VERSION "created by canmatrix"

NS_ :

BS_:

BU_: DiagTool_OBD1 DiwaNXT EBS IRCS MulticII NBM VCM ETS NODE_45 FCCU DICO SGW2 HV_BOX ADCU AEBS DTCO MBMS SGW TPMS ACU CAID2 ELC5_Fr ELC5_Rr PredictiveVirtualNode2 BPU_3 Servo_dir_Turolla PCM NODE_90 NODE_91 NODE_92 RSRRM FCU DSE_VirtualNode2 DSE_VirtualNode40 DSE_VirtualNode38 DSE_VirtualNode49 DSE_VirtualNode48 DSE_VirtualNode39 DSE_VirtualNode37 DSE_VirtualNode36 BSM_B8 BPU_2 DSE_VirtualNode35 DSE_VirtualNode34 RADAR_ACC DSE_VirtualNode33 DSE_VirtualNode41 NODE_BE DSE_VirtualNode32 DSE_VirtualNode4 BSM_C0 BPU_1 DSE_VirtualNode31 DSE_VirtualNode29 DSE_VirtualNode28 MCDS DSE_VirtualNode44 DSE_VirtualNode27 DSE_VirtualNode26 BSM_C8 ALM DSE_VirtualNode25 DSE_VirtualNode50 DSE_VirtualNode47 DSE_VirtualNode46 DSE_VirtualNode23 DSE_VirtualNode51 ScanTool DSE_VirtualNode22 DSE_VirtualNode21 AePTO DC_VirtualNode1 DSE_VirtualNode43 MCSL DSE_VirtualNode1 DSE_VirtualNode42 PredictiveVirtualNode3 DSE_VirtualNode20 DSE_VirtualNode19 DSE_VirtualNode18 DSE_VirtualNode17 DSE_VirtualNode16 DSE_VirtualNode15 NODE_F9 DiagTool DSE_VirtualNode14 DSE_VirtualNode13 DSE_VirtualNode12 DSE_VirtualNode11 DSE_VirtualNode10 DSE_VirtualNode9 DSE_VirtualNode8 DSE_VirtualNode7 DSE_VirtualNode6 Mirror DSE_VirtualNode5 SAS DC_VirtualNode2 PredictiveVirtualNode1 DSE_VirtualNode45 ELFA3 EM_PTO RM CANAIR SWI

BO_ 2566725632 A1DOC1: 8 DiagTool_OBD1
 SG_ At1DocInTemp : 0|16@1+ (0.03125,-273) [-273|1734] "°C"  PCM

BO_ 2565874432 A1SCRDSI1: 8 DiagTool_OBD1
 SG_ At1DefActDosQty : 0|16@1+ (0.3,0) [0|19276] "g/h"  PCM

BO_ 2499624448 A1SCREGT1: 8 DiagTool_OBD1
 SG_ At1ScrInTemp : 0|16@1+ (0.03125,-273) [-273|1734] "°C"  PCM
 SG_ At1ScrOutTemp : 24|16@1+ (0.03125,-273) [-273|1734] "°C"  PCM

BO_ 2566811431 ACC1_27: 8 VCM
 SG_ AccMode : 24|3@1+ (1,0) [0|7] ""  PCM
 SG_ AccSetDistMode : 27|3@1+ (1,0) [0|7] ""  PCM

BO_ 2566803735 ACC2_17: 8 MulticII
 SG_ AccUseDem : 0|2@1+ (1,0) [0|3] ""  PCM

BO_ 2565406464 ACKM_00: 8 DiagTool_OBD1
 SG_ CtrlByte_Ackm M : 0|8@1+ (1,0) [0|255] "binary"  PCM
 SG_ Pgn_Ack m0 : 40|24@1+ (1,0) [0|16777215] "binary"  PCM
 SG_ Pgn_Nack m1 : 40|24@1+ (1,0) [0|16777215] "binary"  PCM
 SG_ Pgn_Ad m2 : 40|24@1+ (1,0) [0|16777215] "binary"  PCM
 SG_ Pgn_Busy m3 : 40|24@1+ (1,0) [0|16777215] "binary"  PCM

BO_ 2565406467 ACKM_03: 8 DiwaNXT
 SG_ CtrlByte_Ackm_18E8FF03 M : 0|8@1+ (1,0) [0|255] "binary"  PCM
 SG_ Pgn_Ack_18E8FF03 m0 : 40|24@1+ (1,0) [0|16777215] "binary"  PCM
 SG_ Pgn_Nack_18E8FF03 m1 : 40|24@1+ (1,0) [0|16777215] "binary"  PCM
 SG_ Pgn_Ad_18E8FF03 m2 : 40|24@1+ (1,0) [0|16777215] "binary"  PCM
 SG_ Pgn_Busy_18E8FF03 m3 : 40|24@1+ (1,0) [0|16777215] "binary"  PCM

BO_ 2565406475 ACKM_0B: 8 EBS
 SG_ CtrlByte_Ackm_18E8FF0B M : 0|8@1+ (1,0) [0|255] "binary"  PCM
 SG_ Pgn_Ack_18E8FF0B m0 : 40|24@1+ (1,0) [0|16777215] "binary"  PCM
 SG_ Pgn_Nack_18E8FF0B m1 : 40|24@1+ (1,0) [0|16777215] "binary"  PCM
 SG_ Pgn_Ad_18E8FF0B m2 : 40|24@1+ (1,0) [0|16777215] "binary"  PCM
 SG_ Pgn_Busy_18E8FF0B m3 : 40|24@1+ (1,0) [0|16777215] "binary"  PCM

BO_ 2565406487 ACKM_17: 8 MulticII
 SG_ CtrlByte_Ackm_18E8FF17 M : 0|8@1+ (1,0) [0|255] "binary"  PCM
 SG_ Pgn_Ack_18E8FF17 m0 : 40|24@1+ (1,0) [0|16777215] "binary"  PCM
 SG_ Pgn_Nack_18E8FF17 m1 : 40|24@1+ (1,0) [0|16777215] "binary"  PCM
 SG_ Pgn_Ad_18E8FF17 m2 : 40|24@1+ (1,0) [0|16777215] "binary"  PCM
 SG_ Pgn_Busy_18E8FF17 m3 : 40|24@1+ (1,0) [0|16777215] "binary"  PCM

BO_ 2565406492 ACKM_1C: 8 PCM
 SG_ CtrlByte_Ackm_18E8FF1C M : 0|8@1+ (1,0) [0|255] "binary" Vector__XXX
 SG_ AddrAckd m0 : 32|8@1+ (1,0) [0|255] "" Vector__XXX
 SG_ AddrNack m1 : 32|8@1+ (1,0) [0|255] "" Vector__XXX
 SG_ AddrAccessDenied m2 : 32|8@1+ (1,0) [0|255] "" Vector__XXX
 SG_ AddrBusy m3 : 32|8@1+ (1,0) [0|255] "" Vector__XXX
 SG_ Pgn_Ack_18E8FF1C m0 : 40|24@1+ (1,0) [0|16777215] "binary" Vector__XXX
 SG_ Pgn_Nack_18E8FF1C m1 : 40|24@1+ (1,0) [0|16777215] "binary" Vector__XXX
 SG_ Pgn_Ad_18E8FF1C m2 : 40|24@1+ (1,0) [0|16777215] "binary" Vector__XXX
 SG_ Pgn_Busy_18E8FF1C m3 : 40|24@1+ (1,0) [0|16777215] "binary" Vector__XXX

BO_ 2565406493 ACKM_1D: 8 SGW
 SG_ CtrlByte_Ackm_18E8FF1D M : 0|8@1+ (1,0) [0|255] "binary"  PCM
 SG_ AddrAckd_18E8FF1D m0 : 32|8@1+ (1,0) [0|255] ""  PCM
 SG_ AddrNack_18E8FF1D m1 : 32|8@1+ (1,0) [0|255] ""  PCM
 SG_ AddrAccessDenied_18E8FF1D m2 : 32|8@1+ (1,0) [0|255] ""  PCM
 SG_ AddrBusy_18E8FF1D m3 : 32|8@1+ (1,0) [0|255] ""  PCM
 SG_ Pgn_Ack_18E8FF1D m0 : 40|24@1+ (1,0) [0|16777215] "binary"  PCM
 SG_ Pgn_Nack_18E8FF1D m1 : 40|24@1+ (1,0) [0|16777215] "binary"  PCM
 SG_ Pgn_Ad_18E8FF1D m2 : 40|24@1+ (1,0) [0|16777215] "binary"  PCM
 SG_ Pgn_Busy_18E8FF1D m3 : 40|24@1+ (1,0) [0|16777215] "binary"  PCM

BO_ 2565406503 ACKM_27: 8 VCM
 SG_ CtrlByte_Ackm_18E8FF27 M : 0|8@1+ (1,0) [0|255] "binary"  PCM
 SG_ Pgn_Ack_18E8FF27 m0 : 40|24@1+ (1,0) [0|16777215] "binary"  PCM
 SG_ Pgn_Nack_18E8FF27 m1 : 40|24@1+ (1,0) [0|16777215] "binary"  PCM
 SG_ Pgn_Ad_18E8FF27 m2 : 40|24@1+ (1,0) [0|16777215] "binary"  PCM
 SG_ Pgn_Busy_18E8FF27 m3 : 40|24@1+ (1,0) [0|16777215] "binary"  PCM

BO_ 2565406515 ACKM_33: 8 TPMS
 SG_ CtrlByte_Ackm_18E8FF33 M : 0|8@1+ (1,0) [0|255] "binary"  PCM
 SG_ Pgn_Ack_18E8FF33 m0 : 40|24@1+ (1,0) [0|16777215] "binary"  PCM
 SG_ Pgn_Nack_18E8FF33 m1 : 40|24@1+ (1,0) [0|16777215] "binary"  PCM
 SG_ Pgn_Ad_18E8FF33 m2 : 40|24@1+ (1,0) [0|16777215] "binary"  PCM
 SG_ Pgn_Busy_18E8FF33 m3 : 40|24@1+ (1,0) [0|16777215] "binary"  PCM

BO_ 2565406520 ACKM_38: 8 ETS
 SG_ CtrlByte_Ackm_18E8FF38 M : 0|8@1+ (1,0) [0|255] "binary"  PCM
 SG_ Pgn_Ack_18E8FF38 m0 : 40|24@1+ (1,0) [0|16777215] "binary"  PCM
 SG_ Pgn_Nack_18E8FF38 m1 : 40|24@1+ (1,0) [0|16777215] "binary"  PCM
 SG_ Pgn_Ad_18E8FF38 m2 : 40|24@1+ (1,0) [0|16777215] "binary"  PCM
 SG_ Pgn_Busy_18E8FF38 m3 : 40|24@1+ (1,0) [0|16777215] "binary"  PCM

BO_ 2565406590 ACKM_7E: 8 SGW2
 SG_ CtrlByte_Ackm_18E8FF7E M : 0|8@1+ (1,0) [0|255] "binary"  PCM
 SG_ Pgn_Ack_18E8FF7E m0 : 40|24@1+ (1,0) [0|16777215] "binary"  PCM
 SG_ Pgn_Nack_18E8FF7E m1 : 40|24@1+ (1,0) [0|16777215] "binary"  PCM
 SG_ Pgn_Ad_18E8FF7E m2 : 40|24@1+ (1,0) [0|16777215] "binary"  PCM
 SG_ Pgn_Busy_18E8FF7E m3 : 40|24@1+ (1,0) [0|16777215] "binary"  PCM

BO_ 2565406622 ACKM_9E: 8 ADCU
 SG_ CtrlByte_Ackm_18E8FF9E M : 0|8@1+ (1,0) [0|255] "binary"  PCM
 SG_ Pgn_Ack_18E8FF9E m0 : 40|24@1+ (1,0) [0|16777215] "binary"  PCM
 SG_ Pgn_Nack_18E8FF9E m1 : 40|24@1+ (1,0) [0|16777215] "binary"  PCM
 SG_ Pgn_Ad_18E8FF9E m2 : 40|24@1+ (1,0) [0|16777215] "binary"  PCM
 SG_ Pgn_Busy_18E8FF9E m3 : 40|24@1+ (1,0) [0|16777215] "binary"  PCM

BO_ 2565406624 ACKM_A0: 8 AEBS
 SG_ CtrlByte_Ackm_18E8FFA0 M : 0|8@1+ (1,0) [0|255] "binary"  PCM
 SG_ Pgn_Ack_18E8FFA0 m0 : 40|24@1+ (1,0) [0|16777215] "binary"  PCM
 SG_ Pgn_Nack_18E8FFA0 m1 : 40|24@1+ (1,0) [0|16777215] "binary"  PCM
 SG_ Pgn_Ad_18E8FFA0 m2 : 40|24@1+ (1,0) [0|16777215] "binary"  PCM
 SG_ Pgn_Busy_18E8FFA0 m3 : 40|24@1+ (1,0) [0|16777215] "binary"  PCM

BO_ 2565406702 ACKM_EE: 8 DTCO
 SG_ CtrlByte_Ackm_18E8FFEE M : 0|8@1+ (1,0) [0|255] "binary"  PCM
 SG_ Pgn_Ack_18E8FFEE m0 : 40|24@1+ (1,0) [0|16777215] "binary"  PCM
 SG_ Pgn_Nack_18E8FFEE m1 : 40|24@1+ (1,0) [0|16777215] "binary"  PCM
 SG_ Pgn_Ad_18E8FFEE m2 : 40|24@1+ (1,0) [0|16777215] "binary"  PCM
 SG_ Pgn_Busy_18E8FFEE m3 : 40|24@1+ (1,0) [0|16777215] "binary"  PCM

BO_ 2633959399 ACU: 8 ACU
 SG_ FunctLamp : 4|2@1+ (1,0) [0|3] ""  PCM
 SG_ StopLamp : 6|2@1+ (1,0) [0|3] ""  PCM

BO_ 2364551072 AEBS1: 8 AEBS
 SG_ AebsSts : 0|4@1+ (1,0) [0|15] ""  PCM
 SG_ TimeToCollWithRelvObj : 16|8@1+ (0.05,0) [0|12] "s"  PCM

BO_ 2349572119 AEBS2_17_A0: 8 MulticII
 SG_ DrivActvDemForAebs : 0|2@1+ (1,0) [0|3] ""  PCM,AEBS

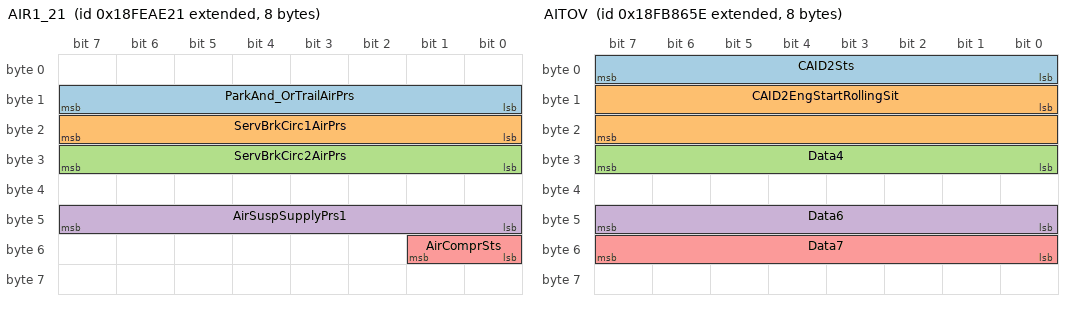
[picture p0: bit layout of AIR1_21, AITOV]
BO_ 2566827553 AIR1_21: 8 NBM
 SG_ ParkAnd_OrTrailAirPrs : 8|8@1+ (8,0) [0|2000] "kPa"  PCM
 SG_ ServBrkCirc1AirPrs : 16|8@1+ (8,0) [0|2000] "kPa"  PCM
 SG_ ServBrkCirc2AirPrs : 24|8@1+ (8,0) [0|2000] "kPa"  PCM
 SG_ AirSuspSupplyPrs1 : 40|8@1+ (8,0) [0|2000] "kPa"  PCM
 SG_ AirComprSts : 48|2@1+ (1,0) [0|3] ""  PCM

BO_ 2566620766 AITOV: 8 CAID2
 SG_ CAID2Sts : 0|8@1+ (1,0) [0|250] ""  PCM
 SG_ CAID2EngStartRollingSit : 8|16@1+ (1,0) [0|64255] ""  PCM
 SG_ Data4 : 24|8@1+ (1,0) [0|250] ""  PCM
 SG_ Data6 : 40|8@1+ (1,0) [0|250] ""  PCM
 SG_ Data7 : 48|8@1+ (1,0) [0|250] ""  PCM

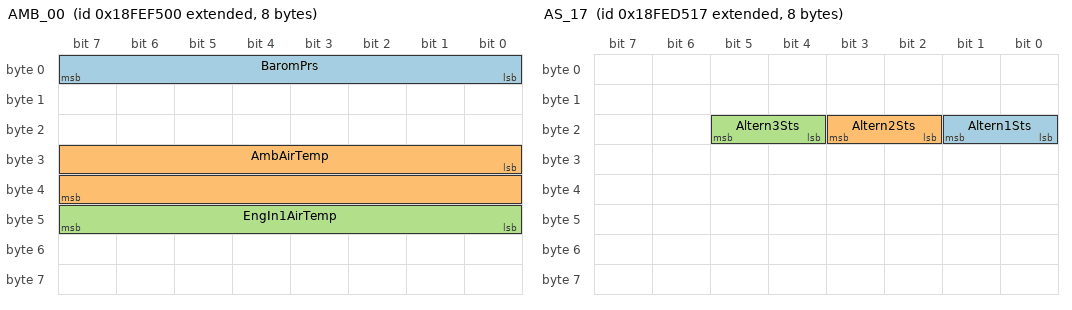
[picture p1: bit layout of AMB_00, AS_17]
BO_ 2566845696 AMB_00: 8 DiagTool_OBD1
 SG_ BaromPrs : 0|8@1+ (0.5,0) [0|125] "kPa"  PCM
 SG_ AmbAirTemp : 24|16@1+ (0.03125,-273) [-273|1734] "°C"  PCM
 SG_ EngIn1AirTemp : 40|8@1+ (1,-40) [-40|210] "°C"  PCM

BO_ 2566845719 AMB_17: 8 MulticII
 SG_ AmbAirTemp_18FEF517 : 24|16@1+ (0.03125,-273) [-273|1734] "°C"  PCM

BO_ 2565920602 API1_O1_STATUS: 8 DICO
 SG_ Dc_AcAccsInv1Freq : 0|8@1+ (1,0) [0|250] "Hz"  PCM

BO_ 2566837527 AS_17: 8 MulticII
 SG_ Altern1Sts : 16|2@1+ (1,0) [0|3] ""  PCM
 SG_ Altern2Sts : 18|2@1+ (1,0) [0|3] ""  PCM
 SG_ Altern3Sts : 20|2@1+ (1,0) [0|3] ""  PCM

BO_ 2365479471 ASC1_A: 8 ELC5_Fr
 SG_ KneelInfo : 24|4@1+ (1,0) [0|15] ""  PCM

BO_ 2365479488 ASC1_B: 8 ELC5_Rr
 SG_ KneelInfo_0CFE5A40 : 24|4@1+ (1,0) [0|15] ""  PCM

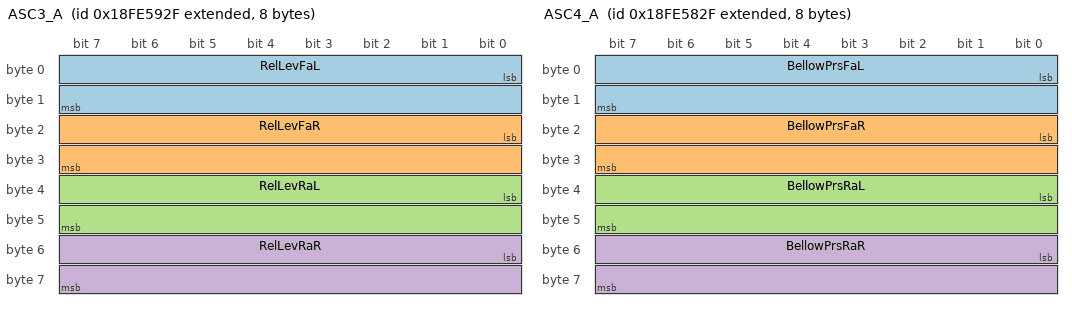
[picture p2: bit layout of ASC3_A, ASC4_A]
BO_ 2566805807 ASC3_A: 8 ELC5_Fr
 SG_ RelLevFaL : 0|16@1+ (0.1,-3200) [-3200|3225] "mm"  PCM
 SG_ RelLevFaR : 16|16@1+ (0.1,-3200) [-3200|3225] "mm"  PCM
 SG_ RelLevRaL : 32|16@1+ (0.1,-3200) [-3200|3225] "mm"  PCM
 SG_ RelLevRaR : 48|16@1+ (0.1,-3200) [-3200|3225] "mm"  PCM

BO_ 2566805824 ASC3_B: 8 ELC5_Rr
 SG_ RelLevRaR_18FE5940 : 48|16@1+ (0.1,-3200) [-3200|3225] "mm"  PCM
 SG_ RelLevRaL_18FE5940 : 32|16@1+ (0.1,-3200) [-3200|3225] "mm"  PCM

BO_ 2566805551 ASC4_A: 8 ELC5_Fr
 SG_ BellowPrsFaL : 0|16@1+ (0.1,0) [0|6425] "kPa"  PCM
 SG_ BellowPrsFaR : 16|16@1+ (0.1,0) [0|6425] "kPa"  PCM
 SG_ BellowPrsRaL : 32|16@1+ (0.1,0) [0|6425] "kPa"  PCM
 SG_ BellowPrsRaR : 48|16@1+ (0.1,0) [0|6425] "kPa"  PCM

BO_ 2566805568 ASC4_B: 8 ELC5_Rr
 SG_ BellowPrsRaL_18FE5840 : 32|16@1+ (0.1,0) [0|6425] "kPa"  PCM
 SG_ BellowPrsRaR_18FE5840 : 48|16@1+ (0.1,0) [0|6425] "kPa"  PCM

BO_ 2566763520 AT1IG2: 8 DiagTool_OBD1
 SG_ At1DpfInTemp : 16|16@1+ (0.03125,-273) [-273|1734] "°C"  PCM

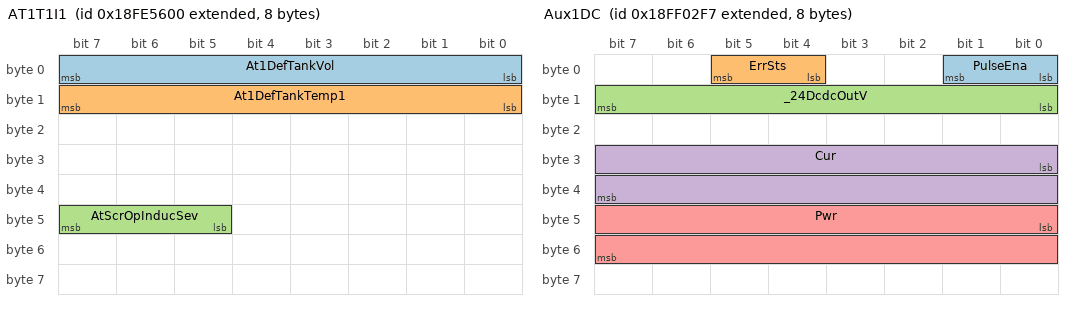
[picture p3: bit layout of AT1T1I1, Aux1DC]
BO_ 2566804992 AT1T1I1: 8 DiagTool_OBD1
 SG_ At1DefTankVol : 0|8@1+ (0.4,0) [0|100] "%"  PCM
 SG_ At1DefTankTemp1 : 8|8@1+ (1,-40) [-40|210] "°C"  PCM
 SG_ AtScrOpInducSev : 45|3@1+ (1,0) [0|7] ""  PCM

BO_ 2566849271 Aux1DC: 8 PredictiveVirtualNode2
 SG_ PulseEna : 0|2@1+ (1,0) [0|3] ""  PCM
 SG_ ErrSts : 4|2@1+ (1,0) [0|3] ""  PCM
 SG_ _24DcdcOutV : 8|8@1+ (0.2,0) [0|50] "V"  PCM
 SG_ Cur : 24|16@1+ (0.05,-1600) [-1600|1612] "A"  PCM
 SG_ Pwr : 40|16@1+ (0.005,-160) [-160|161] "Kw"  PCM

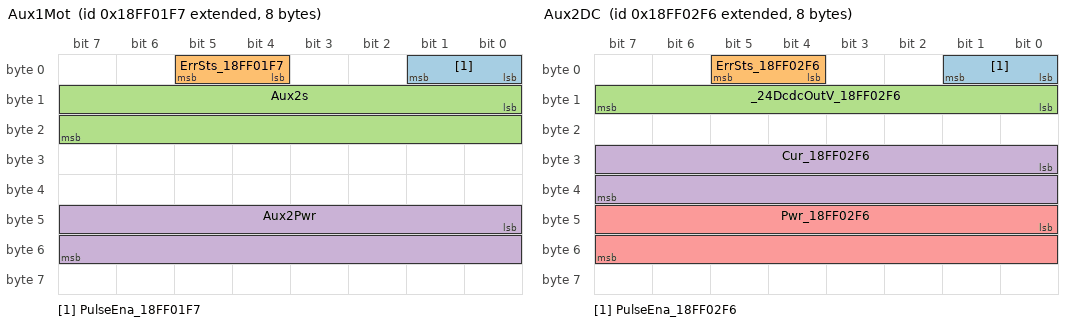
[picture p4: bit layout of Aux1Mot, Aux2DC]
BO_ 2566849015 Aux1Mot: 8 PredictiveVirtualNode2
 SG_ PulseEna_18FF01F7 : 0|2@1+ (1,0) [0|3] ""  PCM
 SG_ ErrSts_18FF01F7 : 4|2@1+ (1,0) [0|3] ""  PCM
 SG_ Aux2s : 8|16@1+ (1,-32127) [-32127|32128] "rpm"  PCM
 SG_ Aux2Pwr : 40|16@1+ (0.005,-160) [-160|161] "Kw"  PCM

BO_ 2566848759 Aux1St: 8 PredictiveVirtualNode2
 SG_ Term15Sts : 8|2@1+ (1,0) [0|3] ""  PCM
 SG_ DcLinkV : 32|8@1+ (4,0) [0|1000] "V"  PCM

BO_ 2566849270 Aux2DC: 8 BPU_3
 SG_ PulseEna_18FF02F6 : 0|2@1+ (1,0) [0|3] ""  PCM
 SG_ ErrSts_18FF02F6 : 4|2@1+ (1,0) [0|3] ""  PCM
 SG_ _24DcdcOutV_18FF02F6 : 8|8@1+ (0.2,0) [0|50] "V"  PCM
 SG_ Cur_18FF02F6 : 24|16@1+ (0.05,-1600) [-1600|1612] "A"  PCM
 SG_ Pwr_18FF02F6 : 40|16@1+ (0.005,-160) [-160|161] "Kw"  PCM

CM_ BO_ 2566725632 "- CUC.C.PCM..3..TELEM: FPT request - Diesel vehicle only";
CM_ BO_ 2565874432 "- Diesel vehicle only";
CM_ BO_ 2499624448 "- CUC.C.PCM..3..TELEM: FPT request - Diesel vehicle only";
CM_ BO_ 2566811431 "- Only if ACC option is enabled";
CM_ BO_ 2566803735 "- Only if ACC option is enabled.
-  VCM VDB File: For bus both signals are in ACC2_17.
- s.Ib..24.work.TELEM: Telem FE: In acccording with NGT file";
CM_ BO_ 2565406464 "- NACK required as a response to a destination specific request that cannot be served, ACK/NACK not permitted for a global request (SAE J1939/21).
-  Negative ACK MD1 to ALL.";
CM_ SG_ 2565406464 Pgn_Ack "- Value Table filled with the most commonly used PGNs in Iveco applications, ECU implementation may differ";
CM_ SG_ 2565406464 Pgn_Nack "- Value Table filled with the most commonly used PGNs in Iveco applications, ECU implementation may differ";
CM_ SG_ 2565406464 Pgn_Ad "- Value Table filled with the most commonly used PGNs in Iveco applications, ECU implementation may differ";
CM_ SG_ 2565406464 Pgn_Busy "- Value Table filled with the most commonly used PGNs in Iveco applications, ECU implementation may differ";
CM_ BO_ 2565406467 "- NACK required as a response to a destination specific request that cannot be served, ACK/NACK not permitted for a global request (SAE J1939/21).
-  Negative ACK Gearbox to ALL.";
CM_ SG_ 2565406467 Pgn_Ack_18E8FF03 "- Value Table filled with the most commonly used PGNs in Iveco applications, ECU implementation may differ";
CM_ SG_ 2565406467 Pgn_Nack_18E8FF03 "- Value Table filled with the most commonly used PGNs in Iveco applications, ECU implementation may differ";
CM_ SG_ 2565406467 Pgn_Ad_18E8FF03 "- Value Table filled with the most commonly used PGNs in Iveco applications, ECU implementation may differ";
CM_ SG_ 2565406467 Pgn_Busy_18E8FF03 "- Value Table filled with the most commonly used PGNs in Iveco applications, ECU implementation may differ";
CM_ BO_ 2565406475 "- NACK required as a response to a destination specific request that cannot be served, ACK/NACK not permitted for a global request (SAE J1939/21).
-  Negative ACK EBS to ALL.";
CM_ SG_ 2565406475 Pgn_Ack_18E8FF0B "- Value Table filled with the most commonly used PGNs in Iveco applications, ECU implementation may differ";
CM_ SG_ 2565406475 Pgn_Nack_18E8FF0B "- Value Table filled with the most commonly used PGNs in Iveco applications, ECU implementation may differ";
CM_ SG_ 2565406475 Pgn_Ad_18E8FF0B "- Value Table filled with the most commonly used PGNs in Iveco applications, ECU implementation may differ";
CM_ SG_ 2565406475 Pgn_Busy_18E8FF0B "- Value Table filled with the most commonly used PGNs in Iveco applications, ECU implementation may differ";
CM_ BO_ 2565406487 "- NACK required as a response to a destination specific request that cannot be served, ACK/NACK not permitted for a global request (SAE J1939/21).
-  Negative ACK IC to ALL.";
CM_ SG_ 2565406487 Pgn_Ack_18E8FF17 "- Value Table filled with the most commonly used PGNs in Iveco applications, ECU implementation may differ";
CM_ SG_ 2565406487 Pgn_Nack_18E8FF17 "- Value Table filled with the most commonly used PGNs in Iveco applications, ECU implementation may differ";
CM_ SG_ 2565406487 Pgn_Ad_18E8FF17 "- Value Table filled with the most commonly used PGNs in Iveco applications, ECU implementation may differ";
CM_ SG_ 2565406487 Pgn_Busy_18E8FF17 "- Value Table filled with the most commonly used PGNs in Iveco applications, ECU implementation may differ";
CM_ BO_ 2565406492 "- NACK required as a response to a destination specific request that cannot be served, ACK/NACK not permitted for a global request (SAE J1939/21).
-  Negative ACK eHorizon to ALL.";
CM_ SG_ 2565406492 Pgn_Ack_18E8FF1C "- Value Table filled with the most commonly used PGNs in Iveco applications, ECU implementation may differ";
CM_ SG_ 2565406492 Pgn_Nack_18E8FF1C "- Value Table filled with the most commonly used PGNs in Iveco applications, ECU implementation may differ";
CM_ SG_ 2565406492 Pgn_Ad_18E8FF1C "- Value Table filled with the most commonly used PGNs in Iveco applications, ECU implementation may differ";
CM_ SG_ 2565406492 Pgn_Busy_18E8FF1C "- Value Table filled with the most commonly used PGNs in Iveco applications, ECU implementation may differ";
CM_ BO_ 2565406493 "- NACK required as a response to a destination specific request that cannot be served, ACK/NACK not permitted for a global request (SAE J1939/21).
-  Negative ACK SGW1 to ALL.";
CM_ SG_ 2565406493 Pgn_Ack_18E8FF1D "- Value Table filled with the most commonly used PGNs in Iveco applications, ECU implementation may differ";
CM_ SG_ 2565406493 Pgn_Nack_18E8FF1D "- Value Table filled with the most commonly used PGNs in Iveco applications, ECU implementation may differ";
CM_ SG_ 2565406493 Pgn_Ad_18E8FF1D "- Value Table filled with the most commonly used PGNs in Iveco applications, ECU implementation may differ";
CM_ SG_ 2565406493 Pgn_Busy_18E8FF1D "- Value Table filled with the most commonly used PGNs in Iveco applications, ECU implementation may differ";
CM_ BO_ 2565406503 "- NACK required as a response to a destination specific request that cannot be served, ACK/NACK not permitted for a global request (SAE J1939/21).
-  Negative ACK VCM4 to ALL.";
CM_ SG_ 2565406503 Pgn_Ack_18E8FF27 "- Value Table filled with the most commonly used PGNs in Iveco applications, ECU implementation may differ";
CM_ SG_ 2565406503 Pgn_Nack_18E8FF27 "- Value Table filled with the most commonly used PGNs in Iveco applications, ECU implementation may differ";
CM_ SG_ 2565406503 Pgn_Ad_18E8FF27 "- Value Table filled with the most commonly used PGNs in Iveco applications, ECU implementation may differ";
CM_ SG_ 2565406503 Pgn_Busy_18E8FF27 "- Value Table filled with the most commonly used PGNs in Iveco applications, ECU implementation may differ";
CM_ BO_ 2565406515 "- NACK required as a response to a destination specific request that cannot be served, ACK/NACK not permitted for a global request (SAE J1939/21).
-  Negative ACK TPMS to ALL.";
CM_ SG_ 2565406515 Pgn_Ack_18E8FF33 "- Value Table filled with the most commonly used PGNs in Iveco applications, ECU implementation may differ";
CM_ SG_ 2565406515 Pgn_Nack_18E8FF33 "- Value Table filled with the most commonly used PGNs in Iveco applications, ECU implementation may differ";
CM_ SG_ 2565406515 Pgn_Ad_18E8FF33 "- Value Table filled with the most commonly used PGNs in Iveco applications, ECU implementation may differ";
CM_ SG_ 2565406515 Pgn_Busy_18E8FF33 "- Value Table filled with the most commonly used PGNs in Iveco applications, ECU implementation may differ";
CM_ BO_ 2565406520 "- Negative ACK ETS to ALL. NACK required as a response to a destination specific request that cannot be served, ACK/NACK not permitted for a global request (SAE J1939/21).
-  Only CW Diesel.";
CM_ SG_ 2565406520 Pgn_Ack_18E8FF38 "- Value Table filled with the most commonly used PGNs in Iveco applications, ECU implementation may differ";
CM_ SG_ 2565406520 Pgn_Nack_18E8FF38 "- Value Table filled with the most commonly used PGNs in Iveco applications, ECU implementation may differ";
CM_ SG_ 2565406520 Pgn_Ad_18E8FF38 "- Value Table filled with the most commonly used PGNs in Iveco applications, ECU implementation may differ";
CM_ SG_ 2565406520 Pgn_Busy_18E8FF38 "- Value Table filled with the most commonly used PGNs in Iveco applications, ECU implementation may differ";
CM_ BO_ 2565406590 "- NACK required as a response to a destination specific request that cannot be served, ACK/NACK not permitted for a global request (SAE J1939/21).
-  Negative ACK SGW2 to ALL.";
CM_ SG_ 2565406590 Pgn_Ack_18E8FF7E "- Value Table filled with the most commonly used PGNs in Iveco applications, ECU implementation may differ";
CM_ SG_ 2565406590 Pgn_Nack_18E8FF7E "- Value Table filled with the most commonly used PGNs in Iveco applications, ECU implementation may differ";
CM_ SG_ 2565406590 Pgn_Ad_18E8FF7E "- Value Table filled with the most commonly used PGNs in Iveco applications, ECU implementation may differ";
CM_ SG_ 2565406590 Pgn_Busy_18E8FF7E "- Value Table filled with the most commonly used PGNs in Iveco applications, ECU implementation may differ";
CM_ BO_ 2565406622 "- NACK required as a response to a destination specific request that cannot be served, ACK/NACK not permitted for a global request (SAE J1939/21).
-  Negative ACK ADCU to ALL.";
CM_ SG_ 2565406622 Pgn_Ack_18E8FF9E "- Value Table filled with the most commonly used PGNs in Iveco applications, ECU implementation may differ";
CM_ SG_ 2565406622 Pgn_Nack_18E8FF9E "- Value Table filled with the most commonly used PGNs in Iveco applications, ECU implementation may differ";
CM_ SG_ 2565406622 Pgn_Ad_18E8FF9E "- Value Table filled with the most commonly used PGNs in Iveco applications, ECU implementation may differ";
CM_ SG_ 2565406622 Pgn_Busy_18E8FF9E "- Value Table filled with the most commonly used PGNs in Iveco applications, ECU implementation may differ";
CM_ BO_ 2565406624 "- NACK required as a response to a destination specific request that cannot be served, ACK/NACK not permitted for a global request (SAE J1939/21).
-  Negative ACK ADCU (AEBS) to ALL.
-  SA=0xA0_ ECU Sender is MRGen21 (CAN RADAR)";
CM_ SG_ 2565406624 Pgn_Ack_18E8FFA0 "- Value Table filled with the most commonly used PGNs in Iveco applications, ECU implementation may differ";
CM_ SG_ 2565406624 Pgn_Nack_18E8FFA0 "- Value Table filled with the most commonly used PGNs in Iveco applications, ECU implementation may differ";
CM_ SG_ 2565406624 Pgn_Ad_18E8FFA0 "- Value Table filled with the most commonly used PGNs in Iveco applications, ECU implementation may differ";
CM_ SG_ 2565406624 Pgn_Busy_18E8FFA0 "- Value Table filled with the most commonly used PGNs in Iveco applications, ECU implementation may differ";
CM_ BO_ 2565406702 "- NACK required as a response to a destination specific request that cannot be served, ACK/NACK not permitted for a global request (SAE J1939/21).
-  Negative ACK Tacho to ALL.";
CM_ SG_ 2565406702 Pgn_Ack_18E8FFEE "- Value Table filled with the most commonly used PGNs in Iveco applications, ECU implementation may differ";
CM_ SG_ 2565406702 Pgn_Nack_18E8FFEE "- Value Table filled with the most commonly used PGNs in Iveco applications, ECU implementation may differ";
CM_ SG_ 2565406702 Pgn_Ad_18E8FFEE "- Value Table filled with the most commonly used PGNs in Iveco applications, ECU implementation may differ";
CM_ SG_ 2565406702 Pgn_Busy_18E8FFEE "- Value Table filled with the most commonly used PGNs in Iveco applications, ECU implementation may differ";
CM_ BO_ 2633959399 "- 18m only.
-  In some applications used: Priority 6 (Id message 18 FF 07 E7)";
CM_ BO_ 2364551072 "- ICE bus only_ For vehicle with AEBS only (CW only)
-  SA=0xA0_ ECU Sender is MRGen21 (CAN RADAR).";
CM_ SG_ 2364551072 TimeToCollWithRelvObj "- 1=20ms";
CM_ BO_ 2349572119 "- DA=0xA0_ MRGen21 (CAN RADAR).
-  ICE CW bus only";
CM_ BO_ 2566827553 "- MC.W.VCM.4.24..VDB: Transmission rate: 1000/On change";
CM_ SG_ 2566827553 AirSuspSupplyPrs1 "- Set to FF (not available)";
CM_ SG_ 2566827553 AirComprSts "- NBM send to FF";
CM_ SG_ 2566620766 Data6 "- Vehicle Status according to 50436-4:2020";
CM_ BO_ 2566845696 "- Ambient air temperature signal set not available (0xFFFF) in some AMB_00 VDB version hence EDB version is preferred.
-  Not present with Microvast batteries.";
CM_ SG_ 2566845696 BaromPrs "- FEh in case of defective sensor";
CM_ SG_ 2566845696 AmbAirTemp "- Data not transfered by VCM_ set to 0xFFFF";
CM_ SG_ 2566845696 EngIn1AirTemp "- Not evaluated by ECM (FFh)";
CM_ BO_ 2566845719 "- GX: Multic2 is Sender ECU.
-  Intercity: Only ambient temperature is provided by SPR1 instrument cluster.
-  UW: NBM is Sender ECU.";
CM_ BO_ 2565920602 "- Elec Siemens message available only.";
CM_ SG_ 2565920602 Dc_AcAccsInv1Freq "- Signal to the Accessory Power Inverter frequency of the attached accessory, Corresponds to 100% Frequency Percentage Command parameter";
CM_ BO_ 2566837527 "- Used RATP.";
CM_ BO_ 2365479488 "- From Articulated bus Dolly";
CM_ BO_ 2566805807 "- The message contains relative levels (in millimeters) to the nominal ride height (Normal level).";
CM_ BO_ 2566805824 "- From Articulated bus Dolly";
CM_ BO_ 2566805551 "- The message contains actual air bellow pressures in kilopascals (KPa) based on the pressure sensor  installed in the bellows.
- CUC.C.PCM..3..TELEM: : DSE Fonctionnement
- OVG.Mtx.FMS.4.24.Generic.FMSi: if option";
CM_ BO_ 2566805568 "- Specific RATP. PCM3: DSE Fonctionnement";
CM_ BO_ 2566763520 "- FPT request - Only for Diesel vehicles";
CM_ SG_ 2566763520 At1DpfInTemp "- The maximum value is 1734,96875 (not 1735).";
CM_ BO_ 2566804992 "- Diesel vehicle only";
CM_ BO_ 2566849271 "- Specific to Siemens Full Elec vehicles. DC DC 24V (main). Only Elfa2.";
CM_ BO_ 2566849015 "- Specific to Siemens Full Elec vehicles. Air compressor. Only Elfa2.";
CM_ BO_ 2566848759 "- Specific to Siemens Full Elec vehicles. Air compressor. Only Elfa2.";
CM_ BO_ 2566849270 "- Specific to Siemens Full Elec vehicles. DC DC 24V (secondary). Only Elfa2.";
BA_DEF_ BO_  "CI_MsgDefinition" STRING ;
BA_DEF_ BO_  "CI_MsgId" INT 0 2147483647;
BA_DEF_ BO_  "CI_MsgName" STRING ;
BA_DEF_ BO_  "GenMsgCycleTime" INT 0 3600000;
BA_DEF_ BO_  "GenMsgCycleTimeFast" INT 0 3600000;
BA_DEF_ BO_  "GenMsgDelayTime" INT 0 3600000;
BA_DEF_ BO_  "GenMsgILSupport" ENUM  "No","Yes";
BA_DEF_ BO_  "GenMsgNrOfRepetition" INT 0 1000000;
BA_DEF_ BO_  "GenMsgRequestable" INT 0 1;
BA_DEF_ BO_  "GenMsgSendType" ENUM  "cyclic","NotUsed","NotUsed","NotUsed","NotUsed","NotUsed","NotUsed","IfActive","noMsgSendType";
BA_DEF_ BO_  "GenMsgStartDelayTime" INT 0 100000;
BA_DEF_ BO_  "J1939PgAppearanceOnBus" ENUM  "Default","CAN_Extended","CANFD_Extended";
BA_DEF_ BO_  "TpJ1939VarDlc" ENUM  "No","Yes";
BA_DEF_ BO_  "VFrameFormat" ENUM  "StandardCAN","ExtendedCAN","reserved","J1939PG";
BA_DEF_ SG_  "CI_ParId" STRING ;
BA_DEF_ SG_  "CI_SigId" INT 0 2147483647;
BA_DEF_ SG_  "CI_SigName" STRING ;
BA_DEF_ SG_  "GenSigEVName" STRING ;
BA_DEF_ SG_  "GenSigILSupport" ENUM  "No","Yes";
BA_DEF_ SG_  "GenSigInactiveValue" INT 0 2147483647;
BA_DEF_ SG_  "GenSigSendType" ENUM  "Cyclic","OnWrite","OnWriteWithRepetition","OnChange","OnChangeWithRepetition","IfActive","IfActiveWithRepetition","NoSigSendType";
BA_DEF_ SG_  "GenSigStartValue" INT 0 2147483647;
BA_DEF_ SG_  "GenSigTimeoutTime_ACU" INT 0 3600000;
BA_DEF_ SG_  "GenSigTimeoutTime_ADCU" INT 0 3600000;
BA_DEF_ SG_  "GenSigTimeoutTime_CAID" INT 0 3600000;
BA_DEF_ SG_  "GenSigTimeoutTime_CANAIR" INT 0 3600000;
BA_DEF_ SG_  "GenSigTimeoutTime_DICO" INT 0 3600000;
BA_DEF_ SG_  "GenSigTimeoutTime_DTCO" INT 0 3600000;
BA_DEF_ SG_  "GenSigTimeoutTime_DiwaNXT" INT 0 3600000;
BA_DEF_ SG_  "GenSigTimeoutTime_DiwaNXT_MH" INT 0 3600000;
BA_DEF_ SG_  "GenSigTimeoutTime_EBS" INT 0 3600000;
BA_DEF_ SG_  "GenSigTimeoutTime_EBS_" INT 0 3600000;
BA_DEF_ SG_  "GenSigTimeoutTime_EBS__" INT 0 3600000;
BA_DEF_ SG_  "GenSigTimeoutTime_EBS___" INT 0 3600000;
BA_DEF_ SG_  "GenSigTimeoutTime_ELC5_Fr" INT 0 3600000;
BA_DEF_ SG_  "GenSigTimeoutTime_ELFA3" INT 0 3600000;
BA_DEF_ SG_  "GenSigTimeoutTime_ETS" INT 0 3600000;
BA_DEF_ SG_  "GenSigTimeoutTime_Ecolife2" INT 0 3600000;
BA_DEF_ SG_  "GenSigTimeoutTime_FCCU_" INT 0 3600000;
BA_DEF_ SG_  "GenSigTimeoutTime_FMS4" INT 0 3600000;
BA_DEF_ SG_  "GenSigTimeoutTime_HV_BOX" INT 0 3600000;
BA_DEF_ SG_  "GenSigTimeoutTime_INTD" INT 0 3600000;
BA_DEF_ SG_  "GenSigTimeoutTime_IRCS" INT 0 3600000;
BA_DEF_ SG_  "GenSigTimeoutTime_MD1_D" INT 0 3600000;
BA_DEF_ SG_  "GenSigTimeoutTime_MD1_G" INT 0 3600000;
BA_DEF_ SG_  "GenSigTimeoutTime_MTCO" INT 0 3600000;
BA_DEF_ SG_  "GenSigTimeoutTime_MulticII" INT 0 3600000;
BA_DEF_ SG_  "GenSigTimeoutTime_MulticS" INT 0 3600000;
BA_DEF_ SG_  "GenSigTimeoutTime_MulticS_" INT 0 3600000;
BA_DEF_ SG_  "GenSigTimeoutTime_MulticS__" INT 0 3600000;
BA_DEF_ SG_  "GenSigTimeoutTime_NBM" INT 0 3600000;
BA_DEF_ SG_  "GenSigTimeoutTime_NBM_" INT 0 3600000;
BA_DEF_ SG_  "GenSigTimeoutTime_NBM__" INT 0 3600000;
BA_DEF_ SG_  "GenSigTimeoutTime_NBM___" INT 0 3600000;
BA_DEF_ SG_  "GenSigTimeoutTime_PCM" INT 0 3600000;
BA_DEF_ SG_  "GenSigTimeoutTime_SGW" INT 0 3600000;
BA_DEF_ SG_  "GenSigTimeoutTime_SGW2" INT 0 3600000;
BA_DEF_ SG_  "GenSigTimeoutTime_SGW_" INT 0 3600000;
BA_DEF_ SG_  "GenSigTimeoutTime_SGW__" INT 0 3600000;
BA_DEF_ SG_  "GenSigTimeoutTime_SIU" INT 0 3600000;
BA_DEF_ SG_  "GenSigTimeoutTime_SmartRadio" INT 0 3600000;
BA_DEF_ SG_  "GenSigTimeoutTime_TPMS" INT 0 3600000;
BA_DEF_ SG_  "GenSigTimeoutTime_TSU" INT 0 3600000;
BA_DEF_ SG_  "GenSigTimeoutTime_VCM" INT 0 3600000;
BA_DEF_ SG_  "GenSigTimeoutTime_VCM_" INT 0 3600000;
BA_DEF_ SG_  "GenSigTimeoutTime_VCM__" INT 0 3600000;
BA_DEF_ SG_  "GenSigTimeoutTime_VCU" INT 0 3600000;
BA_DEF_ SG_  "GenSigTimeoutTime_VCU_" INT 0 3600000;
BA_DEF_ SG_  "GenSigTimeoutTime_VMU" INT 0 3600000;
BA_DEF_ SG_  "SPN" INT 0 524287;
BA_DEF_ SG_  "SigType" ENUM  "Default","Range","RangeSigned","ASCII","Discrete","Control","ReferencePGN","DTC","StringDelimiter","StringLength","StringLengthControl";
BA_DEF_ BU_  "ILUsed" ENUM  "No","Yes";
BA_DEF_ BU_  "NmStationAddress" INT 0 255;
BA_DEF_ BU_  "NodeLayerModules" STRING ;
BA_DEF_  "Baudrate" INT 0 1000000;
BA_DEF_  "BusType" STRING ;
BA_DEF_  "Manufacturer" STRING ;
BA_DEF_  "ProtocolType" STRING ;
BA_DEF_DEF_  "CI_MsgDefinition" "";
BA_DEF_DEF_  "CI_MsgId" 0;
BA_DEF_DEF_  "CI_MsgName" "";
BA_DEF_DEF_  "GenMsgCycleTime" 0;
BA_DEF_DEF_  "GenMsgCycleTimeFast" 0;
BA_DEF_DEF_  "GenMsgDelayTime" 1;
BA_DEF_DEF_  "GenMsgILSupport" "Yes";
BA_DEF_DEF_  "GenMsgNrOfRepetition" 0;
BA_DEF_DEF_  "GenMsgRequestable" 0;
BA_DEF_DEF_  "GenMsgSendType" "noMsgSendType";
BA_DEF_DEF_  "GenMsgStartDelayTime" 0;
BA_DEF_DEF_  "J1939PgAppearanceOnBus" "Default";
BA_DEF_DEF_  "TpJ1939VarDlc" "No";
BA_DEF_DEF_  "VFrameFormat" "J1939PG";
BA_DEF_DEF_  "CI_ParId" "";
BA_DEF_DEF_  "CI_SigId" 0;
BA_DEF_DEF_  "CI_SigName" "";
BA_DEF_DEF_  "GenSigEVName" "Env@Nodename_@Signame";
BA_DEF_DEF_  "GenSigILSupport" "Yes";
BA_DEF_DEF_  "GenSigInactiveValue" 0;
BA_DEF_DEF_  "GenSigSendType" "NoSigSendType";
BA_DEF_DEF_  "GenSigStartValue" 0;
BA_DEF_DEF_  "GenSigTimeoutTime_ACU" 0;
BA_DEF_DEF_  "GenSigTimeoutTime_ADCU" 0;
BA_DEF_DEF_  "GenSigTimeoutTime_CAID" 0;
BA_DEF_DEF_  "GenSigTimeoutTime_CANAIR" 0;
BA_DEF_DEF_  "GenSigTimeoutTime_DICO" 0;
BA_DEF_DEF_  "GenSigTimeoutTime_DTCO" 0;
BA_DEF_DEF_  "GenSigTimeoutTime_DiwaNXT" 0;
BA_DEF_DEF_  "GenSigTimeoutTime_DiwaNXT_MH" 0;
BA_DEF_DEF_  "GenSigTimeoutTime_EBS" 0;
BA_DEF_DEF_  "GenSigTimeoutTime_EBS_" 0;
BA_DEF_DEF_  "GenSigTimeoutTime_EBS__" 0;
BA_DEF_DEF_  "GenSigTimeoutTime_EBS___" 0;
BA_DEF_DEF_  "GenSigTimeoutTime_ELC5_Fr" 0;
BA_DEF_DEF_  "GenSigTimeoutTime_ELFA3" 0;
BA_DEF_DEF_  "GenSigTimeoutTime_ETS" 0;
BA_DEF_DEF_  "GenSigTimeoutTime_Ecolife2" 0;
BA_DEF_DEF_  "GenSigTimeoutTime_FCCU_" 0;
BA_DEF_DEF_  "GenSigTimeoutTime_FMS4" 0;
BA_DEF_DEF_  "GenSigTimeoutTime_HV_BOX" 0;
BA_DEF_DEF_  "GenSigTimeoutTime_INTD" 0;
BA_DEF_DEF_  "GenSigTimeoutTime_IRCS" 0;
BA_DEF_DEF_  "GenSigTimeoutTime_MD1_D" 0;
BA_DEF_DEF_  "GenSigTimeoutTime_MD1_G" 0;
BA_DEF_DEF_  "GenSigTimeoutTime_MTCO" 0;
BA_DEF_DEF_  "GenSigTimeoutTime_MulticII" 0;
BA_DEF_DEF_  "GenSigTimeoutTime_MulticS" 0;
BA_DEF_DEF_  "GenSigTimeoutTime_MulticS_" 0;
BA_DEF_DEF_  "GenSigTimeoutTime_MulticS__" 0;
BA_DEF_DEF_  "GenSigTimeoutTime_NBM" 0;
BA_DEF_DEF_  "GenSigTimeoutTime_NBM_" 0;
BA_DEF_DEF_  "GenSigTimeoutTime_NBM__" 0;
BA_DEF_DEF_  "GenSigTimeoutTime_NBM___" 0;
BA_DEF_DEF_  "GenSigTimeoutTime_PCM" 0;
BA_DEF_DEF_  "GenSigTimeoutTime_SGW" 0;
BA_DEF_DEF_  "GenSigTimeoutTime_SGW2" 0;
BA_DEF_DEF_  "GenSigTimeoutTime_SGW_" 0;
BA_DEF_DEF_  "GenSigTimeoutTime_SGW__" 0;
BA_DEF_DEF_  "GenSigTimeoutTime_SIU" 0;
BA_DEF_DEF_  "GenSigTimeoutTime_SmartRadio" 0;
BA_DEF_DEF_  "GenSigTimeoutTime_TPMS" 0;
BA_DEF_DEF_  "GenSigTimeoutTime_TSU" 0;
BA_DEF_DEF_  "GenSigTimeoutTime_VCM" 0;
BA_DEF_DEF_  "GenSigTimeoutTime_VCM_" 0;
BA_DEF_DEF_  "GenSigTimeoutTime_VCM__" 0;
BA_DEF_DEF_  "GenSigTimeoutTime_VCU" 0;
BA_DEF_DEF_  "GenSigTimeoutTime_VCU_" 0;
BA_DEF_DEF_  "GenSigTimeoutTime_VMU" 0;
BA_DEF_DEF_  "SPN" 0;
BA_DEF_DEF_  "SigType" "Default";
BA_DEF_DEF_  "ILUsed" "Yes";
BA_DEF_DEF_  "NmStationAddress" 254;
BA_DEF_DEF_  "NodeLayerModules" "J1939_IL.dll";
BA_DEF_DEF_  "Baudrate" 0;
BA_DEF_DEF_  "BusType" "";
BA_DEF_DEF_  "Manufacturer" "";
BA_DEF_DEF_  "ProtocolType" "";
BA_ "Baudrate" 500000;
BA_ "BusType" "CAN";
BA_ "Manufacturer" "Vector";
BA_ "ProtocolType" "*";
BA_ "NmStationAddress" BU_ DiagTool_OBD1 0;
BA_ "NmStationAddress" BU_ DiwaNXT 3;
BA_ "NmStationAddress" BU_ EBS 11;
BA_ "NmStationAddress" BU_ IRCS 16;
BA_ "NmStationAddress" BU_ MulticII 23;
BA_ "NmStationAddress" BU_ NBM 33;
BA_ "NmStationAddress" BU_ VCM 39;
BA_ "NmStationAddress" BU_ ETS 56;
BA_ "NmStationAddress" BU_ NODE_45 69;
BA_ "NmStationAddress" BU_ FCCU 73;
BA_ "NmStationAddress" BU_ DICO 90;
BA_ "NmStationAddress" BU_ SGW2 126;
BA_ "NmStationAddress" BU_ HV_BOX 128;
BA_ "NmStationAddress" BU_ ADCU 158;
BA_ "NmStationAddress" BU_ AEBS 160;
BA_ "NmStationAddress" BU_ DTCO 238;
BA_ "NmStationAddress" BU_ MBMS 243;
BA_ "NmStationAddress" BU_ SGW 29;
BA_ "NmStationAddress" BU_ TPMS 51;
BA_ "NmStationAddress" BU_ ACU 231;
BA_ "NmStationAddress" BU_ CAID2 94;
BA_ "NmStationAddress" BU_ ELC5_Fr 47;
BA_ "NmStationAddress" BU_ ELC5_Rr 64;
BA_ "NmStationAddress" BU_ PredictiveVirtualNode2 247;
BA_ "NmStationAddress" BU_ BPU_3 246;
BA_ "NmStationAddress" BU_ Servo_dir_Turolla 46;
BA_ "NmStationAddress" BU_ PCM 74;
BA_ "NmStationAddress" BU_ NODE_90 144;
BA_ "NmStationAddress" BU_ NODE_91 145;
BA_ "NmStationAddress" BU_ NODE_92 146;
BA_ "NmStationAddress" BU_ RSRRM 156;
BA_ "NmStationAddress" BU_ FCU 194;
BA_ "NmStationAddress" BU_ DSE_VirtualNode2 232;
BA_ "NmStationAddress" BU_ DSE_VirtualNode40 177;
BA_ "NmStationAddress" BU_ DSE_VirtualNode38 178;
BA_ "NmStationAddress" BU_ DSE_VirtualNode49 179;
BA_ "NmStationAddress" BU_ DSE_VirtualNode48 180;
BA_ "NmStationAddress" BU_ DSE_VirtualNode39 181;
BA_ "NmStationAddress" BU_ DSE_VirtualNode37 182;
BA_ "NmStationAddress" BU_ DSE_VirtualNode36 183;
BA_ "NmStationAddress" BU_ BSM_B8 184;
BA_ "NmStationAddress" BU_ BPU_2 245;
BA_ "NmStationAddress" BU_ DSE_VirtualNode35 185;
BA_ "NmStationAddress" BU_ DSE_VirtualNode34 186;
BA_ "NmStationAddress" BU_ RADAR_ACC 252;
BA_ "NmStationAddress" BU_ DSE_VirtualNode33 187;
BA_ "NmStationAddress" BU_ DSE_VirtualNode41 188;
BA_ "NmStationAddress" BU_ NODE_BE 190;
BA_ "NmStationAddress" BU_ DSE_VirtualNode32 189;
BA_ "NmStationAddress" BU_ DSE_VirtualNode4 191;
BA_ "NmStationAddress" BU_ BSM_C0 192;
BA_ "NmStationAddress" BU_ BPU_1 244;
BA_ "NmStationAddress" BU_ DSE_VirtualNode31 193;
BA_ "NmStationAddress" BU_ DSE_VirtualNode29 195;
BA_ "NmStationAddress" BU_ DSE_VirtualNode28 196;
BA_ "NmStationAddress" BU_ MCDS 236;
BA_ "NmStationAddress" BU_ DSE_VirtualNode44 197;
BA_ "NmStationAddress" BU_ DSE_VirtualNode27 198;
BA_ "NmStationAddress" BU_ DSE_VirtualNode26 199;
BA_ "NmStationAddress" BU_ BSM_C8 200;
BA_ "NmStationAddress" BU_ ALM 201;
BA_ "NmStationAddress" BU_ DSE_VirtualNode25 202;
BA_ "NmStationAddress" BU_ DSE_VirtualNode50 203;
BA_ "NmStationAddress" BU_ DSE_VirtualNode47 205;
BA_ "NmStationAddress" BU_ DSE_VirtualNode46 206;
BA_ "NmStationAddress" BU_ DSE_VirtualNode23 207;
BA_ "NmStationAddress" BU_ DSE_VirtualNode51 237;
BA_ "NmStationAddress" BU_ ScanTool 241;
BA_ "NmStationAddress" BU_ DSE_VirtualNode22 208;
BA_ "NmStationAddress" BU_ DSE_VirtualNode21 209;
BA_ "NmStationAddress" BU_ AePTO 242;
BA_ "NmStationAddress" BU_ DC_VirtualNode1 253;
BA_ "NmStationAddress" BU_ DSE_VirtualNode43 210;
BA_ "NmStationAddress" BU_ MCSL 234;
BA_ "NmStationAddress" BU_ DSE_VirtualNode1 235;
BA_ "NmStationAddress" BU_ DSE_VirtualNode42 211;
BA_ "NmStationAddress" BU_ PredictiveVirtualNode3 240;
BA_ "NmStationAddress" BU_ DSE_VirtualNode20 212;
BA_ "NmStationAddress" BU_ DSE_VirtualNode19 213;
BA_ "NmStationAddress" BU_ DSE_VirtualNode18 214;
BA_ "NmStationAddress" BU_ DSE_VirtualNode17 215;
BA_ "NmStationAddress" BU_ DSE_VirtualNode16 216;
BA_ "NmStationAddress" BU_ DSE_VirtualNode15 217;
BA_ "NmStationAddress" BU_ NODE_F9 249;
BA_ "NmStationAddress" BU_ DiagTool 250;
BA_ "NmStationAddress" BU_ DSE_VirtualNode14 218;
BA_ "NmStationAddress" BU_ DSE_VirtualNode13 219;
BA_ "NmStationAddress" BU_ DSE_VirtualNode12 220;
BA_ "NmStationAddress" BU_ DSE_VirtualNode11 221;
BA_ "NmStationAddress" BU_ DSE_VirtualNode10 222;
BA_ "NmStationAddress" BU_ DSE_VirtualNode9 223;
BA_ "NmStationAddress" BU_ DSE_VirtualNode8 224;
BA_ "NmStationAddress" BU_ DSE_VirtualNode7 225;
BA_ "NmStationAddress" BU_ DSE_VirtualNode6 226;
BA_ "NmStationAddress" BU_ Mirror 233;
BA_ "NmStationAddress" BU_ DSE_VirtualNode5 227;
BA_ "NmStationAddress" BU_ SAS 228;
BA_ "NmStationAddress" BU_ DC_VirtualNode2 251;
BA_ "NmStationAddress" BU_ PredictiveVirtualNode1 248;
BA_ "NmStationAddress" BU_ DSE_VirtualNode45 230;
BA_ "NmStationAddress" BU_ ELFA3 239;
BA_ "NmStationAddress" BU_ EM_PTO 114;
BA_ "NmStationAddress" BU_ RM 15;
BA_ "NmStationAddress" BU_ CANAIR 25;
BA_ "NmStationAddress" BU_ SWI 113;
BA_ "CI_MsgDefinition" BO_ 2566725632 "J1939DA";
BA_ "CI_MsgId" BO_ 2566725632 1604;
BA_ "CI_MsgName" BO_ 2566725632 "A1DOC1 - Aftertreatment 1 Diesel Oxidation Catalyst 1";
BA_ "GenMsgCycleTime" BO_ 2566725632 500;
BA_ "GenMsgCycleTimeFast" BO_ 2566725632 500;
BA_ "GenMsgDelayTime" BO_ 2566725632 250;
BA_ "GenMsgSendType" BO_ 2566725632 0;
BA_ "GenMsgStartDelayTime" BO_ 2566725632 19;
BA_ "CI_MsgDefinition" BO_ 2565874432 "J1939DA";
BA_ "CI_MsgId" BO_ 2565874432 1238;
BA_ "CI_MsgName" BO_ 2565874432 "A1SCRDSI1 - Aftertreatment 1 SCR Dosing System Information 1";
BA_ "GenMsgCycleTime" BO_ 2565874432 50;
BA_ "GenMsgCycleTimeFast" BO_ 2565874432 50;
BA_ "GenMsgDelayTime" BO_ 2565874432 25;
BA_ "GenMsgSendType" BO_ 2565874432 0;
BA_ "GenMsgStartDelayTime" BO_ 2565874432 8;
BA_ "CI_MsgDefinition" BO_ 2499624448 "J1939DA";
BA_ "CI_MsgId" BO_ 2499624448 1611;
BA_ "CI_MsgName" BO_ 2499624448 "A1SCREGT1 - Aftertreatment 1 SCR Exhaust Gas Temperature 1";
BA_ "GenMsgCycleTime" BO_ 2499624448 500;
BA_ "GenMsgCycleTimeFast" BO_ 2499624448 500;
BA_ "GenMsgDelayTime" BO_ 2499624448 250;
BA_ "GenMsgSendType" BO_ 2499624448 0;
BA_ "GenMsgStartDelayTime" BO_ 2499624448 18;
BA_ "CI_MsgDefinition" BO_ 2566811431 "J1939DA";
BA_ "CI_MsgId" BO_ 2566811431 3765;
BA_ "CI_MsgName" BO_ 2566811431 "ACC1_27 - Adaptive Cruise Control 1";
BA_ "GenMsgCycleTime" BO_ 2566811431 100;
BA_ "GenMsgCycleTimeFast" BO_ 2566811431 100;
BA_ "GenMsgDelayTime" BO_ 2566811431 50;
BA_ "GenMsgSendType" BO_ 2566811431 0;
BA_ "GenMsgStartDelayTime" BO_ 2566811431 17;
BA_ "CI_MsgDefinition" BO_ 2566803735 "J1939DA";
BA_ "CI_MsgId" BO_ 2566803735 3787;
BA_ "CI_MsgName" BO_ 2566803735 "ACC2_17 - Adaptive Cruise Control, Operator Input";
BA_ "GenMsgCycleTime" BO_ 2566803735 250;
BA_ "GenMsgCycleTimeFast" BO_ 2566803735 250;
BA_ "GenMsgDelayTime" BO_ 2566803735 125;
BA_ "GenMsgSendType" BO_ 2566803735 0;
BA_ "GenMsgStartDelayTime" BO_ 2566803735 48;
BA_ "CI_MsgDefinition" BO_ 2565406464 "J1939-21";
BA_ "CI_MsgId" BO_ 2565406464 11104;
BA_ "CI_MsgName" BO_ 2565406464 "ACKM_00 - Acknowledgment Message";
BA_ "CI_MsgDefinition" BO_ 2565406467 "J1939-21";
BA_ "CI_MsgId" BO_ 2565406467 11146;
BA_ "CI_MsgName" BO_ 2565406467 "ACKM_03 - Acknowledgment Message";
BA_ "CI_MsgDefinition" BO_ 2565406475 "J1939-21";
BA_ "CI_MsgId" BO_ 2565406475 11160;
BA_ "CI_MsgName" BO_ 2565406475 "ACKM_0B - Acknowledgment Message";
BA_ "GenMsgDelayTime" BO_ 2565406475 200;
BA_ "CI_MsgDefinition" BO_ 2565406487 "J1939-21";
BA_ "CI_MsgId" BO_ 2565406487 11174;
BA_ "CI_MsgName" BO_ 2565406487 "ACKM_17 - Acknowledgment Message";
BA_ "CI_MsgDefinition" BO_ 2565406492 "J1939-21";
BA_ "CI_MsgId" BO_ 2565406492 11188;
BA_ "CI_MsgName" BO_ 2565406492 "ACKM_1C - Acknowledgment Message";
BA_ "CI_MsgDefinition" BO_ 2565406493 "J1939-21";
BA_ "CI_MsgId" BO_ 2565406493 11202;
BA_ "CI_MsgName" BO_ 2565406493 "ACKM_1D - Acknowledgment Message";
BA_ "CI_MsgDefinition" BO_ 2565406503 "J1939-21";
BA_ "CI_MsgId" BO_ 2565406503 11216;
BA_ "CI_MsgName" BO_ 2565406503 "ACKM_27 - Acknowledgment Message";
BA_ "CI_MsgDefinition" BO_ 2565406515 "J1939-21";
BA_ "CI_MsgId" BO_ 2565406515 13488;
BA_ "CI_MsgName" BO_ 2565406515 "ACKM_33 - Acknowledgment Message";
BA_ "CI_MsgDefinition" BO_ 2565406520 "J1939-21";
BA_ "CI_MsgId" BO_ 2565406520 11326;
BA_ "CI_MsgName" BO_ 2565406520 "ACKM_38 - Acknowledgment Message";
BA_ "CI_MsgDefinition" BO_ 2565406590 "J1939-21";
BA_ "CI_MsgId" BO_ 2565406590 11258;
BA_ "CI_MsgName" BO_ 2565406590 "ACKM_7E - Acknowledgment Message";
BA_ "CI_MsgDefinition" BO_ 2565406622 "J1939-21";
BA_ "CI_MsgId" BO_ 2565406622 17283;
BA_ "CI_MsgName" BO_ 2565406622 "ACKM_9E - Acknowledgment Message";
BA_ "CI_MsgDefinition" BO_ 2565406624 "J1939-21";
BA_ "CI_MsgId" BO_ 2565406624 11272;
BA_ "CI_MsgName" BO_ 2565406624 "ACKM_A0 - Acknowledgment Message";
BA_ "CI_MsgDefinition" BO_ 2565406702 "J1939-21";
BA_ "CI_MsgId" BO_ 2565406702 11286;
BA_ "CI_MsgName" BO_ 2565406702 "ACKM_EE - Acknowledgment Message";
BA_ "CI_MsgDefinition" BO_ 2633959399 "Iveco Proprietary";
BA_ "CI_MsgId" BO_ 2633959399 12749;
BA_ "CI_MsgName" BO_ 2633959399 "ACU - Articulation";
BA_ "GenMsgCycleTime" BO_ 2633959399 100;
BA_ "GenMsgCycleTimeFast" BO_ 2633959399 100;
BA_ "GenMsgDelayTime" BO_ 2633959399 50;
BA_ "GenMsgSendType" BO_ 2633959399 0;
BA_ "CI_MsgDefinition" BO_ 2364551072 "J1939DA";
BA_ "CI_MsgId" BO_ 2364551072 363;
BA_ "CI_MsgName" BO_ 2364551072 "AEBS1 - Advanced Emergency Braking System 1";
BA_ "GenMsgCycleTime" BO_ 2364551072 50;
BA_ "GenMsgCycleTimeFast" BO_ 2364551072 50;
BA_ "GenMsgDelayTime" BO_ 2364551072 10;
BA_ "GenMsgSendType" BO_ 2364551072 0;
BA_ "GenMsgStartDelayTime" BO_ 2364551072 2;
BA_ "CI_MsgDefinition" BO_ 2349572119 "J1939 p2p";
BA_ "CI_MsgId" BO_ 2349572119 372;
BA_ "CI_MsgName" BO_ 2349572119 "AEBS2_17_A0 - Advanced Emergency Braking System 2";
BA_ "GenMsgCycleTime" BO_ 2349572119 250;
BA_ "GenMsgCycleTimeFast" BO_ 2349572119 250;
BA_ "GenMsgDelayTime" BO_ 2349572119 125;
BA_ "GenMsgSendType" BO_ 2349572119 0;
BA_ "GenMsgStartDelayTime" BO_ 2349572119 46;
BA_ "CI_MsgDefinition" BO_ 2566827553 "J1939DA";
BA_ "CI_MsgId" BO_ 2566827553 2597;
BA_ "CI_MsgName" BO_ 2566827553 "AIR1_21 - Air Supply Pressure";
BA_ "GenMsgCycleTime" BO_ 2566827553 1000;
BA_ "GenMsgCycleTimeFast" BO_ 2566827553 1000;
BA_ "GenMsgDelayTime" BO_ 2566827553 500;
BA_ "GenMsgSendType" BO_ 2566827553 0;
BA_ "GenMsgStartDelayTime" BO_ 2566827553 60;
BA_ "CI_MsgDefinition" BO_ 2566620766 "CENELEC EN 50436-4";
BA_ "CI_MsgId" BO_ 2566620766 2611;
BA_ "CI_MsgName" BO_ 2566620766 "AITOV - Alcohol Interlock To Vehicle";
BA_ "GenMsgCycleTime" BO_ 2566620766 200;
BA_ "GenMsgCycleTimeFast" BO_ 2566620766 200;
BA_ "GenMsgDelayTime" BO_ 2566620766 100;
BA_ "GenMsgSendType" BO_ 2566620766 0;
BA_ "CI_MsgDefinition" BO_ 2566845696 "J1939DA";
BA_ "CI_MsgId" BO_ 2566845696 2024;
BA_ "CI_MsgName" BO_ 2566845696 "AMB_00 - Ambient Conditions";
BA_ "GenMsgCycleTime" BO_ 2566845696 1000;
BA_ "GenMsgCycleTimeFast" BO_ 2566845696 1000;
BA_ "GenMsgDelayTime" BO_ 2566845696 500;
BA_ "GenMsgSendType" BO_ 2566845696 0;
BA_ "GenMsgStartDelayTime" BO_ 2566845696 39;
BA_ "CI_MsgDefinition" BO_ 2566845719 "J1939DA";
BA_ "CI_MsgId" BO_ 2566845719 2030;
BA_ "CI_MsgName" BO_ 2566845719 "AMB_17 - Ambient Conditions";
BA_ "GenMsgCycleTime" BO_ 2566845719 1000;
BA_ "GenMsgCycleTimeFast" BO_ 2566845719 1000;
BA_ "GenMsgDelayTime" BO_ 2566845719 500;
BA_ "GenMsgSendType" BO_ 2566845719 0;
BA_ "GenMsgStartDelayTime" BO_ 2566845719 66;
BA_ "CI_MsgDefinition" BO_ 2565920602 "J1939DA";
BA_ "CI_MsgId" BO_ 2565920602 2058;
BA_ "CI_MsgName" BO_ 2565920602 "API1_O1_STATUS - Accessory Power Inverter 1 STATUS - Output 1";
BA_ "GenMsgCycleTime" BO_ 2565920602 100;
BA_ "GenMsgCycleTimeFast" BO_ 2565920602 100;
BA_ "GenMsgDelayTime" BO_ 2565920602 50;
BA_ "GenMsgSendType" BO_ 2565920602 0;
BA_ "GenMsgStartDelayTime" BO_ 2565920602 15;
BA_ "CI_MsgDefinition" BO_ 2566837527 "J1939DA";
BA_ "CI_MsgId" BO_ 2566837527 2199;
BA_ "CI_MsgName" BO_ 2566837527 "AS_17 - Alternator Information";
BA_ "GenMsgCycleTime" BO_ 2566837527 1000;
BA_ "GenMsgCycleTimeFast" BO_ 2566837527 1000;
BA_ "GenMsgDelayTime" BO_ 2566837527 100;
BA_ "GenMsgSendType" BO_ 2566837527 0;
BA_ "GenMsgStartDelayTime" BO_ 2566837527 66;
BA_ "CI_MsgDefinition" BO_ 2365479471 "J1939DA";
BA_ "CI_MsgId" BO_ 2365479471 3012;
BA_ "CI_MsgName" BO_ 2365479471 "ASC1_A - Air Suspension Control 1";
BA_ "GenMsgCycleTime" BO_ 2365479471 100;
BA_ "GenMsgCycleTimeFast" BO_ 2365479471 100;
BA_ "GenMsgDelayTime" BO_ 2365479471 50;
BA_ "GenMsgSendType" BO_ 2365479471 0;
BA_ "CI_MsgDefinition" BO_ 2365479488 "J1939DA";
BA_ "CI_MsgId" BO_ 2365479488 3038;
BA_ "CI_MsgName" BO_ 2365479488 "ASC1_B - Air Suspension Control 1";
BA_ "GenMsgCycleTime" BO_ 2365479488 100;
BA_ "GenMsgCycleTimeFast" BO_ 2365479488 100;
BA_ "GenMsgDelayTime" BO_ 2365479488 50;
BA_ "GenMsgSendType" BO_ 2365479488 0;
BA_ "CI_MsgDefinition" BO_ 2566805807 "J1939DA";
BA_ "CI_MsgId" BO_ 2566805807 3079;
BA_ "CI_MsgName" BO_ 2566805807 "ASC3_A - Air Suspension Control 3";
BA_ "GenMsgCycleTime" BO_ 2566805807 100;
BA_ "GenMsgCycleTimeFast" BO_ 2566805807 100;
BA_ "GenMsgDelayTime" BO_ 2566805807 50;
BA_ "GenMsgSendType" BO_ 2566805807 0;
BA_ "GenMsgStartDelayTime" BO_ 2566805807 4;
BA_ "CI_MsgDefinition" BO_ 2566805824 "J1939DA";
BA_ "CI_MsgId" BO_ 2566805824 3084;
BA_ "CI_MsgName" BO_ 2566805824 "ASC3_B - Air Suspension Control 3";
BA_ "GenMsgCycleTime" BO_ 2566805824 100;
BA_ "GenMsgCycleTimeFast" BO_ 2566805824 100;
BA_ "GenMsgDelayTime" BO_ 2566805824 50;
BA_ "GenMsgSendType" BO_ 2566805824 0;
BA_ "GenMsgStartDelayTime" BO_ 2566805824 4;
BA_ "CI_MsgDefinition" BO_ 2566805551 "J1939DA";
BA_ "CI_MsgId" BO_ 2566805551 3089;
BA_ "CI_MsgName" BO_ 2566805551 "ASC4_A - Air Suspension Control 4";
BA_ "GenMsgCycleTime" BO_ 2566805551 100;
BA_ "GenMsgCycleTimeFast" BO_ 2566805551 100;
BA_ "GenMsgDelayTime" BO_ 2566805551 50;
BA_ "GenMsgSendType" BO_ 2566805551 0;
BA_ "GenMsgStartDelayTime" BO_ 2566805551 2;
BA_ "CI_MsgDefinition" BO_ 2566805568 "J1939DA";
BA_ "CI_MsgId" BO_ 2566805568 3094;
BA_ "CI_MsgName" BO_ 2566805568 "ASC4_B - Air Suspension Control 4";
BA_ "GenMsgCycleTime" BO_ 2566805568 100;
BA_ "GenMsgCycleTimeFast" BO_ 2566805568 100;
BA_ "GenMsgDelayTime" BO_ 2566805568 50;
BA_ "GenMsgSendType" BO_ 2566805568 0;
BA_ "GenMsgStartDelayTime" BO_ 2566805568 2;
BA_ "CI_MsgDefinition" BO_ 2566763520 "J1939DA";
BA_ "CI_MsgId" BO_ 2566763520 1226;
BA_ "CI_MsgName" BO_ 2566763520 "AT1IG2 - Aftertreatment 1 Intake Gas 2";
BA_ "GenMsgCycleTime" BO_ 2566763520 500;
BA_ "GenMsgCycleTimeFast" BO_ 2566763520 500;
BA_ "GenMsgDelayTime" BO_ 2566763520 250;
BA_ "GenMsgSendType" BO_ 2566763520 0;
BA_ "GenMsgStartDelayTime" BO_ 2566763520 21;
BA_ "CI_MsgDefinition" BO_ 2566804992 "J1939DA";
BA_ "CI_MsgId" BO_ 2566804992 1245;
BA_ "CI_MsgName" BO_ 2566804992 "AT1T1I1 - Aftertreatment 1 Diesel Exhaust Fluid Tank 1 Information 1";
BA_ "GenMsgCycleTime" BO_ 2566804992 1000;
BA_ "GenMsgCycleTimeFast" BO_ 2566804992 1000;
BA_ "GenMsgDelayTime" BO_ 2566804992 500;
BA_ "GenMsgSendType" BO_ 2566804992 0;
BA_ "GenMsgStartDelayTime" BO_ 2566804992 38;
BA_ "CI_MsgDefinition" BO_ 2566849271 "Iveco Proprietary";
BA_ "CI_MsgId" BO_ 2566849271 1255;
BA_ "CI_MsgName" BO_ 2566849271 "Aux1DC - Aux1DCDCFeedback";
BA_ "GenMsgCycleTime" BO_ 2566849271 100;
BA_ "GenMsgCycleTimeFast" BO_ 2566849271 100;
BA_ "GenMsgDelayTime" BO_ 2566849271 50;
BA_ "GenMsgSendType" BO_ 2566849271 0;
BA_ "GenMsgStartDelayTime" BO_ 2566849271 16;
BA_ "CI_MsgDefinition" BO_ 2566849015 "Iveco Proprietary";
BA_ "CI_MsgId" BO_ 2566849015 1261;
BA_ "CI_MsgName" BO_ 2566849015 "Aux1Mot - Aux1MotorFeedback";
BA_ "GenMsgCycleTime" BO_ 2566849015 100;
BA_ "GenMsgCycleTimeFast" BO_ 2566849015 100;
BA_ "GenMsgDelayTime" BO_ 2566849015 50;
BA_ "GenMsgSendType" BO_ 2566849015 0;
BA_ "GenMsgStartDelayTime" BO_ 2566849015 14;
BA_ "CI_MsgDefinition" BO_ 2566848759 "Iveco Proprietary";
BA_ "CI_MsgId" BO_ 2566848759 1266;
BA_ "CI_MsgName" BO_ 2566848759 "Aux1St - Aux1Status";
BA_ "GenMsgCycleTime" BO_ 2566848759 100;
BA_ "GenMsgCycleTimeFast" BO_ 2566848759 100;
BA_ "GenMsgDelayTime" BO_ 2566848759 50;
BA_ "GenMsgSendType" BO_ 2566848759 0;
BA_ "GenMsgStartDelayTime" BO_ 2566848759 12;
BA_ "CI_MsgDefinition" BO_ 2566849270 "Iveco Proprietary";
BA_ "CI_MsgId" BO_ 2566849270 1269;
BA_ "CI_MsgName" BO_ 2566849270 "Aux2DC - Aux2DCDCFeedback";
BA_ "GenMsgCycleTime" BO_ 2566849270 100;
BA_ "GenMsgCycleTimeFast" BO_ 2566849270 100;
BA_ "GenMsgDelayTime" BO_ 2566849270 50;
BA_ "GenMsgSendType" BO_ 2566849270 0;
BA_ "GenMsgStartDelayTime" BO_ 2566849270 15;
BA_ "CI_ParId" SG_ 2566725632 At1DocInTemp "4765";
BA_ "CI_SigId" SG_ 2566725632 At1DocInTemp 1605;
BA_ "CI_SigName" SG_ 2566725632 At1DocInTemp "Aftertreatment 1 Diesel Oxidation Catalyst Intake Temperature";
BA_ "GenSigTimeoutTime_PCM" SG_ 2566725632 At1DocInTemp 2500;
BA_ "SPN" SG_ 2566725632 At1DocInTemp 4765;
BA_ "SigType" SG_ 2566725632 At1DocInTemp 1;
BA_ "CI_ParId" SG_ 2565874432 At1DefActDosQty "4331";
BA_ "CI_SigId" SG_ 2565874432 At1DefActDosQty 1239;
BA_ "CI_SigName" SG_ 2565874432 At1DefActDosQty "Aftertreatment 1 Diesel Exhaust Fluid Actual Dosing Quantity";
BA_ "GenSigTimeoutTime_PCM" SG_ 2565874432 At1DefActDosQty 500;
BA_ "GenSigTimeoutTime_SGW__" SG_ 2565874432 At1DefActDosQty 500;
BA_ "GenSigTimeoutTime_VCM_" SG_ 2565874432 At1DefActDosQty 500;
BA_ "SPN" SG_ 2565874432 At1DefActDosQty 4331;
BA_ "SigType" SG_ 2565874432 At1DefActDosQty 1;
BA_ "CI_ParId" SG_ 2499624448 At1ScrInTemp "4360";
BA_ "CI_SigId" SG_ 2499624448 At1ScrInTemp 1612;
BA_ "CI_SigName" SG_ 2499624448 At1ScrInTemp "Aftertreatment 1 SCR Intake Temperature";
BA_ "GenSigTimeoutTime_PCM" SG_ 2499624448 At1ScrInTemp 2500;
BA_ "GenSigTimeoutTime_VCM_" SG_ 2499624448 At1ScrInTemp 2500;
BA_ "SPN" SG_ 2499624448 At1ScrInTemp 4360;
BA_ "SigType" SG_ 2499624448 At1ScrInTemp 1;
BA_ "CI_ParId" SG_ 2499624448 At1ScrOutTemp "4363";
BA_ "CI_SigId" SG_ 2499624448 At1ScrOutTemp 1614;
BA_ "CI_SigName" SG_ 2499624448 At1ScrOutTemp "Aftertreatment 1 SCR Outlet Temperature";
BA_ "GenSigTimeoutTime_PCM" SG_ 2499624448 At1ScrOutTemp 2500;
BA_ "GenSigTimeoutTime_VCM_" SG_ 2499624448 At1ScrOutTemp 2500;
BA_ "SPN" SG_ 2499624448 At1ScrOutTemp 4363;
BA_ "SigType" SG_ 2499624448 At1ScrOutTemp 1;
BA_ "CI_ParId" SG_ 2566811431 AccMode "1590";
BA_ "CI_SigId" SG_ 2566811431 AccMode 3769;
BA_ "CI_SigName" SG_ 2566811431 AccMode "Adaptive Cruise Control Mode";
BA_ "GenSigTimeoutTime_MulticS" SG_ 2566811431 AccMode 500;
BA_ "GenSigTimeoutTime_PCM" SG_ 2566811431 AccMode 500;
BA_ "GenSigTimeoutTime_SGW__" SG_ 2566811431 AccMode 500;
BA_ "SPN" SG_ 2566811431 AccMode 1590;
BA_ "CI_ParId" SG_ 2566811431 AccSetDistMode "1589";
BA_ "CI_SigId" SG_ 2566811431 AccSetDistMode 3770;
BA_ "CI_SigName" SG_ 2566811431 AccSetDistMode "Adaptive cruise control set distance mode";
BA_ "GenSigTimeoutTime_MulticS" SG_ 2566811431 AccSetDistMode 500;
BA_ "GenSigTimeoutTime_PCM" SG_ 2566811431 AccSetDistMode 500;
BA_ "GenSigTimeoutTime_SGW__" SG_ 2566811431 AccSetDistMode 500;
BA_ "SPN" SG_ 2566811431 AccSetDistMode 1589;
BA_ "CI_ParId" SG_ 2566803735 AccUseDem "5023";
BA_ "CI_SigId" SG_ 2566803735 AccUseDem 3788;
BA_ "CI_SigName" SG_ 2566803735 AccUseDem "ACC usage demand";
BA_ "GenSigTimeoutTime_PCM" SG_ 2566803735 AccUseDem 1250;
BA_ "GenSigTimeoutTime_SGW__" SG_ 2566803735 AccUseDem 1250;
BA_ "GenSigTimeoutTime_VCM" SG_ 2566803735 AccUseDem 1250;
BA_ "SPN" SG_ 2566803735 AccUseDem 5023;
BA_ "SigType" SG_ 2566803735 AccUseDem 4;
BA_ "CI_ParId" SG_ 2565406464 CtrlByte_Ackm "2541";
BA_ "CI_SigId" SG_ 2565406464 CtrlByte_Ackm 11105;
BA_ "CI_SigName" SG_ 2565406464 CtrlByte_Ackm "Control Byte (ACKM)";
BA_ "SPN" SG_ 2565406464 CtrlByte_Ackm 2541;
BA_ "CI_ParId" SG_ 2565406464 Pgn_Ack "2543";
BA_ "CI_SigId" SG_ 2565406464 Pgn_Ack 11114;
BA_ "CI_SigName" SG_ 2565406464 Pgn_Ack "Parameter Group Number (ACK)";
BA_ "SPN" SG_ 2565406464 Pgn_Ack 2543;
BA_ "CI_ParId" SG_ 2565406464 Pgn_Nack "2545";
BA_ "CI_SigId" SG_ 2565406464 Pgn_Nack 11115;
BA_ "CI_SigName" SG_ 2565406464 Pgn_Nack "Parameter Group Number (NACK)";
BA_ "SPN" SG_ 2565406464 Pgn_Nack 2545;
BA_ "CI_ParId" SG_ 2565406464 Pgn_Ad "2547";
BA_ "CI_SigId" SG_ 2565406464 Pgn_Ad 11116;
BA_ "CI_SigName" SG_ 2565406464 Pgn_Ad "Parameter Group Number (NACK_AD)";
BA_ "SPN" SG_ 2565406464 Pgn_Ad 2547;
BA_ "CI_ParId" SG_ 2565406464 Pgn_Busy "2549";
BA_ "CI_SigId" SG_ 2565406464 Pgn_Busy 11117;
BA_ "CI_SigName" SG_ 2565406464 Pgn_Busy "Parameter Group Number (NACK_Busy)";
BA_ "SPN" SG_ 2565406464 Pgn_Busy 2549;
BA_ "CI_ParId" SG_ 2565406467 CtrlByte_Ackm_18E8FF03 "2541";
BA_ "CI_SigId" SG_ 2565406467 CtrlByte_Ackm_18E8FF03 11147;
BA_ "CI_SigName" SG_ 2565406467 CtrlByte_Ackm_18E8FF03 "Control Byte (ACKM)";
BA_ "SPN" SG_ 2565406467 CtrlByte_Ackm_18E8FF03 2541;
BA_ "CI_ParId" SG_ 2565406467 Pgn_Ack_18E8FF03 "2543";
BA_ "CI_SigId" SG_ 2565406467 Pgn_Ack_18E8FF03 11156;
BA_ "CI_SigName" SG_ 2565406467 Pgn_Ack_18E8FF03 "Parameter Group Number (ACK)";
BA_ "SPN" SG_ 2565406467 Pgn_Ack_18E8FF03 2543;
BA_ "CI_ParId" SG_ 2565406467 Pgn_Nack_18E8FF03 "2545";
BA_ "CI_SigId" SG_ 2565406467 Pgn_Nack_18E8FF03 11157;
BA_ "CI_SigName" SG_ 2565406467 Pgn_Nack_18E8FF03 "Parameter Group Number (NACK)";
BA_ "SPN" SG_ 2565406467 Pgn_Nack_18E8FF03 2545;
BA_ "CI_ParId" SG_ 2565406467 Pgn_Ad_18E8FF03 "2547";
BA_ "CI_SigId" SG_ 2565406467 Pgn_Ad_18E8FF03 11158;
BA_ "CI_SigName" SG_ 2565406467 Pgn_Ad_18E8FF03 "Parameter Group Number (NACK_AD)";
BA_ "SPN" SG_ 2565406467 Pgn_Ad_18E8FF03 2547;
BA_ "CI_ParId" SG_ 2565406467 Pgn_Busy_18E8FF03 "2549";
BA_ "CI_SigId" SG_ 2565406467 Pgn_Busy_18E8FF03 11159;
BA_ "CI_SigName" SG_ 2565406467 Pgn_Busy_18E8FF03 "Parameter Group Number (NACK_Busy)";
BA_ "SPN" SG_ 2565406467 Pgn_Busy_18E8FF03 2549;
BA_ "CI_ParId" SG_ 2565406475 CtrlByte_Ackm_18E8FF0B "2541";
BA_ "CI_SigId" SG_ 2565406475 CtrlByte_Ackm_18E8FF0B 11161;
BA_ "CI_SigName" SG_ 2565406475 CtrlByte_Ackm_18E8FF0B "Control Byte (ACKM)";
BA_ "SPN" SG_ 2565406475 CtrlByte_Ackm_18E8FF0B 2541;
BA_ "CI_ParId" SG_ 2565406475 Pgn_Ack_18E8FF0B "2543";
BA_ "CI_SigId" SG_ 2565406475 Pgn_Ack_18E8FF0B 11170;
BA_ "CI_SigName" SG_ 2565406475 Pgn_Ack_18E8FF0B "Parameter Group Number (ACK)";
BA_ "SPN" SG_ 2565406475 Pgn_Ack_18E8FF0B 2543;
BA_ "CI_ParId" SG_ 2565406475 Pgn_Nack_18E8FF0B "2545";
BA_ "CI_SigId" SG_ 2565406475 Pgn_Nack_18E8FF0B 11171;
BA_ "CI_SigName" SG_ 2565406475 Pgn_Nack_18E8FF0B "Parameter Group Number (NACK)";
BA_ "SPN" SG_ 2565406475 Pgn_Nack_18E8FF0B 2545;
BA_ "CI_ParId" SG_ 2565406475 Pgn_Ad_18E8FF0B "2547";
BA_ "CI_SigId" SG_ 2565406475 Pgn_Ad_18E8FF0B 11172;
BA_ "CI_SigName" SG_ 2565406475 Pgn_Ad_18E8FF0B "Parameter Group Number (NACK_AD)";
BA_ "SPN" SG_ 2565406475 Pgn_Ad_18E8FF0B 2547;
BA_ "CI_ParId" SG_ 2565406475 Pgn_Busy_18E8FF0B "2549";
BA_ "CI_SigId" SG_ 2565406475 Pgn_Busy_18E8FF0B 11173;
BA_ "CI_SigName" SG_ 2565406475 Pgn_Busy_18E8FF0B "Parameter Group Number (NACK_Busy)";
BA_ "SPN" SG_ 2565406475 Pgn_Busy_18E8FF0B 2549;
BA_ "CI_ParId" SG_ 2565406487 CtrlByte_Ackm_18E8FF17 "2541";
BA_ "CI_SigId" SG_ 2565406487 CtrlByte_Ackm_18E8FF17 11175;
BA_ "CI_SigName" SG_ 2565406487 CtrlByte_Ackm_18E8FF17 "Control Byte (ACKM)";
BA_ "SPN" SG_ 2565406487 CtrlByte_Ackm_18E8FF17 2541;
BA_ "CI_ParId" SG_ 2565406487 Pgn_Ack_18E8FF17 "2543";
BA_ "CI_SigId" SG_ 2565406487 Pgn_Ack_18E8FF17 11184;
BA_ "CI_SigName" SG_ 2565406487 Pgn_Ack_18E8FF17 "Parameter Group Number (ACK)";
BA_ "SPN" SG_ 2565406487 Pgn_Ack_18E8FF17 2543;
BA_ "CI_ParId" SG_ 2565406487 Pgn_Nack_18E8FF17 "2545";
BA_ "CI_SigId" SG_ 2565406487 Pgn_Nack_18E8FF17 11185;
BA_ "CI_SigName" SG_ 2565406487 Pgn_Nack_18E8FF17 "Parameter Group Number (NACK)";
BA_ "SPN" SG_ 2565406487 Pgn_Nack_18E8FF17 2545;
BA_ "CI_ParId" SG_ 2565406487 Pgn_Ad_18E8FF17 "2547";
BA_ "CI_SigId" SG_ 2565406487 Pgn_Ad_18E8FF17 11186;
BA_ "CI_SigName" SG_ 2565406487 Pgn_Ad_18E8FF17 "Parameter Group Number (NACK_AD)";
BA_ "SPN" SG_ 2565406487 Pgn_Ad_18E8FF17 2547;
BA_ "CI_ParId" SG_ 2565406487 Pgn_Busy_18E8FF17 "2549";
BA_ "CI_SigId" SG_ 2565406487 Pgn_Busy_18E8FF17 11187;
BA_ "CI_SigName" SG_ 2565406487 Pgn_Busy_18E8FF17 "Parameter Group Number (NACK_Busy)";
BA_ "SPN" SG_ 2565406487 Pgn_Busy_18E8FF17 2549;
BA_ "CI_ParId" SG_ 2565406492 CtrlByte_Ackm_18E8FF1C "2541";
BA_ "CI_SigId" SG_ 2565406492 CtrlByte_Ackm_18E8FF1C 11189;
BA_ "CI_SigName" SG_ 2565406492 CtrlByte_Ackm_18E8FF1C "Control Byte (ACKM)";
BA_ "SPN" SG_ 2565406492 CtrlByte_Ackm_18E8FF1C 2541;
BA_ "CI_ParId" SG_ 2565406492 AddrAckd "3290";
BA_ "CI_SigId" SG_ 2565406492 AddrAckd 11194;
BA_ "CI_SigName" SG_ 2565406492 AddrAckd "Address Acknowledged";
BA_ "SPN" SG_ 2565406492 AddrAckd 3290;
BA_ "CI_ParId" SG_ 2565406492 AddrNack "3291";
BA_ "CI_SigId" SG_ 2565406492 AddrNack 11195;
BA_ "CI_SigName" SG_ 2565406492 AddrNack "Address Negative Acknowledgement";
BA_ "SPN" SG_ 2565406492 AddrNack 3291;
BA_ "CI_ParId" SG_ 2565406492 AddrAccessDenied "3292";
BA_ "CI_SigId" SG_ 2565406492 AddrAccessDenied 11196;
BA_ "CI_SigName" SG_ 2565406492 AddrAccessDenied "Address Access Denied";
BA_ "SPN" SG_ 2565406492 AddrAccessDenied 3292;
BA_ "CI_ParId" SG_ 2565406492 AddrBusy "3293";
BA_ "CI_SigId" SG_ 2565406492 AddrBusy 11197;
BA_ "CI_SigName" SG_ 2565406492 AddrBusy "Address Busy";
BA_ "SPN" SG_ 2565406492 AddrBusy 3293;
BA_ "CI_ParId" SG_ 2565406492 Pgn_Ack_18E8FF1C "2543";
BA_ "CI_SigId" SG_ 2565406492 Pgn_Ack_18E8FF1C 11198;
BA_ "CI_SigName" SG_ 2565406492 Pgn_Ack_18E8FF1C "Parameter Group Number (ACK)";
BA_ "SPN" SG_ 2565406492 Pgn_Ack_18E8FF1C 2543;
BA_ "CI_ParId" SG_ 2565406492 Pgn_Nack_18E8FF1C "2545";
BA_ "CI_SigId" SG_ 2565406492 Pgn_Nack_18E8FF1C 11199;
BA_ "CI_SigName" SG_ 2565406492 Pgn_Nack_18E8FF1C "Parameter Group Number (NACK)";
BA_ "SPN" SG_ 2565406492 Pgn_Nack_18E8FF1C 2545;
BA_ "CI_ParId" SG_ 2565406492 Pgn_Ad_18E8FF1C "2547";
BA_ "CI_SigId" SG_ 2565406492 Pgn_Ad_18E8FF1C 11200;
BA_ "CI_SigName" SG_ 2565406492 Pgn_Ad_18E8FF1C "Parameter Group Number (NACK_AD)";
BA_ "SPN" SG_ 2565406492 Pgn_Ad_18E8FF1C 2547;
BA_ "CI_ParId" SG_ 2565406492 Pgn_Busy_18E8FF1C "2549";
BA_ "CI_SigId" SG_ 2565406492 Pgn_Busy_18E8FF1C 11201;
BA_ "CI_SigName" SG_ 2565406492 Pgn_Busy_18E8FF1C "Parameter Group Number (NACK_Busy)";
BA_ "SPN" SG_ 2565406492 Pgn_Busy_18E8FF1C 2549;
BA_ "CI_ParId" SG_ 2565406493 CtrlByte_Ackm_18E8FF1D "2541";
BA_ "CI_SigId" SG_ 2565406493 CtrlByte_Ackm_18E8FF1D 11203;
BA_ "CI_SigName" SG_ 2565406493 CtrlByte_Ackm_18E8FF1D "Control Byte (ACKM)";
BA_ "SPN" SG_ 2565406493 CtrlByte_Ackm_18E8FF1D 2541;
BA_ "CI_ParId" SG_ 2565406493 AddrAckd_18E8FF1D "3290";
BA_ "CI_SigId" SG_ 2565406493 AddrAckd_18E8FF1D 11208;
BA_ "CI_SigName" SG_ 2565406493 AddrAckd_18E8FF1D "Address Acknowledged";
BA_ "SPN" SG_ 2565406493 AddrAckd_18E8FF1D 3290;
BA_ "CI_ParId" SG_ 2565406493 AddrNack_18E8FF1D "3291";
BA_ "CI_SigId" SG_ 2565406493 AddrNack_18E8FF1D 11209;
BA_ "CI_SigName" SG_ 2565406493 AddrNack_18E8FF1D "Address Negative Acknowledgement";
BA_ "SPN" SG_ 2565406493 AddrNack_18E8FF1D 3291;
BA_ "CI_ParId" SG_ 2565406493 AddrAccessDenied_18E8FF1D "3292";
BA_ "CI_SigId" SG_ 2565406493 AddrAccessDenied_18E8FF1D 11210;
BA_ "CI_SigName" SG_ 2565406493 AddrAccessDenied_18E8FF1D "Address Access Denied";
BA_ "SPN" SG_ 2565406493 AddrAccessDenied_18E8FF1D 3292;
BA_ "CI_ParId" SG_ 2565406493 AddrBusy_18E8FF1D "3293";
BA_ "CI_SigId" SG_ 2565406493 AddrBusy_18E8FF1D 11211;
BA_ "CI_SigName" SG_ 2565406493 AddrBusy_18E8FF1D "Address Busy";
BA_ "SPN" SG_ 2565406493 AddrBusy_18E8FF1D 3293;
BA_ "CI_ParId" SG_ 2565406493 Pgn_Ack_18E8FF1D "2543";
BA_ "CI_SigId" SG_ 2565406493 Pgn_Ack_18E8FF1D 11212;
BA_ "CI_SigName" SG_ 2565406493 Pgn_Ack_18E8FF1D "Parameter Group Number (ACK)";
BA_ "SPN" SG_ 2565406493 Pgn_Ack_18E8FF1D 2543;
BA_ "CI_ParId" SG_ 2565406493 Pgn_Nack_18E8FF1D "2545";
BA_ "CI_SigId" SG_ 2565406493 Pgn_Nack_18E8FF1D 11213;
BA_ "CI_SigName" SG_ 2565406493 Pgn_Nack_18E8FF1D "Parameter Group Number (NACK)";
BA_ "SPN" SG_ 2565406493 Pgn_Nack_18E8FF1D 2545;
BA_ "CI_ParId" SG_ 2565406493 Pgn_Ad_18E8FF1D "2547";
BA_ "CI_SigId" SG_ 2565406493 Pgn_Ad_18E8FF1D 11214;
BA_ "CI_SigName" SG_ 2565406493 Pgn_Ad_18E8FF1D "Parameter Group Number (NACK_AD)";
BA_ "SPN" SG_ 2565406493 Pgn_Ad_18E8FF1D 2547;
BA_ "CI_ParId" SG_ 2565406493 Pgn_Busy_18E8FF1D "2549";
BA_ "CI_SigId" SG_ 2565406493 Pgn_Busy_18E8FF1D 11215;
BA_ "CI_SigName" SG_ 2565406493 Pgn_Busy_18E8FF1D "Parameter Group Number (NACK_Busy)";
BA_ "SPN" SG_ 2565406493 Pgn_Busy_18E8FF1D 2549;
BA_ "CI_ParId" SG_ 2565406503 CtrlByte_Ackm_18E8FF27 "2541";
BA_ "CI_SigId" SG_ 2565406503 CtrlByte_Ackm_18E8FF27 11217;
BA_ "CI_SigName" SG_ 2565406503 CtrlByte_Ackm_18E8FF27 "Control Byte (ACKM)";
BA_ "SPN" SG_ 2565406503 CtrlByte_Ackm_18E8FF27 2541;
BA_ "CI_ParId" SG_ 2565406503 Pgn_Ack_18E8FF27 "2543";
BA_ "CI_SigId" SG_ 2565406503 Pgn_Ack_18E8FF27 11226;
BA_ "CI_SigName" SG_ 2565406503 Pgn_Ack_18E8FF27 "Parameter Group Number (ACK)";
BA_ "SPN" SG_ 2565406503 Pgn_Ack_18E8FF27 2543;
BA_ "CI_ParId" SG_ 2565406503 Pgn_Nack_18E8FF27 "2545";
BA_ "CI_SigId" SG_ 2565406503 Pgn_Nack_18E8FF27 11227;
BA_ "CI_SigName" SG_ 2565406503 Pgn_Nack_18E8FF27 "Parameter Group Number (NACK)";
BA_ "SPN" SG_ 2565406503 Pgn_Nack_18E8FF27 2545;
BA_ "CI_ParId" SG_ 2565406503 Pgn_Ad_18E8FF27 "2547";
BA_ "CI_SigId" SG_ 2565406503 Pgn_Ad_18E8FF27 11228;
BA_ "CI_SigName" SG_ 2565406503 Pgn_Ad_18E8FF27 "Parameter Group Number (NACK_AD)";
BA_ "SPN" SG_ 2565406503 Pgn_Ad_18E8FF27 2547;
BA_ "CI_ParId" SG_ 2565406503 Pgn_Busy_18E8FF27 "2549";
BA_ "CI_SigId" SG_ 2565406503 Pgn_Busy_18E8FF27 11229;
BA_ "CI_SigName" SG_ 2565406503 Pgn_Busy_18E8FF27 "Parameter Group Number (NACK_Busy)";
BA_ "SPN" SG_ 2565406503 Pgn_Busy_18E8FF27 2549;
BA_ "CI_ParId" SG_ 2565406515 CtrlByte_Ackm_18E8FF33 "2541";
BA_ "CI_SigId" SG_ 2565406515 CtrlByte_Ackm_18E8FF33 13489;
BA_ "CI_SigName" SG_ 2565406515 CtrlByte_Ackm_18E8FF33 "Control Byte (ACKM)";
BA_ "SPN" SG_ 2565406515 CtrlByte_Ackm_18E8FF33 2541;
BA_ "CI_ParId" SG_ 2565406515 Pgn_Ack_18E8FF33 "2543";
BA_ "CI_SigId" SG_ 2565406515 Pgn_Ack_18E8FF33 13498;
BA_ "CI_SigName" SG_ 2565406515 Pgn_Ack_18E8FF33 "Parameter Group Number (ACK)";
BA_ "SPN" SG_ 2565406515 Pgn_Ack_18E8FF33 2543;
BA_ "CI_ParId" SG_ 2565406515 Pgn_Nack_18E8FF33 "2545";
BA_ "CI_SigId" SG_ 2565406515 Pgn_Nack_18E8FF33 13499;
BA_ "CI_SigName" SG_ 2565406515 Pgn_Nack_18E8FF33 "Parameter Group Number (NACK)";
BA_ "SPN" SG_ 2565406515 Pgn_Nack_18E8FF33 2545;
BA_ "CI_ParId" SG_ 2565406515 Pgn_Ad_18E8FF33 "2547";
BA_ "CI_SigId" SG_ 2565406515 Pgn_Ad_18E8FF33 13500;
BA_ "CI_SigName" SG_ 2565406515 Pgn_Ad_18E8FF33 "Parameter Group Number (NACK_AD)";
BA_ "SPN" SG_ 2565406515 Pgn_Ad_18E8FF33 2547;
BA_ "CI_ParId" SG_ 2565406515 Pgn_Busy_18E8FF33 "2549";
BA_ "CI_SigId" SG_ 2565406515 Pgn_Busy_18E8FF33 13501;
BA_ "CI_SigName" SG_ 2565406515 Pgn_Busy_18E8FF33 "Parameter Group Number (NACK_Busy)";
BA_ "SPN" SG_ 2565406515 Pgn_Busy_18E8FF33 2549;
BA_ "CI_ParId" SG_ 2565406520 CtrlByte_Ackm_18E8FF38 "2541";
BA_ "CI_SigId" SG_ 2565406520 CtrlByte_Ackm_18E8FF38 11327;
BA_ "CI_SigName" SG_ 2565406520 CtrlByte_Ackm_18E8FF38 "Control Byte (ACKM)";
BA_ "SPN" SG_ 2565406520 CtrlByte_Ackm_18E8FF38 2541;
BA_ "CI_ParId" SG_ 2565406520 Pgn_Ack_18E8FF38 "2543";
BA_ "CI_SigId" SG_ 2565406520 Pgn_Ack_18E8FF38 11336;
BA_ "CI_SigName" SG_ 2565406520 Pgn_Ack_18E8FF38 "Parameter Group Number (ACK)";
BA_ "SPN" SG_ 2565406520 Pgn_Ack_18E8FF38 2543;
BA_ "CI_ParId" SG_ 2565406520 Pgn_Nack_18E8FF38 "2545";
BA_ "CI_SigId" SG_ 2565406520 Pgn_Nack_18E8FF38 11337;
BA_ "CI_SigName" SG_ 2565406520 Pgn_Nack_18E8FF38 "Parameter Group Number (NACK)";
BA_ "SPN" SG_ 2565406520 Pgn_Nack_18E8FF38 2545;
BA_ "CI_ParId" SG_ 2565406520 Pgn_Ad_18E8FF38 "2547";
BA_ "CI_SigId" SG_ 2565406520 Pgn_Ad_18E8FF38 11338;
BA_ "CI_SigName" SG_ 2565406520 Pgn_Ad_18E8FF38 "Parameter Group Number (NACK_AD)";
BA_ "SPN" SG_ 2565406520 Pgn_Ad_18E8FF38 2547;
BA_ "CI_ParId" SG_ 2565406520 Pgn_Busy_18E8FF38 "2549";
BA_ "CI_SigId" SG_ 2565406520 Pgn_Busy_18E8FF38 11339;
BA_ "CI_SigName" SG_ 2565406520 Pgn_Busy_18E8FF38 "Parameter Group Number (NACK_Busy)";
BA_ "SPN" SG_ 2565406520 Pgn_Busy_18E8FF38 2549;
BA_ "CI_ParId" SG_ 2565406590 CtrlByte_Ackm_18E8FF7E "2541";
BA_ "CI_SigId" SG_ 2565406590 CtrlByte_Ackm_18E8FF7E 11259;
BA_ "CI_SigName" SG_ 2565406590 CtrlByte_Ackm_18E8FF7E "Control Byte (ACKM)";
BA_ "SPN" SG_ 2565406590 CtrlByte_Ackm_18E8FF7E 2541;
BA_ "CI_ParId" SG_ 2565406590 Pgn_Ack_18E8FF7E "2543";
BA_ "CI_SigId" SG_ 2565406590 Pgn_Ack_18E8FF7E 11268;
BA_ "CI_SigName" SG_ 2565406590 Pgn_Ack_18E8FF7E "Parameter Group Number (ACK)";
BA_ "SPN" SG_ 2565406590 Pgn_Ack_18E8FF7E 2543;
BA_ "CI_ParId" SG_ 2565406590 Pgn_Nack_18E8FF7E "2545";
BA_ "CI_SigId" SG_ 2565406590 Pgn_Nack_18E8FF7E 11269;
BA_ "CI_SigName" SG_ 2565406590 Pgn_Nack_18E8FF7E "Parameter Group Number (NACK)";
BA_ "SPN" SG_ 2565406590 Pgn_Nack_18E8FF7E 2545;
BA_ "CI_ParId" SG_ 2565406590 Pgn_Ad_18E8FF7E "2547";
BA_ "CI_SigId" SG_ 2565406590 Pgn_Ad_18E8FF7E 11270;
BA_ "CI_SigName" SG_ 2565406590 Pgn_Ad_18E8FF7E "Parameter Group Number (NACK_AD)";
BA_ "SPN" SG_ 2565406590 Pgn_Ad_18E8FF7E 2547;
BA_ "CI_ParId" SG_ 2565406590 Pgn_Busy_18E8FF7E "2549";
BA_ "CI_SigId" SG_ 2565406590 Pgn_Busy_18E8FF7E 11271;
BA_ "CI_SigName" SG_ 2565406590 Pgn_Busy_18E8FF7E "Parameter Group Number (NACK_Busy)";
BA_ "SPN" SG_ 2565406590 Pgn_Busy_18E8FF7E 2549;
BA_ "CI_ParId" SG_ 2565406622 CtrlByte_Ackm_18E8FF9E "2541";
BA_ "CI_SigId" SG_ 2565406622 CtrlByte_Ackm_18E8FF9E 17284;
BA_ "CI_SigName" SG_ 2565406622 CtrlByte_Ackm_18E8FF9E "Control Byte (ACKM)";
BA_ "SPN" SG_ 2565406622 CtrlByte_Ackm_18E8FF9E 2541;
BA_ "CI_ParId" SG_ 2565406622 Pgn_Ack_18E8FF9E "2543";
BA_ "CI_SigId" SG_ 2565406622 Pgn_Ack_18E8FF9E 17293;
BA_ "CI_SigName" SG_ 2565406622 Pgn_Ack_18E8FF9E "Parameter Group Number (ACK)";
BA_ "SPN" SG_ 2565406622 Pgn_Ack_18E8FF9E 2543;
BA_ "CI_ParId" SG_ 2565406622 Pgn_Nack_18E8FF9E "2545";
BA_ "CI_SigId" SG_ 2565406622 Pgn_Nack_18E8FF9E 17294;
BA_ "CI_SigName" SG_ 2565406622 Pgn_Nack_18E8FF9E "Parameter Group Number (NACK)";
BA_ "SPN" SG_ 2565406622 Pgn_Nack_18E8FF9E 2545;
BA_ "CI_ParId" SG_ 2565406622 Pgn_Ad_18E8FF9E "2547";
BA_ "CI_SigId" SG_ 2565406622 Pgn_Ad_18E8FF9E 17295;
BA_ "CI_SigName" SG_ 2565406622 Pgn_Ad_18E8FF9E "Parameter Group Number (NACK_AD)";
BA_ "SPN" SG_ 2565406622 Pgn_Ad_18E8FF9E 2547;
BA_ "CI_ParId" SG_ 2565406622 Pgn_Busy_18E8FF9E "2549";
BA_ "CI_SigId" SG_ 2565406622 Pgn_Busy_18E8FF9E 17296;
BA_ "CI_SigName" SG_ 2565406622 Pgn_Busy_18E8FF9E "Parameter Group Number (NACK_Busy)";
BA_ "SPN" SG_ 2565406622 Pgn_Busy_18E8FF9E 2549;
BA_ "CI_ParId" SG_ 2565406624 CtrlByte_Ackm_18E8FFA0 "2541";
BA_ "CI_SigId" SG_ 2565406624 CtrlByte_Ackm_18E8FFA0 11273;
BA_ "CI_SigName" SG_ 2565406624 CtrlByte_Ackm_18E8FFA0 "Control Byte (ACKM)";
BA_ "SPN" SG_ 2565406624 CtrlByte_Ackm_18E8FFA0 2541;
BA_ "CI_ParId" SG_ 2565406624 Pgn_Ack_18E8FFA0 "2543";
BA_ "CI_SigId" SG_ 2565406624 Pgn_Ack_18E8FFA0 11282;
BA_ "CI_SigName" SG_ 2565406624 Pgn_Ack_18E8FFA0 "Parameter Group Number (ACK)";
BA_ "SPN" SG_ 2565406624 Pgn_Ack_18E8FFA0 2543;
BA_ "CI_ParId" SG_ 2565406624 Pgn_Nack_18E8FFA0 "2545";
BA_ "CI_SigId" SG_ 2565406624 Pgn_Nack_18E8FFA0 11283;
BA_ "CI_SigName" SG_ 2565406624 Pgn_Nack_18E8FFA0 "Parameter Group Number (NACK)";
BA_ "SPN" SG_ 2565406624 Pgn_Nack_18E8FFA0 2545;
BA_ "CI_ParId" SG_ 2565406624 Pgn_Ad_18E8FFA0 "2547";
BA_ "CI_SigId" SG_ 2565406624 Pgn_Ad_18E8FFA0 11284;
BA_ "CI_SigName" SG_ 2565406624 Pgn_Ad_18E8FFA0 "Parameter Group Number (NACK_AD)";
BA_ "SPN" SG_ 2565406624 Pgn_Ad_18E8FFA0 2547;
BA_ "CI_ParId" SG_ 2565406624 Pgn_Busy_18E8FFA0 "2549";
BA_ "CI_SigId" SG_ 2565406624 Pgn_Busy_18E8FFA0 11285;
BA_ "CI_SigName" SG_ 2565406624 Pgn_Busy_18E8FFA0 "Parameter Group Number (NACK_Busy)";
BA_ "SPN" SG_ 2565406624 Pgn_Busy_18E8FFA0 2549;
BA_ "CI_ParId" SG_ 2565406702 CtrlByte_Ackm_18E8FFEE "2541";
BA_ "CI_SigId" SG_ 2565406702 CtrlByte_Ackm_18E8FFEE 11287;
BA_ "CI_SigName" SG_ 2565406702 CtrlByte_Ackm_18E8FFEE "Control Byte (ACKM)";
BA_ "SPN" SG_ 2565406702 CtrlByte_Ackm_18E8FFEE 2541;
BA_ "CI_ParId" SG_ 2565406702 Pgn_Ack_18E8FFEE "2543";
BA_ "CI_SigId" SG_ 2565406702 Pgn_Ack_18E8FFEE 11296;
BA_ "CI_SigName" SG_ 2565406702 Pgn_Ack_18E8FFEE "Parameter Group Number (ACK)";
BA_ "SPN" SG_ 2565406702 Pgn_Ack_18E8FFEE 2543;
BA_ "CI_ParId" SG_ 2565406702 Pgn_Nack_18E8FFEE "2545";
BA_ "CI_SigId" SG_ 2565406702 Pgn_Nack_18E8FFEE 11297;
BA_ "CI_SigName" SG_ 2565406702 Pgn_Nack_18E8FFEE "Parameter Group Number (NACK)";
BA_ "SPN" SG_ 2565406702 Pgn_Nack_18E8FFEE 2545;
BA_ "CI_ParId" SG_ 2565406702 Pgn_Ad_18E8FFEE "2547";
BA_ "CI_SigId" SG_ 2565406702 Pgn_Ad_18E8FFEE 11298;
BA_ "CI_SigName" SG_ 2565406702 Pgn_Ad_18E8FFEE "Parameter Group Number (NACK_AD)";
BA_ "SPN" SG_ 2565406702 Pgn_Ad_18E8FFEE 2547;
BA_ "CI_ParId" SG_ 2565406702 Pgn_Busy_18E8FFEE "2549";
BA_ "CI_SigId" SG_ 2565406702 Pgn_Busy_18E8FFEE 11299;
BA_ "CI_SigName" SG_ 2565406702 Pgn_Busy_18E8FFEE "Parameter Group Number (NACK_Busy)";
BA_ "SPN" SG_ 2565406702 Pgn_Busy_18E8FFEE 2549;
BA_ "CI_ParId" SG_ 2633959399 FunctLamp "IB838";
BA_ "CI_SigId" SG_ 2633959399 FunctLamp 12751;
BA_ "CI_SigName" SG_ 2633959399 FunctLamp "ACU_Function Lamp";
BA_ "GenSigTimeoutTime_FMS4" SG_ 2633959399 FunctLamp 500;
BA_ "GenSigTimeoutTime_MulticII" SG_ 2633959399 FunctLamp 500;
BA_ "GenSigTimeoutTime_NBM__" SG_ 2633959399 FunctLamp 500;
BA_ "GenSigTimeoutTime_NBM___" SG_ 2633959399 FunctLamp 500;
BA_ "GenSigTimeoutTime_PCM" SG_ 2633959399 FunctLamp 500;
BA_ "GenSigTimeoutTime_SGW__" SG_ 2633959399 FunctLamp 500;
BA_ "SigType" SG_ 2633959399 FunctLamp 4;
BA_ "CI_ParId" SG_ 2633959399 StopLamp "IB839";
BA_ "CI_SigId" SG_ 2633959399 StopLamp 12752;
BA_ "CI_SigName" SG_ 2633959399 StopLamp "ACU_Stop Lamp";
BA_ "GenSigTimeoutTime_FMS4" SG_ 2633959399 StopLamp 500;
BA_ "GenSigTimeoutTime_MulticII" SG_ 2633959399 StopLamp 500;
BA_ "GenSigTimeoutTime_NBM__" SG_ 2633959399 StopLamp 500;
BA_ "GenSigTimeoutTime_NBM___" SG_ 2633959399 StopLamp 500;
BA_ "GenSigTimeoutTime_PCM" SG_ 2633959399 StopLamp 500;
BA_ "GenSigTimeoutTime_SGW__" SG_ 2633959399 StopLamp 500;
BA_ "SigType" SG_ 2633959399 StopLamp 4;
BA_ "CI_ParId" SG_ 2364551072 AebsSts "5676";
BA_ "CI_SigId" SG_ 2364551072 AebsSts 364;
BA_ "CI_SigName" SG_ 2364551072 AebsSts "Forward Collision Advanced Emergency Braking System State";
BA_ "GenSigSendType" SG_ 2364551072 AebsSts 3;
BA_ "GenSigTimeoutTime_MulticS" SG_ 2364551072 AebsSts 500;
BA_ "GenSigTimeoutTime_NBM" SG_ 2364551072 AebsSts 500;
BA_ "GenSigTimeoutTime_PCM" SG_ 2364551072 AebsSts 500;
BA_ "GenSigTimeoutTime_SGW__" SG_ 2364551072 AebsSts 500;
BA_ "GenSigTimeoutTime_VCM" SG_ 2364551072 AebsSts 500;
BA_ "SPN" SG_ 2364551072 AebsSts 5676;
BA_ "CI_ParId" SG_ 2364551072 TimeToCollWithRelvObj "5680";
BA_ "CI_SigId" SG_ 2364551072 TimeToCollWithRelvObj 368;
BA_ "CI_SigName" SG_ 2364551072 TimeToCollWithRelvObj "Time to collision with relevant object";
BA_ "GenSigSendType" SG_ 2364551072 TimeToCollWithRelvObj 3;
BA_ "GenSigTimeoutTime_MulticS" SG_ 2364551072 TimeToCollWithRelvObj 500;
BA_ "GenSigTimeoutTime_PCM" SG_ 2364551072 TimeToCollWithRelvObj 500;
BA_ "GenSigTimeoutTime_SGW__" SG_ 2364551072 TimeToCollWithRelvObj 500;
BA_ "SPN" SG_ 2364551072 TimeToCollWithRelvObj 5680;
BA_ "SigType" SG_ 2364551072 TimeToCollWithRelvObj 1;
BA_ "CI_ParId" SG_ 2349572119 DrivActvDemForAebs "5681";
BA_ "CI_SigId" SG_ 2349572119 DrivActvDemForAebs 373;
BA_ "CI_SigName" SG_ 2349572119 DrivActvDemForAebs "Driver activation demand for Advanced Emergency Braking System";
BA_ "GenSigSendType" SG_ 2349572119 DrivActvDemForAebs 3;
BA_ "GenSigTimeoutTime_ADCU" SG_ 2349572119 DrivActvDemForAebs 1250;
BA_ "GenSigTimeoutTime_PCM" SG_ 2349572119 DrivActvDemForAebs 1250;
BA_ "GenSigTimeoutTime_SGW__" SG_ 2349572119 DrivActvDemForAebs 1250;
BA_ "SPN" SG_ 2349572119 DrivActvDemForAebs 5681;
BA_ "SigType" SG_ 2349572119 DrivActvDemForAebs 4;
BA_ "CI_ParId" SG_ 2566827553 ParkAnd_OrTrailAirPrs "1086";
BA_ "CI_SigId" SG_ 2566827553 ParkAnd_OrTrailAirPrs 2599;
BA_ "CI_SigName" SG_ 2566827553 ParkAnd_OrTrailAirPrs "Parking and/or Trailer Air Pressure";
BA_ "GenSigTimeoutTime_EBS" SG_ 2566827553 ParkAnd_OrTrailAirPrs 5000;
BA_ "GenSigTimeoutTime_EBS_" SG_ 2566827553 ParkAnd_OrTrailAirPrs 5000;
BA_ "GenSigTimeoutTime_EBS__" SG_ 2566827553 ParkAnd_OrTrailAirPrs 5000;
BA_ "GenSigTimeoutTime_EBS___" SG_ 2566827553 ParkAnd_OrTrailAirPrs 5000;
BA_ "GenSigTimeoutTime_MulticS" SG_ 2566827553 ParkAnd_OrTrailAirPrs 5000;
BA_ "GenSigTimeoutTime_MulticS_" SG_ 2566827553 ParkAnd_OrTrailAirPrs 5000;
BA_ "GenSigTimeoutTime_MulticS__" SG_ 2566827553 ParkAnd_OrTrailAirPrs 5000;
BA_ "GenSigTimeoutTime_PCM" SG_ 2566827553 ParkAnd_OrTrailAirPrs 5000;
BA_ "GenSigTimeoutTime_SGW__" SG_ 2566827553 ParkAnd_OrTrailAirPrs 5000;
BA_ "GenSigTimeoutTime_VCM" SG_ 2566827553 ParkAnd_OrTrailAirPrs 5000;
BA_ "SPN" SG_ 2566827553 ParkAnd_OrTrailAirPrs 1086;
BA_ "SigType" SG_ 2566827553 ParkAnd_OrTrailAirPrs 1;
BA_ "CI_ParId" SG_ 2566827553 ServBrkCirc1AirPrs "1087";
BA_ "CI_SigId" SG_ 2566827553 ServBrkCirc1AirPrs 2600;
BA_ "CI_SigName" SG_ 2566827553 ServBrkCirc1AirPrs "Service Brake Circuit 1 Air Pressure";
BA_ "GenSigTimeoutTime_EBS" SG_ 2566827553 ServBrkCirc1AirPrs 5000;
BA_ "GenSigTimeoutTime_EBS_" SG_ 2566827553 ServBrkCirc1AirPrs 5000;
BA_ "GenSigTimeoutTime_EBS__" SG_ 2566827553 ServBrkCirc1AirPrs 5000;
BA_ "GenSigTimeoutTime_EBS___" SG_ 2566827553 ServBrkCirc1AirPrs 5000;
BA_ "GenSigTimeoutTime_FMS4" SG_ 2566827553 ServBrkCirc1AirPrs 5000;
BA_ "GenSigTimeoutTime_MulticS" SG_ 2566827553 ServBrkCirc1AirPrs 5000;
BA_ "GenSigTimeoutTime_MulticS_" SG_ 2566827553 ServBrkCirc1AirPrs 5000;
BA_ "GenSigTimeoutTime_MulticS__" SG_ 2566827553 ServBrkCirc1AirPrs 5000;
BA_ "GenSigTimeoutTime_PCM" SG_ 2566827553 ServBrkCirc1AirPrs 5000;
BA_ "GenSigTimeoutTime_SGW__" SG_ 2566827553 ServBrkCirc1AirPrs 5000;
BA_ "GenSigTimeoutTime_VCM" SG_ 2566827553 ServBrkCirc1AirPrs 5000;
BA_ "SPN" SG_ 2566827553 ServBrkCirc1AirPrs 1087;
BA_ "SigType" SG_ 2566827553 ServBrkCirc1AirPrs 1;
BA_ "CI_ParId" SG_ 2566827553 ServBrkCirc2AirPrs "1088";
BA_ "CI_SigId" SG_ 2566827553 ServBrkCirc2AirPrs 2601;
BA_ "CI_SigName" SG_ 2566827553 ServBrkCirc2AirPrs "Service Brake Circuit 2 Air Pressure";
BA_ "GenSigTimeoutTime_EBS" SG_ 2566827553 ServBrkCirc2AirPrs 5000;
BA_ "GenSigTimeoutTime_EBS_" SG_ 2566827553 ServBrkCirc2AirPrs 5000;
BA_ "GenSigTimeoutTime_EBS__" SG_ 2566827553 ServBrkCirc2AirPrs 5000;
BA_ "GenSigTimeoutTime_EBS___" SG_ 2566827553 ServBrkCirc2AirPrs 5000;
BA_ "GenSigTimeoutTime_FMS4" SG_ 2566827553 ServBrkCirc2AirPrs 5000;
BA_ "GenSigTimeoutTime_MulticS" SG_ 2566827553 ServBrkCirc2AirPrs 5000;
BA_ "GenSigTimeoutTime_MulticS_" SG_ 2566827553 ServBrkCirc2AirPrs 5000;
BA_ "GenSigTimeoutTime_MulticS__" SG_ 2566827553 ServBrkCirc2AirPrs 5000;
BA_ "GenSigTimeoutTime_PCM" SG_ 2566827553 ServBrkCirc2AirPrs 5000;
BA_ "GenSigTimeoutTime_SGW__" SG_ 2566827553 ServBrkCirc2AirPrs 5000;
BA_ "GenSigTimeoutTime_VCM" SG_ 2566827553 ServBrkCirc2AirPrs 5000;
BA_ "SPN" SG_ 2566827553 ServBrkCirc2AirPrs 1088;
BA_ "SigType" SG_ 2566827553 ServBrkCirc2AirPrs 1;
BA_ "CI_ParId" SG_ 2566827553 AirSuspSupplyPrs1 "1090";
BA_ "CI_SigId" SG_ 2566827553 AirSuspSupplyPrs1 2603;
BA_ "CI_SigName" SG_ 2566827553 AirSuspSupplyPrs1 "Air Suspension Supply Pressure 1";
BA_ "GenSigTimeoutTime_EBS" SG_ 2566827553 AirSuspSupplyPrs1 5000;
BA_ "GenSigTimeoutTime_EBS_" SG_ 2566827553 AirSuspSupplyPrs1 5000;
BA_ "GenSigTimeoutTime_EBS__" SG_ 2566827553 AirSuspSupplyPrs1 5000;
BA_ "GenSigTimeoutTime_PCM" SG_ 2566827553 AirSuspSupplyPrs1 5000;
BA_ "GenSigTimeoutTime_SGW__" SG_ 2566827553 AirSuspSupplyPrs1 5000;
BA_ "GenSigTimeoutTime_VCM" SG_ 2566827553 AirSuspSupplyPrs1 5000;
BA_ "SPN" SG_ 2566827553 AirSuspSupplyPrs1 1090;
BA_ "SigType" SG_ 2566827553 AirSuspSupplyPrs1 1;
BA_ "CI_ParId" SG_ 2566827553 AirComprSts "1351";
BA_ "CI_SigId" SG_ 2566827553 AirComprSts 2604;
BA_ "CI_SigName" SG_ 2566827553 AirComprSts "Air Compressor Status";
BA_ "GenSigTimeoutTime_PCM" SG_ 2566827553 AirComprSts 5000;
BA_ "GenSigTimeoutTime_SGW__" SG_ 2566827553 AirComprSts 5000;
BA_ "GenSigTimeoutTime_VCM" SG_ 2566827553 AirComprSts 5000;
BA_ "SPN" SG_ 2566827553 AirComprSts 1351;
BA_ "SigType" SG_ 2566827553 AirComprSts 4;
BA_ "CI_ParId" SG_ 2566620766 CAID2Sts "IB657";
BA_ "CI_SigId" SG_ 2566620766 CAID2Sts 13527;
BA_ "CI_SigName" SG_ 2566620766 CAID2Sts "CAID2 Status";
BA_ "GenSigTimeoutTime_MulticS" SG_ 2566620766 CAID2Sts 1000;
BA_ "GenSigTimeoutTime_MulticS_" SG_ 2566620766 CAID2Sts 1000;
BA_ "GenSigTimeoutTime_NBM" SG_ 2566620766 CAID2Sts 1000;
BA_ "GenSigTimeoutTime_NBM_" SG_ 2566620766 CAID2Sts 1000;
BA_ "GenSigTimeoutTime_NBM__" SG_ 2566620766 CAID2Sts 1000;
BA_ "GenSigTimeoutTime_NBM___" SG_ 2566620766 CAID2Sts 1000;
BA_ "GenSigTimeoutTime_PCM" SG_ 2566620766 CAID2Sts 1000;
BA_ "GenSigTimeoutTime_SGW__" SG_ 2566620766 CAID2Sts 1000;
BA_ "CI_ParId" SG_ 2566620766 CAID2EngStartRollingSit "IB658";
BA_ "CI_SigId" SG_ 2566620766 CAID2EngStartRollingSit 13528;
BA_ "CI_SigName" SG_ 2566620766 CAID2EngStartRollingSit "CAID2 Engine Start / Rolling situation";
BA_ "GenSigTimeoutTime_MulticS" SG_ 2566620766 CAID2EngStartRollingSit 1000;
BA_ "GenSigTimeoutTime_MulticS_" SG_ 2566620766 CAID2EngStartRollingSit 1000;
BA_ "GenSigTimeoutTime_NBM" SG_ 2566620766 CAID2EngStartRollingSit 1000;
BA_ "GenSigTimeoutTime_NBM_" SG_ 2566620766 CAID2EngStartRollingSit 1000;
BA_ "GenSigTimeoutTime_NBM__" SG_ 2566620766 CAID2EngStartRollingSit 1000;
BA_ "GenSigTimeoutTime_NBM___" SG_ 2566620766 CAID2EngStartRollingSit 1000;
BA_ "GenSigTimeoutTime_PCM" SG_ 2566620766 CAID2EngStartRollingSit 1000;
BA_ "GenSigTimeoutTime_SGW__" SG_ 2566620766 CAID2EngStartRollingSit 1000;
BA_ "CI_ParId" SG_ 2566620766 Data4 "IB659";
BA_ "CI_SigId" SG_ 2566620766 Data4 13529;
BA_ "CI_SigName" SG_ 2566620766 Data4 "Data4";
BA_ "GenSigTimeoutTime_MulticS" SG_ 2566620766 Data4 1000;
BA_ "GenSigTimeoutTime_MulticS_" SG_ 2566620766 Data4 1000;
BA_ "GenSigTimeoutTime_NBM" SG_ 2566620766 Data4 1000;
BA_ "GenSigTimeoutTime_NBM_" SG_ 2566620766 Data4 1000;
BA_ "GenSigTimeoutTime_NBM__" SG_ 2566620766 Data4 1000;
BA_ "GenSigTimeoutTime_NBM___" SG_ 2566620766 Data4 1000;
BA_ "GenSigTimeoutTime_PCM" SG_ 2566620766 Data4 1000;
BA_ "GenSigTimeoutTime_SGW__" SG_ 2566620766 Data4 1000;
BA_ "CI_ParId" SG_ 2566620766 Data6 "IB660";
BA_ "CI_SigId" SG_ 2566620766 Data6 13530;
BA_ "CI_SigName" SG_ 2566620766 Data6 "Data6";
BA_ "GenSigTimeoutTime_MulticS" SG_ 2566620766 Data6 1000;
BA_ "GenSigTimeoutTime_MulticS_" SG_ 2566620766 Data6 1000;
BA_ "GenSigTimeoutTime_NBM" SG_ 2566620766 Data6 1000;
BA_ "GenSigTimeoutTime_NBM_" SG_ 2566620766 Data6 1000;
BA_ "GenSigTimeoutTime_NBM__" SG_ 2566620766 Data6 1000;
BA_ "GenSigTimeoutTime_NBM___" SG_ 2566620766 Data6 1000;
BA_ "GenSigTimeoutTime_PCM" SG_ 2566620766 Data6 1000;
BA_ "GenSigTimeoutTime_SGW__" SG_ 2566620766 Data6 1000;
BA_ "CI_ParId" SG_ 2566620766 Data7 "IB661";
BA_ "CI_SigId" SG_ 2566620766 Data7 13531;
BA_ "CI_SigName" SG_ 2566620766 Data7 "Data7";
BA_ "GenSigTimeoutTime_MulticS" SG_ 2566620766 Data7 1000;
BA_ "GenSigTimeoutTime_MulticS_" SG_ 2566620766 Data7 1000;
BA_ "GenSigTimeoutTime_NBM" SG_ 2566620766 Data7 1000;
BA_ "GenSigTimeoutTime_NBM_" SG_ 2566620766 Data7 1000;
BA_ "GenSigTimeoutTime_NBM__" SG_ 2566620766 Data7 1000;
BA_ "GenSigTimeoutTime_NBM___" SG_ 2566620766 Data7 1000;
BA_ "GenSigTimeoutTime_PCM" SG_ 2566620766 Data7 1000;
BA_ "GenSigTimeoutTime_SGW__" SG_ 2566620766 Data7 1000;
BA_ "CI_ParId" SG_ 2566845696 BaromPrs "108";
BA_ "CI_SigId" SG_ 2566845696 BaromPrs 2025;
BA_ "CI_SigName" SG_ 2566845696 BaromPrs "Barometric Pressure";
BA_ "GenSigTimeoutTime_PCM" SG_ 2566845696 BaromPrs 5000;
BA_ "GenSigTimeoutTime_SGW__" SG_ 2566845696 BaromPrs 5000;
BA_ "GenSigTimeoutTime_TPMS" SG_ 2566845696 BaromPrs 5000;
BA_ "GenSigTimeoutTime_VCM_" SG_ 2566845696 BaromPrs 5000;
BA_ "GenSigTimeoutTime_VCM__" SG_ 2566845696 BaromPrs 5000;
BA_ "SPN" SG_ 2566845696 BaromPrs 108;
BA_ "SigType" SG_ 2566845696 BaromPrs 1;
BA_ "CI_ParId" SG_ 2566845696 AmbAirTemp "171";
BA_ "CI_SigId" SG_ 2566845696 AmbAirTemp 2027;
BA_ "CI_SigName" SG_ 2566845696 AmbAirTemp "Ambient Air Temperature";
BA_ "GenSigTimeoutTime_EBS__" SG_ 2566845696 AmbAirTemp 5000;
BA_ "GenSigTimeoutTime_EBS___" SG_ 2566845696 AmbAirTemp 5000;
BA_ "GenSigTimeoutTime_ETS" SG_ 2566845696 AmbAirTemp 5000;
BA_ "GenSigTimeoutTime_Ecolife2" SG_ 2566845696 AmbAirTemp 5000;
BA_ "GenSigTimeoutTime_FMS4" SG_ 2566845696 AmbAirTemp 5000;
BA_ "GenSigTimeoutTime_PCM" SG_ 2566845696 AmbAirTemp 5000;
BA_ "GenSigTimeoutTime_SGW__" SG_ 2566845696 AmbAirTemp 5000;
BA_ "GenSigTimeoutTime_VCM_" SG_ 2566845696 AmbAirTemp 5000;
BA_ "GenSigTimeoutTime_VCM__" SG_ 2566845696 AmbAirTemp 5000;
BA_ "SPN" SG_ 2566845696 AmbAirTemp 171;
BA_ "SigType" SG_ 2566845696 AmbAirTemp 1;
BA_ "CI_ParId" SG_ 2566845696 EngIn1AirTemp "172";
BA_ "CI_SigId" SG_ 2566845696 EngIn1AirTemp 2028;
BA_ "CI_SigName" SG_ 2566845696 EngIn1AirTemp "Engine Intake 1 Air Temperature";
BA_ "GenSigTimeoutTime_PCM" SG_ 2566845696 EngIn1AirTemp 5000;
BA_ "GenSigTimeoutTime_SGW__" SG_ 2566845696 EngIn1AirTemp 5000;
BA_ "GenSigTimeoutTime_VCM_" SG_ 2566845696 EngIn1AirTemp 5000;
BA_ "GenSigTimeoutTime_VCM__" SG_ 2566845696 EngIn1AirTemp 5000;
BA_ "SPN" SG_ 2566845696 EngIn1AirTemp 172;
BA_ "SigType" SG_ 2566845696 EngIn1AirTemp 1;
BA_ "CI_ParId" SG_ 2566845719 AmbAirTemp_18FEF517 "171";
BA_ "CI_SigId" SG_ 2566845719 AmbAirTemp_18FEF517 2033;
BA_ "CI_SigName" SG_ 2566845719 AmbAirTemp_18FEF517 "Ambient Air Temperature";
BA_ "GenSigTimeoutTime_CANAIR" SG_ 2566845719 AmbAirTemp_18FEF517 5000;
BA_ "GenSigTimeoutTime_EBS" SG_ 2566845719 AmbAirTemp_18FEF517 5000;
BA_ "GenSigTimeoutTime_EBS_" SG_ 2566845719 AmbAirTemp_18FEF517 5000;
BA_ "GenSigTimeoutTime_EBS__" SG_ 2566845719 AmbAirTemp_18FEF517 5000;
BA_ "GenSigTimeoutTime_EBS___" SG_ 2566845719 AmbAirTemp_18FEF517 5000;
BA_ "GenSigTimeoutTime_MulticS__" SG_ 2566845719 AmbAirTemp_18FEF517 5000;
BA_ "GenSigTimeoutTime_NBM" SG_ 2566845719 AmbAirTemp_18FEF517 5000;
BA_ "GenSigTimeoutTime_NBM_" SG_ 2566845719 AmbAirTemp_18FEF517 5000;
BA_ "GenSigTimeoutTime_PCM" SG_ 2566845719 AmbAirTemp_18FEF517 5000;
BA_ "GenSigTimeoutTime_SGW__" SG_ 2566845719 AmbAirTemp_18FEF517 5000;
BA_ "GenSigTimeoutTime_VCU_" SG_ 2566845719 AmbAirTemp_18FEF517 5000;
BA_ "GenSigTimeoutTime_VMU" SG_ 2566845719 AmbAirTemp_18FEF517 5000;
BA_ "SPN" SG_ 2566845719 AmbAirTemp_18FEF517 171;
BA_ "SigType" SG_ 2566845719 AmbAirTemp_18FEF517 1;
BA_ "CI_ParId" SG_ 2565920602 Dc_AcAccsInv1Freq "8337";
BA_ "CI_SigId" SG_ 2565920602 Dc_AcAccsInv1Freq 2059;
BA_ "CI_SigName" SG_ 2565920602 Dc_AcAccsInv1Freq "DC/AC Accessory Inverter 1 Frequency";
BA_ "GenSigTimeoutTime_FMS4" SG_ 2565920602 Dc_AcAccsInv1Freq 500;
BA_ "GenSigTimeoutTime_NBM_" SG_ 2565920602 Dc_AcAccsInv1Freq 500;
BA_ "GenSigTimeoutTime_NBM__" SG_ 2565920602 Dc_AcAccsInv1Freq 500;
BA_ "GenSigTimeoutTime_PCM" SG_ 2565920602 Dc_AcAccsInv1Freq 500;
BA_ "GenSigTimeoutTime_SGW__" SG_ 2565920602 Dc_AcAccsInv1Freq 500;
BA_ "SPN" SG_ 2565920602 Dc_AcAccsInv1Freq 8337;
BA_ "SigType" SG_ 2565920602 Dc_AcAccsInv1Freq 1;
BA_ "CI_ParId" SG_ 2566837527 Altern1Sts "3353";
BA_ "CI_SigId" SG_ 2566837527 Altern1Sts 2201;
BA_ "CI_SigName" SG_ 2566837527 Altern1Sts "Alternator 1 Status";
BA_ "GenSigTimeoutTime_FMS4" SG_ 2566837527 Altern1Sts 5000;
BA_ "GenSigTimeoutTime_PCM" SG_ 2566837527 Altern1Sts 5000;
BA_ "GenSigTimeoutTime_SGW__" SG_ 2566837527 Altern1Sts 5000;
BA_ "SPN" SG_ 2566837527 Altern1Sts 3353;
BA_ "SigType" SG_ 2566837527 Altern1Sts 4;
BA_ "CI_ParId" SG_ 2566837527 Altern2Sts "3354";
BA_ "CI_SigId" SG_ 2566837527 Altern2Sts 2202;
BA_ "CI_SigName" SG_ 2566837527 Altern2Sts "Alternator 2 Status";
BA_ "GenSigTimeoutTime_FMS4" SG_ 2566837527 Altern2Sts 5000;
BA_ "GenSigTimeoutTime_PCM" SG_ 2566837527 Altern2Sts 5000;
BA_ "GenSigTimeoutTime_SGW__" SG_ 2566837527 Altern2Sts 5000;
BA_ "SPN" SG_ 2566837527 Altern2Sts 3354;
BA_ "SigType" SG_ 2566837527 Altern2Sts 4;
BA_ "CI_ParId" SG_ 2566837527 Altern3Sts "3355";
BA_ "CI_SigId" SG_ 2566837527 Altern3Sts 2203;
BA_ "CI_SigName" SG_ 2566837527 Altern3Sts "Alternator 3 Status";
BA_ "GenSigTimeoutTime_FMS4" SG_ 2566837527 Altern3Sts 5000;
BA_ "GenSigTimeoutTime_PCM" SG_ 2566837527 Altern3Sts 5000;
BA_ "GenSigTimeoutTime_SGW__" SG_ 2566837527 Altern3Sts 5000;
BA_ "SPN" SG_ 2566837527 Altern3Sts 3355;
BA_ "SigType" SG_ 2566837527 Altern3Sts 4;
BA_ "CI_ParId" SG_ 2365479471 KneelInfo "1742";
BA_ "CI_SigId" SG_ 2365479471 KneelInfo 3023;
BA_ "CI_SigName" SG_ 2365479471 KneelInfo "Kneeling Information";
BA_ "GenSigTimeoutTime_NBM" SG_ 2365479471 KneelInfo 500;
BA_ "GenSigTimeoutTime_NBM_" SG_ 2365479471 KneelInfo 500;
BA_ "GenSigTimeoutTime_NBM__" SG_ 2365479471 KneelInfo 500;
BA_ "GenSigTimeoutTime_NBM___" SG_ 2365479471 KneelInfo 500;
BA_ "GenSigTimeoutTime_PCM" SG_ 2365479471 KneelInfo 500;
BA_ "GenSigTimeoutTime_SGW__" SG_ 2365479471 KneelInfo 500;
BA_ "GenSigTimeoutTime_VCM" SG_ 2365479471 KneelInfo 500;
BA_ "SPN" SG_ 2365479471 KneelInfo 1742;
BA_ "CI_ParId" SG_ 2365479488 KneelInfo_0CFE5A40 "1742";
BA_ "CI_SigId" SG_ 2365479488 KneelInfo_0CFE5A40 3049;
BA_ "CI_SigName" SG_ 2365479488 KneelInfo_0CFE5A40 "Kneeling Information";
BA_ "GenSigTimeoutTime_NBM__" SG_ 2365479488 KneelInfo_0CFE5A40 500;
BA_ "GenSigTimeoutTime_NBM___" SG_ 2365479488 KneelInfo_0CFE5A40 500;
BA_ "GenSigTimeoutTime_PCM" SG_ 2365479488 KneelInfo_0CFE5A40 500;
BA_ "GenSigTimeoutTime_SGW__" SG_ 2365479488 KneelInfo_0CFE5A40 500;
BA_ "SPN" SG_ 2365479488 KneelInfo_0CFE5A40 1742;
BA_ "CI_ParId" SG_ 2566805807 RelLevFaL "1721";
BA_ "CI_SigId" SG_ 2566805807 RelLevFaL 3080;
BA_ "CI_SigName" SG_ 2566805807 RelLevFaL "Relative Level Front Axle Left";
BA_ "GenSigTimeoutTime_PCM" SG_ 2566805807 RelLevFaL 500;
BA_ "GenSigTimeoutTime_SGW__" SG_ 2566805807 RelLevFaL 500;
BA_ "SPN" SG_ 2566805807 RelLevFaL 1721;
BA_ "SigType" SG_ 2566805807 RelLevFaL 1;
BA_ "CI_ParId" SG_ 2566805807 RelLevFaR "1722";
BA_ "CI_SigId" SG_ 2566805807 RelLevFaR 3081;
BA_ "CI_SigName" SG_ 2566805807 RelLevFaR "Relative Level Front Axle Right";
BA_ "GenSigTimeoutTime_PCM" SG_ 2566805807 RelLevFaR 500;
BA_ "GenSigTimeoutTime_SGW__" SG_ 2566805807 RelLevFaR 500;
BA_ "SPN" SG_ 2566805807 RelLevFaR 1722;
BA_ "SigType" SG_ 2566805807 RelLevFaR 1;
BA_ "CI_ParId" SG_ 2566805807 RelLevRaL "1724";
BA_ "CI_SigId" SG_ 2566805807 RelLevRaL 3082;
BA_ "CI_SigName" SG_ 2566805807 RelLevRaL "Relative Level Rear Axle Left";
BA_ "GenSigTimeoutTime_PCM" SG_ 2566805807 RelLevRaL 500;
BA_ "GenSigTimeoutTime_SGW__" SG_ 2566805807 RelLevRaL 500;
BA_ "SPN" SG_ 2566805807 RelLevRaL 1724;
BA_ "SigType" SG_ 2566805807 RelLevRaL 1;
BA_ "CI_ParId" SG_ 2566805807 RelLevRaR "1723";
BA_ "CI_SigId" SG_ 2566805807 RelLevRaR 3083;
BA_ "CI_SigName" SG_ 2566805807 RelLevRaR "Relative Level Rear Axle Right";
BA_ "GenSigTimeoutTime_PCM" SG_ 2566805807 RelLevRaR 500;
BA_ "GenSigTimeoutTime_SGW__" SG_ 2566805807 RelLevRaR 500;
BA_ "SPN" SG_ 2566805807 RelLevRaR 1723;
BA_ "SigType" SG_ 2566805807 RelLevRaR 1;
BA_ "CI_ParId" SG_ 2566805824 RelLevRaR_18FE5940 "1723";
BA_ "CI_SigId" SG_ 2566805824 RelLevRaR_18FE5940 3087;
BA_ "CI_SigName" SG_ 2566805824 RelLevRaR_18FE5940 "Relative Level Rear Axle Right";
BA_ "GenSigTimeoutTime_PCM" SG_ 2566805824 RelLevRaR_18FE5940 500;
BA_ "GenSigTimeoutTime_SGW__" SG_ 2566805824 RelLevRaR_18FE5940 500;
BA_ "SPN" SG_ 2566805824 RelLevRaR_18FE5940 1723;
BA_ "SigType" SG_ 2566805824 RelLevRaR_18FE5940 1;
BA_ "CI_ParId" SG_ 2566805824 RelLevRaL_18FE5940 "1724";
BA_ "CI_SigId" SG_ 2566805824 RelLevRaL_18FE5940 3088;
BA_ "CI_SigName" SG_ 2566805824 RelLevRaL_18FE5940 "Relative Level Rear Axle Left";
BA_ "GenSigTimeoutTime_PCM" SG_ 2566805824 RelLevRaL_18FE5940 500;
BA_ "GenSigTimeoutTime_SGW__" SG_ 2566805824 RelLevRaL_18FE5940 500;
BA_ "SPN" SG_ 2566805824 RelLevRaL_18FE5940 1724;
BA_ "SigType" SG_ 2566805824 RelLevRaL_18FE5940 1;
BA_ "CI_ParId" SG_ 2566805551 BellowPrsFaL "1725";
BA_ "CI_SigId" SG_ 2566805551 BellowPrsFaL 3090;
BA_ "CI_SigName" SG_ 2566805551 BellowPrsFaL "Bellow Pressure Front Axle Left";
BA_ "GenSigTimeoutTime_FMS4" SG_ 2566805551 BellowPrsFaL 500;
BA_ "GenSigTimeoutTime_PCM" SG_ 2566805551 BellowPrsFaL 500;
BA_ "GenSigTimeoutTime_SGW__" SG_ 2566805551 BellowPrsFaL 500;
BA_ "SPN" SG_ 2566805551 BellowPrsFaL 1725;
BA_ "SigType" SG_ 2566805551 BellowPrsFaL 1;
BA_ "CI_ParId" SG_ 2566805551 BellowPrsFaR "1726";
BA_ "CI_SigId" SG_ 2566805551 BellowPrsFaR 3091;
BA_ "CI_SigName" SG_ 2566805551 BellowPrsFaR "Bellow Pressure Front Axle Right";
BA_ "GenSigTimeoutTime_FMS4" SG_ 2566805551 BellowPrsFaR 500;
BA_ "GenSigTimeoutTime_PCM" SG_ 2566805551 BellowPrsFaR 500;
BA_ "GenSigTimeoutTime_SGW__" SG_ 2566805551 BellowPrsFaR 500;
BA_ "SPN" SG_ 2566805551 BellowPrsFaR 1726;
BA_ "SigType" SG_ 2566805551 BellowPrsFaR 1;
BA_ "CI_ParId" SG_ 2566805551 BellowPrsRaL "1727";
BA_ "CI_SigId" SG_ 2566805551 BellowPrsRaL 3092;
BA_ "CI_SigName" SG_ 2566805551 BellowPrsRaL "Bellow Pressure Rear Axle Left";
BA_ "GenSigTimeoutTime_FMS4" SG_ 2566805551 BellowPrsRaL 500;
BA_ "GenSigTimeoutTime_PCM" SG_ 2566805551 BellowPrsRaL 500;
BA_ "GenSigTimeoutTime_SGW__" SG_ 2566805551 BellowPrsRaL 500;
BA_ "SPN" SG_ 2566805551 BellowPrsRaL 1727;
BA_ "SigType" SG_ 2566805551 BellowPrsRaL 1;
BA_ "CI_ParId" SG_ 2566805551 BellowPrsRaR "1728";
BA_ "CI_SigId" SG_ 2566805551 BellowPrsRaR 3093;
BA_ "CI_SigName" SG_ 2566805551 BellowPrsRaR "Bellow Pressure Rear Axle Right";
BA_ "GenSigTimeoutTime_FMS4" SG_ 2566805551 BellowPrsRaR 500;
BA_ "GenSigTimeoutTime_PCM" SG_ 2566805551 BellowPrsRaR 500;
BA_ "GenSigTimeoutTime_SGW__" SG_ 2566805551 BellowPrsRaR 500;
BA_ "SPN" SG_ 2566805551 BellowPrsRaR 1728;
BA_ "SigType" SG_ 2566805551 BellowPrsRaR 1;
BA_ "CI_ParId" SG_ 2566805568 BellowPrsRaL_18FE5840 "1727";
BA_ "CI_SigId" SG_ 2566805568 BellowPrsRaL_18FE5840 3097;
BA_ "CI_SigName" SG_ 2566805568 BellowPrsRaL_18FE5840 "Bellow Pressure Rear Axle Left";
BA_ "GenSigTimeoutTime_PCM" SG_ 2566805568 BellowPrsRaL_18FE5840 500;
BA_ "GenSigTimeoutTime_SGW__" SG_ 2566805568 BellowPrsRaL_18FE5840 500;
BA_ "SPN" SG_ 2566805568 BellowPrsRaL_18FE5840 1727;
BA_ "SigType" SG_ 2566805568 BellowPrsRaL_18FE5840 1;
BA_ "CI_ParId" SG_ 2566805568 BellowPrsRaR_18FE5840 "1728";
BA_ "CI_SigId" SG_ 2566805568 BellowPrsRaR_18FE5840 3098;
BA_ "CI_SigName" SG_ 2566805568 BellowPrsRaR_18FE5840 "Bellow Pressure Rear Axle Right";
BA_ "GenSigTimeoutTime_PCM" SG_ 2566805568 BellowPrsRaR_18FE5840 500;
BA_ "GenSigTimeoutTime_SGW__" SG_ 2566805568 BellowPrsRaR_18FE5840 500;
BA_ "SPN" SG_ 2566805568 BellowPrsRaR_18FE5840 1728;
BA_ "SigType" SG_ 2566805568 BellowPrsRaR_18FE5840 1;
BA_ "CI_ParId" SG_ 2566763520 At1DpfInTemp "3242";
BA_ "CI_SigId" SG_ 2566763520 At1DpfInTemp 1228;
BA_ "CI_SigName" SG_ 2566763520 At1DpfInTemp "Aftertreatment 1 Diesel Particulate Filter Intake Temperature";
BA_ "GenSigTimeoutTime_PCM" SG_ 2566763520 At1DpfInTemp 2500;
BA_ "SPN" SG_ 2566763520 At1DpfInTemp 3242;
BA_ "SigType" SG_ 2566763520 At1DpfInTemp 1;
BA_ "CI_ParId" SG_ 2566804992 At1DefTankVol "1761";
BA_ "CI_SigId" SG_ 2566804992 At1DefTankVol 1246;
BA_ "CI_SigName" SG_ 2566804992 At1DefTankVol "Aftertreatment 1 Diesel Exhaust Fluid Tank Volume";
BA_ "GenSigTimeoutTime_FMS4" SG_ 2566804992 At1DefTankVol 5000;
BA_ "GenSigTimeoutTime_MulticS" SG_ 2566804992 At1DefTankVol 5000;
BA_ "GenSigTimeoutTime_MulticS__" SG_ 2566804992 At1DefTankVol 5000;
BA_ "GenSigTimeoutTime_PCM" SG_ 2566804992 At1DefTankVol 5000;
BA_ "GenSigTimeoutTime_SGW__" SG_ 2566804992 At1DefTankVol 5000;
BA_ "GenSigTimeoutTime_VCM_" SG_ 2566804992 At1DefTankVol 5000;
BA_ "SPN" SG_ 2566804992 At1DefTankVol 1761;
BA_ "SigType" SG_ 2566804992 At1DefTankVol 1;
BA_ "CI_ParId" SG_ 2566804992 At1DefTankTemp1 "3031";
BA_ "CI_SigId" SG_ 2566804992 At1DefTankTemp1 1247;
BA_ "CI_SigName" SG_ 2566804992 At1DefTankTemp1 "Aftertreatment 1 Diesel Exhaust Fluid Tank Temperature 1";
BA_ "GenSigTimeoutTime_NBM" SG_ 2566804992 At1DefTankTemp1 5000;
BA_ "GenSigTimeoutTime_PCM" SG_ 2566804992 At1DefTankTemp1 5000;
BA_ "GenSigTimeoutTime_SGW__" SG_ 2566804992 At1DefTankTemp1 5000;
BA_ "GenSigTimeoutTime_VCM_" SG_ 2566804992 At1DefTankTemp1 5000;
BA_ "SPN" SG_ 2566804992 At1DefTankTemp1 3031;
BA_ "SigType" SG_ 2566804992 At1DefTankTemp1 1;
BA_ "CI_ParId" SG_ 2566804992 AtScrOpInducSev "5246";
BA_ "CI_SigId" SG_ 2566804992 AtScrOpInducSev 1252;
BA_ "CI_SigName" SG_ 2566804992 AtScrOpInducSev "Aftertreatment SCR Operator Inducement Severity";
BA_ "GenSigTimeoutTime_MulticS" SG_ 2566804992 AtScrOpInducSev 5000;
BA_ "GenSigTimeoutTime_MulticS__" SG_ 2566804992 AtScrOpInducSev 5000;
BA_ "GenSigTimeoutTime_PCM" SG_ 2566804992 AtScrOpInducSev 5000;
BA_ "GenSigTimeoutTime_SGW__" SG_ 2566804992 AtScrOpInducSev 5000;
BA_ "GenSigTimeoutTime_VCM_" SG_ 2566804992 AtScrOpInducSev 5000;
BA_ "SPN" SG_ 2566804992 AtScrOpInducSev 5246;
BA_ "CI_ParId" SG_ 2566849271 PulseEna "IB059";
BA_ "CI_SigId" SG_ 2566849271 PulseEna 1256;
BA_ "CI_SigName" SG_ 2566849271 PulseEna "Pulse enable";
BA_ "GenSigTimeoutTime_PCM" SG_ 2566849271 PulseEna 500;
BA_ "GenSigTimeoutTime_VCU" SG_ 2566849271 PulseEna 500;
BA_ "SigType" SG_ 2566849271 PulseEna 4;
BA_ "CI_ParId" SG_ 2566849271 ErrSts "IB060";
BA_ "CI_SigId" SG_ 2566849271 ErrSts 1257;
BA_ "CI_SigName" SG_ 2566849271 ErrSts "Error Status";
BA_ "GenSigTimeoutTime_PCM" SG_ 2566849271 ErrSts 500;
BA_ "GenSigTimeoutTime_VCU" SG_ 2566849271 ErrSts 500;
BA_ "SigType" SG_ 2566849271 ErrSts 4;
BA_ "CI_ParId" SG_ 2566849271 _24DcdcOutV "IB061";
BA_ "CI_SigId" SG_ 2566849271 _24DcdcOutV 1258;
BA_ "CI_SigName" SG_ 2566849271 _24DcdcOutV "24 DCDC Output_Voltage";
BA_ "GenSigTimeoutTime_PCM" SG_ 2566849271 _24DcdcOutV 500;
BA_ "GenSigTimeoutTime_VCU" SG_ 2566849271 _24DcdcOutV 500;
BA_ "SigType" SG_ 2566849271 _24DcdcOutV 1;
BA_ "CI_ParId" SG_ 2566849271 Cur "IB062";
BA_ "CI_SigId" SG_ 2566849271 Cur 1259;
BA_ "CI_SigName" SG_ 2566849271 Cur "Current";
BA_ "GenSigTimeoutTime_PCM" SG_ 2566849271 Cur 500;
BA_ "GenSigTimeoutTime_VCU" SG_ 2566849271 Cur 500;
BA_ "SigType" SG_ 2566849271 Cur 1;
BA_ "CI_ParId" SG_ 2566849271 Pwr "IB063";
BA_ "CI_SigId" SG_ 2566849271 Pwr 1260;
BA_ "CI_SigName" SG_ 2566849271 Pwr "Power";
BA_ "GenSigTimeoutTime_PCM" SG_ 2566849271 Pwr 500;
BA_ "GenSigTimeoutTime_VCU" SG_ 2566849271 Pwr 500;
BA_ "SigType" SG_ 2566849271 Pwr 1;
BA_ "CI_ParId" SG_ 2566849015 PulseEna_18FF01F7 "IB059";
BA_ "CI_SigId" SG_ 2566849015 PulseEna_18FF01F7 1262;
BA_ "CI_SigName" SG_ 2566849015 PulseEna_18FF01F7 "Pulse enable";
BA_ "GenSigTimeoutTime_PCM" SG_ 2566849015 PulseEna_18FF01F7 500;
BA_ "GenSigTimeoutTime_VCU" SG_ 2566849015 PulseEna_18FF01F7 500;
BA_ "SigType" SG_ 2566849015 PulseEna_18FF01F7 4;
BA_ "CI_ParId" SG_ 2566849015 ErrSts_18FF01F7 "IB060";
BA_ "CI_SigId" SG_ 2566849015 ErrSts_18FF01F7 1263;
BA_ "CI_SigName" SG_ 2566849015 ErrSts_18FF01F7 "Error Status";
BA_ "GenSigTimeoutTime_PCM" SG_ 2566849015 ErrSts_18FF01F7 500;
BA_ "GenSigTimeoutTime_VCU" SG_ 2566849015 ErrSts_18FF01F7 500;
BA_ "SigType" SG_ 2566849015 ErrSts_18FF01F7 4;
BA_ "CI_ParId" SG_ 2566849015 Aux2s "IB064";
BA_ "CI_SigId" SG_ 2566849015 Aux2s 1264;
BA_ "CI_SigName" SG_ 2566849015 Aux2s "Aux 2 Speed";
BA_ "GenSigTimeoutTime_PCM" SG_ 2566849015 Aux2s 500;
BA_ "GenSigTimeoutTime_VCU" SG_ 2566849015 Aux2s 500;
BA_ "SigType" SG_ 2566849015 Aux2s 1;
BA_ "CI_ParId" SG_ 2566849015 Aux2Pwr "IB065";
BA_ "CI_SigId" SG_ 2566849015 Aux2Pwr 1265;
BA_ "CI_SigName" SG_ 2566849015 Aux2Pwr "Aux 2 Power";
BA_ "GenSigTimeoutTime_PCM" SG_ 2566849015 Aux2Pwr 500;
BA_ "GenSigTimeoutTime_VCU" SG_ 2566849015 Aux2Pwr 500;
BA_ "SigType" SG_ 2566849015 Aux2Pwr 1;
BA_ "CI_ParId" SG_ 2566848759 Term15Sts "IB066";
BA_ "CI_SigId" SG_ 2566848759 Term15Sts 1267;
BA_ "CI_SigName" SG_ 2566848759 Term15Sts "Terminal 15 Status";
BA_ "GenSigTimeoutTime_PCM" SG_ 2566848759 Term15Sts 500;
BA_ "GenSigTimeoutTime_VCU" SG_ 2566848759 Term15Sts 500;
BA_ "SigType" SG_ 2566848759 Term15Sts 4;
BA_ "CI_ParId" SG_ 2566848759 DcLinkV "IB067";
BA_ "CI_SigId" SG_ 2566848759 DcLinkV 1268;
BA_ "CI_SigName" SG_ 2566848759 DcLinkV "DC Link Voltage";
BA_ "GenSigTimeoutTime_PCM" SG_ 2566848759 DcLinkV 500;
BA_ "GenSigTimeoutTime_VCU" SG_ 2566848759 DcLinkV 500;
BA_ "SigType" SG_ 2566848759 DcLinkV 1;
BA_ "CI_ParId" SG_ 2566849270 PulseEna_18FF02F6 "IB059";
BA_ "CI_SigId" SG_ 2566849270 PulseEna_18FF02F6 1270;
BA_ "CI_SigName" SG_ 2566849270 PulseEna_18FF02F6 "Pulse enable";
BA_ "GenSigTimeoutTime_PCM" SG_ 2566849270 PulseEna_18FF02F6 500;
BA_ "GenSigTimeoutTime_VCU" SG_ 2566849270 PulseEna_18FF02F6 500;
BA_ "SigType" SG_ 2566849270 PulseEna_18FF02F6 4;
BA_ "CI_ParId" SG_ 2566849270 ErrSts_18FF02F6 "IB060";
BA_ "CI_SigId" SG_ 2566849270 ErrSts_18FF02F6 1271;
BA_ "CI_SigName" SG_ 2566849270 ErrSts_18FF02F6 "Error Status";
BA_ "GenSigTimeoutTime_PCM" SG_ 2566849270 ErrSts_18FF02F6 500;
BA_ "GenSigTimeoutTime_VCU" SG_ 2566849270 ErrSts_18FF02F6 500;
BA_ "SigType" SG_ 2566849270 ErrSts_18FF02F6 4;
BA_ "CI_ParId" SG_ 2566849270 _24DcdcOutV_18FF02F6 "IB061";
BA_ "CI_SigId" SG_ 2566849270 _24DcdcOutV_18FF02F6 1272;
BA_ "CI_SigName" SG_ 2566849270 _24DcdcOutV_18FF02F6 "24 DCDC Output_Voltage";
BA_ "GenSigTimeoutTime_PCM" SG_ 2566849270 _24DcdcOutV_18FF02F6 500;
BA_ "GenSigTimeoutTime_VCU" SG_ 2566849270 _24DcdcOutV_18FF02F6 500;
BA_ "SigType" SG_ 2566849270 _24DcdcOutV_18FF02F6 1;
BA_ "CI_ParId" SG_ 2566849270 Cur_18FF02F6 "IB062";
BA_ "CI_SigId" SG_ 2566849270 Cur_18FF02F6 1273;
BA_ "CI_SigName" SG_ 2566849270 Cur_18FF02F6 "Current";
BA_ "GenSigTimeoutTime_PCM" SG_ 2566849270 Cur_18FF02F6 500;
BA_ "GenSigTimeoutTime_VCU" SG_ 2566849270 Cur_18FF02F6 500;
BA_ "SigType" SG_ 2566849270 Cur_18FF02F6 1;
BA_ "CI_ParId" SG_ 2566849270 Pwr_18FF02F6 "IB063";
BA_ "CI_SigId" SG_ 2566849270 Pwr_18FF02F6 1274;
BA_ "CI_SigName" SG_ 2566849270 Pwr_18FF02F6 "Power";
BA_ "GenSigTimeoutTime_PCM" SG_ 2566849270 Pwr_18FF02F6 500;
BA_ "GenSigTimeoutTime_VCU" SG_ 2566849270 Pwr_18FF02F6 500;
BA_ "SigType" SG_ 2566849270 Pwr_18FF02F6 1;
VAL_ 2566811431 AccMode 0 "Off, Standby, enabled" 1 "Speed control active" 2 "Distance control active" 3 "Overtake mode" 4 "Hold mode" 5 "Finish mode" 6 "Disabled or error condition" 7 "Not Available/not valid" ;
VAL_ 2566811431 AccSetDistMode 0 "Mode #1, largest distance" 1 "Mode #2" 2 "Mode #3" 3 "Mode #4" 4 "Mode #5,shortest distance" 5 "Conventional CC mode" 6 "Error condition" 7 "Not Available/not valid" ;
VAL_ 2566803735 AccUseDem 0 "Not using ACC keeping" 1 "Using ACC distance keeping" 2 "Reserved" 3 "Don't Care" ;
VAL_ 2565406464 CtrlByte_Ackm 0 "ACK" 1 "NACK" 2 "Access Denied" 3 "Cannot Respond" ;
VAL_ 2565406464 Pgn_Ack 37120 "VLSI1" 40448 "DM29" 41216 "DM33" 41728 "DM31" 41984 "DM30" 47360 "PLLT(PlanListLifetime)" 47872 "PLD(PlanListDistance)" 49408 "DM21" 49664 "DM20" 49920 "DM22" 53504 "MaintBcIc" 54016 "DM19" 60928 "ACL" 61184 "STOD" 64342 "HVESP3CFG" 64344 "HVESP2CFG" 64346 "HVESP1CFG" 64529 "TGFI" 64579 "TCSI" 64582 "TSIS" 64583 "MTI" 64605 "HVESSCFG" 64606 "HVESSHIST" 64653 "PII" 64701 "A1SCRSI2" 64782 "AT1OGC2" 64784 "AT1IGC2" 64839 "TML" 64879 "EEC8" 64896 "DM28" 64905 "VDS2" 64906 "J2012" 64912 "AETC" 64920 "AT1HI1" 64949 "DM23" 64950 "DM24" 64951 "DM25" 64952 "DM26" 64953 "TPRI" 64965 "ECUID" 64981 "EEC5" 65039 "LC" 65099 "TCFG2" 65109 "GFD" 65127 "CCC" 65131 "DI" 65136 "CVW" 65144 "TP1" 65145 "TP2" 65146 "TP3" 65195 "ETC6" 65196 "EBC4" 65199 "GFC" 65201 "EH" 65202 "GFI1" 65203 "LFI1" 65208 "GTFI" 65212 "CBI" 65214 "EEC4" 65216 "SERV" 65219 "ETC5" 65221 "ETC4" 65223 "ETC3" 65227 "DM02" 65228 "DM03" 65229 "DM04" 65230 "DM05" 65231 "DM06" 65234 "DM10" 65235 "DM11" 65236 "DM12" 65242 "SOFT" 65244 "IO" 65248 "VD" 65250 "TCFG" 65253 "HOURS" 65254 "TD" 65255 "VH" 65256 "VDS" 65257 "LFC1" 65258 "VW" 65259 "CI" 65260 "VI" 65261 "CCSS" 65284 "PB_DriversConsentOnPersonalData" 65376 "VehCfg" 65413 "PB_3CT" 65482 "PB_ID1" 65484 "PB_VNS" 65502 "Av2" 65520 "SCh" 65521 "DIS" 65524 "PB_IVA" ;
VAL_ 2565406464 Pgn_Nack 37120 "VLSI1" 40448 "DM29" 41216 "DM33" 41728 "DM31" 41984 "DM30" 47360 "PLLT(PlanListLifetime)" 47872 "PLD(PlanListDistance)" 49408 "DM21" 49664 "DM20" 49920 "DM22" 53504 "MaintBcIc" 54016 "DM19" 60928 "ACL" 61184 "STOD" 64342 "HVESP3CFG" 64344 "HVESP2CFG" 64346 "HVESP1CFG" 64529 "TGFI" 64579 "TCSI" 64582 "TSIS" 64583 "MTI" 64605 "HVESSCFG" 64606 "HVESSHIST" 64653 "PII" 64701 "A1SCRSI2" 64782 "AT1OGC2" 64784 "AT1IGC2" 64839 "TML" 64879 "EEC8" 64896 "DM28" 64905 "VDS2" 64906 "J2012" 64912 "AETC" 64920 "AT1HI1" 64949 "DM23" 64950 "DM24" 64951 "DM25" 64952 "DM26" 64953 "TPRI" 64965 "ECUID" 64981 "EEC5" 65039 "LC" 65099 "TCFG2" 65109 "GFD" 65127 "CCC" 65131 "DI" 65136 "CVW" 65144 "TP1" 65145 "TP2" 65146 "TP3" 65195 "ETC6" 65196 "EBC4" 65199 "GFC" 65201 "EH" 65202 "GFI1" 65203 "LFI1" 65208 "GTFI" 65212 "CBI" 65214 "EEC4" 65216 "SERV" 65219 "ETC5" 65221 "ETC4" 65223 "ETC3" 65227 "DM02" 65228 "DM03" 65229 "DM04" 65230 "DM05" 65231 "DM06" 65234 "DM10" 65235 "DM11" 65236 "DM12" 65242 "SOFT" 65244 "IO" 65248 "VD" 65250 "TCFG" 65253 "HOURS" 65254 "TD" 65255 "VH" 65256 "VDS" 65257 "LFC1" 65258 "VW" 65259 "CI" 65260 "VI" 65261 "CCSS" 65284 "PB_DriversConsentOnPersonalData" 65376 "VehCfg" 65413 "PB_3CT" 65482 "PB_ID1" 65484 "PB_VNS" 65502 "Av2" 65520 "SCh" 65521 "DIS" 65524 "PB_IVA" ;
VAL_ 2565406464 Pgn_Ad 37120 "VLSI1" 40448 "DM29" 41216 "DM33" 41728 "DM31" 41984 "DM30" 47360 "PLLT(PlanListLifetime)" 47872 "PLD(PlanListDistance)" 49408 "DM21" 49664 "DM20" 49920 "DM22" 53504 "MaintBcIc" 54016 "DM19" 60928 "ACL" 61184 "STOD" 64342 "HVESP3CFG" 64344 "HVESP2CFG" 64346 "HVESP1CFG" 64529 "TGFI" 64579 "TCSI" 64582 "TSIS" 64583 "MTI" 64605 "HVESSCFG" 64606 "HVESSHIST" 64653 "PII" 64701 "A1SCRSI2" 64782 "AT1OGC2" 64784 "AT1IGC2" 64839 "TML" 64879 "EEC8" 64896 "DM28" 64905 "VDS2" 64906 "J2012" 64912 "AETC" 64920 "AT1HI1" 64949 "DM23" 64950 "DM24" 64951 "DM25" 64952 "DM26" 64953 "TPRI" 64965 "ECUID" 64981 "EEC5" 65039 "LC" 65099 "TCFG2" 65109 "GFD" 65127 "CCC" 65131 "DI" 65136 "CVW" 65144 "TP1" 65145 "TP2" 65146 "TP3" 65195 "ETC6" 65196 "EBC4" 65199 "GFC" 65201 "EH" 65202 "GFI1" 65203 "LFI1" 65208 "GTFI" 65212 "CBI" 65214 "EEC4" 65216 "SERV" 65219 "ETC5" 65221 "ETC4" 65223 "ETC3" 65227 "DM02" 65228 "DM03" 65229 "DM04" 65230 "DM05" 65231 "DM06" 65234 "DM10" 65235 "DM11" 65236 "DM12" 65242 "SOFT" 65244 "IO" 65248 "VD" 65250 "TCFG" 65253 "HOURS" 65254 "TD" 65255 "VH" 65256 "VDS" 65257 "LFC1" 65258 "VW" 65259 "CI" 65260 "VI" 65261 "CCSS" 65284 "PB_DriversConsentOnPersonalData" 65376 "VehCfg" 65413 "PB_3CT" 65482 "PB_ID1" 65484 "PB_VNS" 65502 "Av2" 65520 "SCh" 65521 "DIS" 65524 "PB_IVA" ;
VAL_ 2565406464 Pgn_Busy 37120 "VLSI1" 40448 "DM29" 41216 "DM33" 41728 "DM31" 41984 "DM30" 47360 "PLLT(PlanListLifetime)" 47872 "PLD(PlanListDistance)" 49408 "DM21" 49664 "DM20" 49920 "DM22" 53504 "MaintBcIc" 54016 "DM19" 60928 "ACL" 61184 "STOD" 64342 "HVESP3CFG" 64344 "HVESP2CFG" 64346 "HVESP1CFG" 64529 "TGFI" 64579 "TCSI" 64582 "TSIS" 64583 "MTI" 64605 "HVESSCFG" 64606 "HVESSHIST" 64653 "PII" 64701 "A1SCRSI2" 64782 "AT1OGC2" 64784 "AT1IGC2" 64839 "TML" 64879 "EEC8" 64896 "DM28" 64905 "VDS2" 64906 "J2012" 64912 "AETC" 64920 "AT1HI1" 64949 "DM23" 64950 "DM24" 64951 "DM25" 64952 "DM26" 64953 "TPRI" 64965 "ECUID" 64981 "EEC5" 65039 "LC" 65099 "TCFG2" 65109 "GFD" 65127 "CCC" 65131 "DI" 65136 "CVW" 65144 "TP1" 65145 "TP2" 65146 "TP3" 65195 "ETC6" 65196 "EBC4" 65199 "GFC" 65201 "EH" 65202 "GFI1" 65203 "LFI1" 65208 "GTFI" 65212 "CBI" 65214 "EEC4" 65216 "SERV" 65219 "ETC5" 65221 "ETC4" 65223 "ETC3" 65227 "DM02" 65228 "DM03" 65229 "DM04" 65230 "DM05" 65231 "DM06" 65234 "DM10" 65235 "DM11" 65236 "DM12" 65242 "SOFT" 65244 "IO" 65248 "VD" 65250 "TCFG" 65253 "HOURS" 65254 "TD" 65255 "VH" 65256 "VDS" 65257 "LFC1" 65258 "VW" 65259 "CI" 65260 "VI" 65261 "CCSS" 65284 "PB_DriversConsentOnPersonalData" 65376 "VehCfg" 65413 "PB_3CT" 65482 "PB_ID1" 65484 "PB_VNS" 65502 "Av2" 65520 "SCh" 65521 "DIS" 65524 "PB_IVA" ;
VAL_ 2565406467 CtrlByte_Ackm_18E8FF03 0 "ACK" 1 "NACK" 2 "Access Denied" 3 "Cannot Respond" ;
VAL_ 2565406467 Pgn_Ack_18E8FF03 37120 "VLSI1" 40448 "DM29" 41216 "DM33" 41728 "DM31" 41984 "DM30" 47360 "PLLT(PlanListLifetime)" 47872 "PLD(PlanListDistance)" 49408 "DM21" 49664 "DM20" 49920 "DM22" 53504 "MaintBcIc" 54016 "DM19" 60928 "ACL" 61184 "STOD" 64342 "HVESP3CFG" 64344 "HVESP2CFG" 64346 "HVESP1CFG" 64529 "TGFI" 64579 "TCSI" 64582 "TSIS" 64583 "MTI" 64605 "HVESSCFG" 64606 "HVESSHIST" 64653 "PII" 64701 "A1SCRSI2" 64782 "AT1OGC2" 64784 "AT1IGC2" 64839 "TML" 64879 "EEC8" 64896 "DM28" 64905 "VDS2" 64906 "J2012" 64912 "AETC" 64920 "AT1HI1" 64949 "DM23" 64950 "DM24" 64951 "DM25" 64952 "DM26" 64953 "TPRI" 64965 "ECUID" 64981 "EEC5" 65039 "LC" 65099 "TCFG2" 65109 "GFD" 65127 "CCC" 65131 "DI" 65136 "CVW" 65144 "TP1" 65145 "TP2" 65146 "TP3" 65195 "ETC6" 65196 "EBC4" 65199 "GFC" 65201 "EH" 65202 "GFI1" 65203 "LFI1" 65208 "GTFI" 65212 "CBI" 65214 "EEC4" 65216 "SERV" 65219 "ETC5" 65221 "ETC4" 65223 "ETC3" 65227 "DM02" 65228 "DM03" 65229 "DM04" 65230 "DM05" 65231 "DM06" 65234 "DM10" 65235 "DM11" 65236 "DM12" 65242 "SOFT" 65244 "IO" 65248 "VD" 65250 "TCFG" 65253 "HOURS" 65254 "TD" 65255 "VH" 65256 "VDS" 65257 "LFC1" 65258 "VW" 65259 "CI" 65260 "VI" 65261 "CCSS" 65284 "PB_DriversConsentOnPersonalData" 65376 "VehCfg" 65413 "PB_3CT" 65482 "PB_ID1" 65484 "PB_VNS" 65502 "Av2" 65520 "SCh" 65521 "DIS" 65524 "PB_IVA" ;
VAL_ 2565406467 Pgn_Nack_18E8FF03 37120 "VLSI1" 40448 "DM29" 41216 "DM33" 41728 "DM31" 41984 "DM30" 47360 "PLLT(PlanListLifetime)" 47872 "PLD(PlanListDistance)" 49408 "DM21" 49664 "DM20" 49920 "DM22" 53504 "MaintBcIc" 54016 "DM19" 60928 "ACL" 61184 "STOD" 64342 "HVESP3CFG" 64344 "HVESP2CFG" 64346 "HVESP1CFG" 64529 "TGFI" 64579 "TCSI" 64582 "TSIS" 64583 "MTI" 64605 "HVESSCFG" 64606 "HVESSHIST" 64653 "PII" 64701 "A1SCRSI2" 64782 "AT1OGC2" 64784 "AT1IGC2" 64839 "TML" 64879 "EEC8" 64896 "DM28" 64905 "VDS2" 64906 "J2012" 64912 "AETC" 64920 "AT1HI1" 64949 "DM23" 64950 "DM24" 64951 "DM25" 64952 "DM26" 64953 "TPRI" 64965 "ECUID" 64981 "EEC5" 65039 "LC" 65099 "TCFG2" 65109 "GFD" 65127 "CCC" 65131 "DI" 65136 "CVW" 65144 "TP1" 65145 "TP2" 65146 "TP3" 65195 "ETC6" 65196 "EBC4" 65199 "GFC" 65201 "EH" 65202 "GFI1" 65203 "LFI1" 65208 "GTFI" 65212 "CBI" 65214 "EEC4" 65216 "SERV" 65219 "ETC5" 65221 "ETC4" 65223 "ETC3" 65227 "DM02" 65228 "DM03" 65229 "DM04" 65230 "DM05" 65231 "DM06" 65234 "DM10" 65235 "DM11" 65236 "DM12" 65242 "SOFT" 65244 "IO" 65248 "VD" 65250 "TCFG" 65253 "HOURS" 65254 "TD" 65255 "VH" 65256 "VDS" 65257 "LFC1" 65258 "VW" 65259 "CI" 65260 "VI" 65261 "CCSS" 65284 "PB_DriversConsentOnPersonalData" 65376 "VehCfg" 65413 "PB_3CT" 65482 "PB_ID1" 65484 "PB_VNS" 65502 "Av2" 65520 "SCh" 65521 "DIS" 65524 "PB_IVA" ;
VAL_ 2565406467 Pgn_Ad_18E8FF03 37120 "VLSI1" 40448 "DM29" 41216 "DM33" 41728 "DM31" 41984 "DM30" 47360 "PLLT(PlanListLifetime)" 47872 "PLD(PlanListDistance)" 49408 "DM21" 49664 "DM20" 49920 "DM22" 53504 "MaintBcIc" 54016 "DM19" 60928 "ACL" 61184 "STOD" 64342 "HVESP3CFG" 64344 "HVESP2CFG" 64346 "HVESP1CFG" 64529 "TGFI" 64579 "TCSI" 64582 "TSIS" 64583 "MTI" 64605 "HVESSCFG" 64606 "HVESSHIST" 64653 "PII" 64701 "A1SCRSI2" 64782 "AT1OGC2" 64784 "AT1IGC2" 64839 "TML" 64879 "EEC8" 64896 "DM28" 64905 "VDS2" 64906 "J2012" 64912 "AETC" 64920 "AT1HI1" 64949 "DM23" 64950 "DM24" 64951 "DM25" 64952 "DM26" 64953 "TPRI" 64965 "ECUID" 64981 "EEC5" 65039 "LC" 65099 "TCFG2" 65109 "GFD" 65127 "CCC" 65131 "DI" 65136 "CVW" 65144 "TP1" 65145 "TP2" 65146 "TP3" 65195 "ETC6" 65196 "EBC4" 65199 "GFC" 65201 "EH" 65202 "GFI1" 65203 "LFI1" 65208 "GTFI" 65212 "CBI" 65214 "EEC4" 65216 "SERV" 65219 "ETC5" 65221 "ETC4" 65223 "ETC3" 65227 "DM02" 65228 "DM03" 65229 "DM04" 65230 "DM05" 65231 "DM06" 65234 "DM10" 65235 "DM11" 65236 "DM12" 65242 "SOFT" 65244 "IO" 65248 "VD" 65250 "TCFG" 65253 "HOURS" 65254 "TD" 65255 "VH" 65256 "VDS" 65257 "LFC1" 65258 "VW" 65259 "CI" 65260 "VI" 65261 "CCSS" 65284 "PB_DriversConsentOnPersonalData" 65376 "VehCfg" 65413 "PB_3CT" 65482 "PB_ID1" 65484 "PB_VNS" 65502 "Av2" 65520 "SCh" 65521 "DIS" 65524 "PB_IVA" ;
VAL_ 2565406467 Pgn_Busy_18E8FF03 37120 "VLSI1" 40448 "DM29" 41216 "DM33" 41728 "DM31" 41984 "DM30" 47360 "PLLT(PlanListLifetime)" 47872 "PLD(PlanListDistance)" 49408 "DM21" 49664 "DM20" 49920 "DM22" 53504 "MaintBcIc" 54016 "DM19" 60928 "ACL" 61184 "STOD" 64342 "HVESP3CFG" 64344 "HVESP2CFG" 64346 "HVESP1CFG" 64529 "TGFI" 64579 "TCSI" 64582 "TSIS" 64583 "MTI" 64605 "HVESSCFG" 64606 "HVESSHIST" 64653 "PII" 64701 "A1SCRSI2" 64782 "AT1OGC2" 64784 "AT1IGC2" 64839 "TML" 64879 "EEC8" 64896 "DM28" 64905 "VDS2" 64906 "J2012" 64912 "AETC" 64920 "AT1HI1" 64949 "DM23" 64950 "DM24" 64951 "DM25" 64952 "DM26" 64953 "TPRI" 64965 "ECUID" 64981 "EEC5" 65039 "LC" 65099 "TCFG2" 65109 "GFD" 65127 "CCC" 65131 "DI" 65136 "CVW" 65144 "TP1" 65145 "TP2" 65146 "TP3" 65195 "ETC6" 65196 "EBC4" 65199 "GFC" 65201 "EH" 65202 "GFI1" 65203 "LFI1" 65208 "GTFI" 65212 "CBI" 65214 "EEC4" 65216 "SERV" 65219 "ETC5" 65221 "ETC4" 65223 "ETC3" 65227 "DM02" 65228 "DM03" 65229 "DM04" 65230 "DM05" 65231 "DM06" 65234 "DM10" 65235 "DM11" 65236 "DM12" 65242 "SOFT" 65244 "IO" 65248 "VD" 65250 "TCFG" 65253 "HOURS" 65254 "TD" 65255 "VH" 65256 "VDS" 65257 "LFC1" 65258 "VW" 65259 "CI" 65260 "VI" 65261 "CCSS" 65284 "PB_DriversConsentOnPersonalData" 65376 "VehCfg" 65413 "PB_3CT" 65482 "PB_ID1" 65484 "PB_VNS" 65502 "Av2" 65520 "SCh" 65521 "DIS" 65524 "PB_IVA" ;
VAL_ 2565406475 CtrlByte_Ackm_18E8FF0B 0 "ACK" 1 "NACK" 2 "Access Denied" 3 "Cannot Respond" ;
VAL_ 2565406475 Pgn_Ack_18E8FF0B 37120 "VLSI1" 40448 "DM29" 41216 "DM33" 41728 "DM31" 41984 "DM30" 47360 "PLLT(PlanListLifetime)" 47872 "PLD(PlanListDistance)" 49408 "DM21" 49664 "DM20" 49920 "DM22" 53504 "MaintBcIc" 54016 "DM19" 60928 "ACL" 61184 "STOD" 64342 "HVESP3CFG" 64344 "HVESP2CFG" 64346 "HVESP1CFG" 64529 "TGFI" 64579 "TCSI" 64582 "TSIS" 64583 "MTI" 64605 "HVESSCFG" 64606 "HVESSHIST" 64653 "PII" 64701 "A1SCRSI2" 64782 "AT1OGC2" 64784 "AT1IGC2" 64839 "TML" 64879 "EEC8" 64896 "DM28" 64905 "VDS2" 64906 "J2012" 64912 "AETC" 64920 "AT1HI1" 64949 "DM23" 64950 "DM24" 64951 "DM25" 64952 "DM26" 64953 "TPRI" 64965 "ECUID" 64981 "EEC5" 65039 "LC" 65099 "TCFG2" 65109 "GFD" 65127 "CCC" 65131 "DI" 65136 "CVW" 65144 "TP1" 65145 "TP2" 65146 "TP3" 65195 "ETC6" 65196 "EBC4" 65199 "GFC" 65201 "EH" 65202 "GFI1" 65203 "LFI1" 65208 "GTFI" 65212 "CBI" 65214 "EEC4" 65216 "SERV" 65219 "ETC5" 65221 "ETC4" 65223 "ETC3" 65227 "DM02" 65228 "DM03" 65229 "DM04" 65230 "DM05" 65231 "DM06" 65234 "DM10" 65235 "DM11" 65236 "DM12" 65242 "SOFT" 65244 "IO" 65248 "VD" 65250 "TCFG" 65253 "HOURS" 65254 "TD" 65255 "VH" 65256 "VDS" 65257 "LFC1" 65258 "VW" 65259 "CI" 65260 "VI" 65261 "CCSS" 65284 "PB_DriversConsentOnPersonalData" 65376 "VehCfg" 65413 "PB_3CT" 65482 "PB_ID1" 65484 "PB_VNS" 65502 "Av2" 65520 "SCh" 65521 "DIS" 65524 "PB_IVA" ;
VAL_ 2565406475 Pgn_Nack_18E8FF0B 37120 "VLSI1" 40448 "DM29" 41216 "DM33" 41728 "DM31" 41984 "DM30" 47360 "PLLT(PlanListLifetime)" 47872 "PLD(PlanListDistance)" 49408 "DM21" 49664 "DM20" 49920 "DM22" 53504 "MaintBcIc" 54016 "DM19" 60928 "ACL" 61184 "STOD" 64342 "HVESP3CFG" 64344 "HVESP2CFG" 64346 "HVESP1CFG" 64529 "TGFI" 64579 "TCSI" 64582 "TSIS" 64583 "MTI" 64605 "HVESSCFG" 64606 "HVESSHIST" 64653 "PII" 64701 "A1SCRSI2" 64782 "AT1OGC2" 64784 "AT1IGC2" 64839 "TML" 64879 "EEC8" 64896 "DM28" 64905 "VDS2" 64906 "J2012" 64912 "AETC" 64920 "AT1HI1" 64949 "DM23" 64950 "DM24" 64951 "DM25" 64952 "DM26" 64953 "TPRI" 64965 "ECUID" 64981 "EEC5" 65039 "LC" 65099 "TCFG2" 65109 "GFD" 65127 "CCC" 65131 "DI" 65136 "CVW" 65144 "TP1" 65145 "TP2" 65146 "TP3" 65195 "ETC6" 65196 "EBC4" 65199 "GFC" 65201 "EH" 65202 "GFI1" 65203 "LFI1" 65208 "GTFI" 65212 "CBI" 65214 "EEC4" 65216 "SERV" 65219 "ETC5" 65221 "ETC4" 65223 "ETC3" 65227 "DM02" 65228 "DM03" 65229 "DM04" 65230 "DM05" 65231 "DM06" 65234 "DM10" 65235 "DM11" 65236 "DM12" 65242 "SOFT" 65244 "IO" 65248 "VD" 65250 "TCFG" 65253 "HOURS" 65254 "TD" 65255 "VH" 65256 "VDS" 65257 "LFC1" 65258 "VW" 65259 "CI" 65260 "VI" 65261 "CCSS" 65284 "PB_DriversConsentOnPersonalData" 65376 "VehCfg" 65413 "PB_3CT" 65482 "PB_ID1" 65484 "PB_VNS" 65502 "Av2" 65520 "SCh" 65521 "DIS" 65524 "PB_IVA" ;
VAL_ 2565406475 Pgn_Ad_18E8FF0B 37120 "VLSI1" 40448 "DM29" 41216 "DM33" 41728 "DM31" 41984 "DM30" 47360 "PLLT(PlanListLifetime)" 47872 "PLD(PlanListDistance)" 49408 "DM21" 49664 "DM20" 49920 "DM22" 53504 "MaintBcIc" 54016 "DM19" 60928 "ACL" 61184 "STOD" 64342 "HVESP3CFG" 64344 "HVESP2CFG" 64346 "HVESP1CFG" 64529 "TGFI" 64579 "TCSI" 64582 "TSIS" 64583 "MTI" 64605 "HVESSCFG" 64606 "HVESSHIST" 64653 "PII" 64701 "A1SCRSI2" 64782 "AT1OGC2" 64784 "AT1IGC2" 64839 "TML" 64879 "EEC8" 64896 "DM28" 64905 "VDS2" 64906 "J2012" 64912 "AETC" 64920 "AT1HI1" 64949 "DM23" 64950 "DM24" 64951 "DM25" 64952 "DM26" 64953 "TPRI" 64965 "ECUID" 64981 "EEC5" 65039 "LC" 65099 "TCFG2" 65109 "GFD" 65127 "CCC" 65131 "DI" 65136 "CVW" 65144 "TP1" 65145 "TP2" 65146 "TP3" 65195 "ETC6" 65196 "EBC4" 65199 "GFC" 65201 "EH" 65202 "GFI1" 65203 "LFI1" 65208 "GTFI" 65212 "CBI" 65214 "EEC4" 65216 "SERV" 65219 "ETC5" 65221 "ETC4" 65223 "ETC3" 65227 "DM02" 65228 "DM03" 65229 "DM04" 65230 "DM05" 65231 "DM06" 65234 "DM10" 65235 "DM11" 65236 "DM12" 65242 "SOFT" 65244 "IO" 65248 "VD" 65250 "TCFG" 65253 "HOURS" 65254 "TD" 65255 "VH" 65256 "VDS" 65257 "LFC1" 65258 "VW" 65259 "CI" 65260 "VI" 65261 "CCSS" 65284 "PB_DriversConsentOnPersonalData" 65376 "VehCfg" 65413 "PB_3CT" 65482 "PB_ID1" 65484 "PB_VNS" 65502 "Av2" 65520 "SCh" 65521 "DIS" 65524 "PB_IVA" ;
VAL_ 2565406475 Pgn_Busy_18E8FF0B 37120 "VLSI1" 40448 "DM29" 41216 "DM33" 41728 "DM31" 41984 "DM30" 47360 "PLLT(PlanListLifetime)" 47872 "PLD(PlanListDistance)" 49408 "DM21" 49664 "DM20" 49920 "DM22" 53504 "MaintBcIc" 54016 "DM19" 60928 "ACL" 61184 "STOD" 64342 "HVESP3CFG" 64344 "HVESP2CFG" 64346 "HVESP1CFG" 64529 "TGFI" 64579 "TCSI" 64582 "TSIS" 64583 "MTI" 64605 "HVESSCFG" 64606 "HVESSHIST" 64653 "PII" 64701 "A1SCRSI2" 64782 "AT1OGC2" 64784 "AT1IGC2" 64839 "TML" 64879 "EEC8" 64896 "DM28" 64905 "VDS2" 64906 "J2012" 64912 "AETC" 64920 "AT1HI1" 64949 "DM23" 64950 "DM24" 64951 "DM25" 64952 "DM26" 64953 "TPRI" 64965 "ECUID" 64981 "EEC5" 65039 "LC" 65099 "TCFG2" 65109 "GFD" 65127 "CCC" 65131 "DI" 65136 "CVW" 65144 "TP1" 65145 "TP2" 65146 "TP3" 65195 "ETC6" 65196 "EBC4" 65199 "GFC" 65201 "EH" 65202 "GFI1" 65203 "LFI1" 65208 "GTFI" 65212 "CBI" 65214 "EEC4" 65216 "SERV" 65219 "ETC5" 65221 "ETC4" 65223 "ETC3" 65227 "DM02" 65228 "DM03" 65229 "DM04" 65230 "DM05" 65231 "DM06" 65234 "DM10" 65235 "DM11" 65236 "DM12" 65242 "SOFT" 65244 "IO" 65248 "VD" 65250 "TCFG" 65253 "HOURS" 65254 "TD" 65255 "VH" 65256 "VDS" 65257 "LFC1" 65258 "VW" 65259 "CI" 65260 "VI" 65261 "CCSS" 65284 "PB_DriversConsentOnPersonalData" 65376 "VehCfg" 65413 "PB_3CT" 65482 "PB_ID1" 65484 "PB_VNS" 65502 "Av2" 65520 "SCh" 65521 "DIS" 65524 "PB_IVA" ;
VAL_ 2565406487 CtrlByte_Ackm_18E8FF17 0 "ACK" 1 "NACK" 2 "Access Denied" 3 "Cannot Respond" ;
VAL_ 2565406487 Pgn_Ack_18E8FF17 37120 "VLSI1" 40448 "DM29" 41216 "DM33" 41728 "DM31" 41984 "DM30" 47360 "PLLT(PlanListLifetime)" 47872 "PLD(PlanListDistance)" 49408 "DM21" 49664 "DM20" 49920 "DM22" 53504 "MaintBcIc" 54016 "DM19" 60928 "ACL" 61184 "STOD" 64342 "HVESP3CFG" 64344 "HVESP2CFG" 64346 "HVESP1CFG" 64529 "TGFI" 64579 "TCSI" 64582 "TSIS" 64583 "MTI" 64605 "HVESSCFG" 64606 "HVESSHIST" 64653 "PII" 64701 "A1SCRSI2" 64782 "AT1OGC2" 64784 "AT1IGC2" 64839 "TML" 64879 "EEC8" 64896 "DM28" 64905 "VDS2" 64906 "J2012" 64912 "AETC" 64920 "AT1HI1" 64949 "DM23" 64950 "DM24" 64951 "DM25" 64952 "DM26" 64953 "TPRI" 64965 "ECUID" 64981 "EEC5" 65039 "LC" 65099 "TCFG2" 65109 "GFD" 65127 "CCC" 65131 "DI" 65136 "CVW" 65144 "TP1" 65145 "TP2" 65146 "TP3" 65195 "ETC6" 65196 "EBC4" 65199 "GFC" 65201 "EH" 65202 "GFI1" 65203 "LFI1" 65208 "GTFI" 65212 "CBI" 65214 "EEC4" 65216 "SERV" 65219 "ETC5" 65221 "ETC4" 65223 "ETC3" 65227 "DM02" 65228 "DM03" 65229 "DM04" 65230 "DM05" 65231 "DM06" 65234 "DM10" 65235 "DM11" 65236 "DM12" 65242 "SOFT" 65244 "IO" 65248 "VD" 65250 "TCFG" 65253 "HOURS" 65254 "TD" 65255 "VH" 65256 "VDS" 65257 "LFC1" 65258 "VW" 65259 "CI" 65260 "VI" 65261 "CCSS" 65284 "PB_DriversConsentOnPersonalData" 65376 "VehCfg" 65413 "PB_3CT" 65482 "PB_ID1" 65484 "PB_VNS" 65502 "Av2" 65520 "SCh" 65521 "DIS" 65524 "PB_IVA" ;
VAL_ 2565406487 Pgn_Nack_18E8FF17 37120 "VLSI1" 40448 "DM29" 41216 "DM33" 41728 "DM31" 41984 "DM30" 47360 "PLLT(PlanListLifetime)" 47872 "PLD(PlanListDistance)" 49408 "DM21" 49664 "DM20" 49920 "DM22" 53504 "MaintBcIc" 54016 "DM19" 60928 "ACL" 61184 "STOD" 64342 "HVESP3CFG" 64344 "HVESP2CFG" 64346 "HVESP1CFG" 64529 "TGFI" 64579 "TCSI" 64582 "TSIS" 64583 "MTI" 64605 "HVESSCFG" 64606 "HVESSHIST" 64653 "PII" 64701 "A1SCRSI2" 64782 "AT1OGC2" 64784 "AT1IGC2" 64839 "TML" 64879 "EEC8" 64896 "DM28" 64905 "VDS2" 64906 "J2012" 64912 "AETC" 64920 "AT1HI1" 64949 "DM23" 64950 "DM24" 64951 "DM25" 64952 "DM26" 64953 "TPRI" 64965 "ECUID" 64981 "EEC5" 65039 "LC" 65099 "TCFG2" 65109 "GFD" 65127 "CCC" 65131 "DI" 65136 "CVW" 65144 "TP1" 65145 "TP2" 65146 "TP3" 65195 "ETC6" 65196 "EBC4" 65199 "GFC" 65201 "EH" 65202 "GFI1" 65203 "LFI1" 65208 "GTFI" 65212 "CBI" 65214 "EEC4" 65216 "SERV" 65219 "ETC5" 65221 "ETC4" 65223 "ETC3" 65227 "DM02" 65228 "DM03" 65229 "DM04" 65230 "DM05" 65231 "DM06" 65234 "DM10" 65235 "DM11" 65236 "DM12" 65242 "SOFT" 65244 "IO" 65248 "VD" 65250 "TCFG" 65253 "HOURS" 65254 "TD" 65255 "VH" 65256 "VDS" 65257 "LFC1" 65258 "VW" 65259 "CI" 65260 "VI" 65261 "CCSS" 65284 "PB_DriversConsentOnPersonalData" 65376 "VehCfg" 65413 "PB_3CT" 65482 "PB_ID1" 65484 "PB_VNS" 65502 "Av2" 65520 "SCh" 65521 "DIS" 65524 "PB_IVA" ;
VAL_ 2565406487 Pgn_Ad_18E8FF17 37120 "VLSI1" 40448 "DM29" 41216 "DM33" 41728 "DM31" 41984 "DM30" 47360 "PLLT(PlanListLifetime)" 47872 "PLD(PlanListDistance)" 49408 "DM21" 49664 "DM20" 49920 "DM22" 53504 "MaintBcIc" 54016 "DM19" 60928 "ACL" 61184 "STOD" 64342 "HVESP3CFG" 64344 "HVESP2CFG" 64346 "HVESP1CFG" 64529 "TGFI" 64579 "TCSI" 64582 "TSIS" 64583 "MTI" 64605 "HVESSCFG" 64606 "HVESSHIST" 64653 "PII" 64701 "A1SCRSI2" 64782 "AT1OGC2" 64784 "AT1IGC2" 64839 "TML" 64879 "EEC8" 64896 "DM28" 64905 "VDS2" 64906 "J2012" 64912 "AETC" 64920 "AT1HI1" 64949 "DM23" 64950 "DM24" 64951 "DM25" 64952 "DM26" 64953 "TPRI" 64965 "ECUID" 64981 "EEC5" 65039 "LC" 65099 "TCFG2" 65109 "GFD" 65127 "CCC" 65131 "DI" 65136 "CVW" 65144 "TP1" 65145 "TP2" 65146 "TP3" 65195 "ETC6" 65196 "EBC4" 65199 "GFC" 65201 "EH" 65202 "GFI1" 65203 "LFI1" 65208 "GTFI" 65212 "CBI" 65214 "EEC4" 65216 "SERV" 65219 "ETC5" 65221 "ETC4" 65223 "ETC3" 65227 "DM02" 65228 "DM03" 65229 "DM04" 65230 "DM05" 65231 "DM06" 65234 "DM10" 65235 "DM11" 65236 "DM12" 65242 "SOFT" 65244 "IO" 65248 "VD" 65250 "TCFG" 65253 "HOURS" 65254 "TD" 65255 "VH" 65256 "VDS" 65257 "LFC1" 65258 "VW" 65259 "CI" 65260 "VI" 65261 "CCSS" 65284 "PB_DriversConsentOnPersonalData" 65376 "VehCfg" 65413 "PB_3CT" 65482 "PB_ID1" 65484 "PB_VNS" 65502 "Av2" 65520 "SCh" 65521 "DIS" 65524 "PB_IVA" ;
VAL_ 2565406487 Pgn_Busy_18E8FF17 37120 "VLSI1" 40448 "DM29" 41216 "DM33" 41728 "DM31" 41984 "DM30" 47360 "PLLT(PlanListLifetime)" 47872 "PLD(PlanListDistance)" 49408 "DM21" 49664 "DM20" 49920 "DM22" 53504 "MaintBcIc" 54016 "DM19" 60928 "ACL" 61184 "STOD" 64342 "HVESP3CFG" 64344 "HVESP2CFG" 64346 "HVESP1CFG" 64529 "TGFI" 64579 "TCSI" 64582 "TSIS" 64583 "MTI" 64605 "HVESSCFG" 64606 "HVESSHIST" 64653 "PII" 64701 "A1SCRSI2" 64782 "AT1OGC2" 64784 "AT1IGC2" 64839 "TML" 64879 "EEC8" 64896 "DM28" 64905 "VDS2" 64906 "J2012" 64912 "AETC" 64920 "AT1HI1" 64949 "DM23" 64950 "DM24" 64951 "DM25" 64952 "DM26" 64953 "TPRI" 64965 "ECUID" 64981 "EEC5" 65039 "LC" 65099 "TCFG2" 65109 "GFD" 65127 "CCC" 65131 "DI" 65136 "CVW" 65144 "TP1" 65145 "TP2" 65146 "TP3" 65195 "ETC6" 65196 "EBC4" 65199 "GFC" 65201 "EH" 65202 "GFI1" 65203 "LFI1" 65208 "GTFI" 65212 "CBI" 65214 "EEC4" 65216 "SERV" 65219 "ETC5" 65221 "ETC4" 65223 "ETC3" 65227 "DM02" 65228 "DM03" 65229 "DM04" 65230 "DM05" 65231 "DM06" 65234 "DM10" 65235 "DM11" 65236 "DM12" 65242 "SOFT" 65244 "IO" 65248 "VD" 65250 "TCFG" 65253 "HOURS" 65254 "TD" 65255 "VH" 65256 "VDS" 65257 "LFC1" 65258 "VW" 65259 "CI" 65260 "VI" 65261 "CCSS" 65284 "PB_DriversConsentOnPersonalData" 65376 "VehCfg" 65413 "PB_3CT" 65482 "PB_ID1" 65484 "PB_VNS" 65502 "Av2" 65520 "SCh" 65521 "DIS" 65524 "PB_IVA" ;
VAL_ 2565406492 CtrlByte_Ackm_18E8FF1C 0 "ACK" 1 "NACK" 2 "Access Denied" 3 "Cannot Respond" ;
VAL_ 2565406492 Pgn_Ack_18E8FF1C 37120 "VLSI1" 40448 "DM29" 41216 "DM33" 41728 "DM31" 41984 "DM30" 47360 "PLLT(PlanListLifetime)" 47872 "PLD(PlanListDistance)" 49408 "DM21" 49664 "DM20" 49920 "DM22" 53504 "MaintBcIc" 54016 "DM19" 60928 "ACL" 61184 "STOD" 64342 "HVESP3CFG" 64344 "HVESP2CFG" 64346 "HVESP1CFG" 64529 "TGFI" 64579 "TCSI" 64582 "TSIS" 64583 "MTI" 64605 "HVESSCFG" 64606 "HVESSHIST" 64653 "PII" 64701 "A1SCRSI2" 64782 "AT1OGC2" 64784 "AT1IGC2" 64839 "TML" 64879 "EEC8" 64896 "DM28" 64905 "VDS2" 64906 "J2012" 64912 "AETC" 64920 "AT1HI1" 64949 "DM23" 64950 "DM24" 64951 "DM25" 64952 "DM26" 64953 "TPRI" 64965 "ECUID" 64981 "EEC5" 65039 "LC" 65099 "TCFG2" 65109 "GFD" 65127 "CCC" 65131 "DI" 65136 "CVW" 65144 "TP1" 65145 "TP2" 65146 "TP3" 65195 "ETC6" 65196 "EBC4" 65199 "GFC" 65201 "EH" 65202 "GFI1" 65203 "LFI1" 65208 "GTFI" 65212 "CBI" 65214 "EEC4" 65216 "SERV" 65219 "ETC5" 65221 "ETC4" 65223 "ETC3" 65227 "DM02" 65228 "DM03" 65229 "DM04" 65230 "DM05" 65231 "DM06" 65234 "DM10" 65235 "DM11" 65236 "DM12" 65242 "SOFT" 65244 "IO" 65248 "VD" 65250 "TCFG" 65253 "HOURS" 65254 "TD" 65255 "VH" 65256 "VDS" 65257 "LFC1" 65258 "VW" 65259 "CI" 65260 "VI" 65261 "CCSS" 65284 "PB_DriversConsentOnPersonalData" 65376 "VehCfg" 65413 "PB_3CT" 65482 "PB_ID1" 65484 "PB_VNS" 65502 "Av2" 65520 "SCh" 65521 "DIS" 65524 "PB_IVA" ;
VAL_ 2565406492 Pgn_Nack_18E8FF1C 37120 "VLSI1" 40448 "DM29" 41216 "DM33" 41728 "DM31" 41984 "DM30" 47360 "PLLT(PlanListLifetime)" 47872 "PLD(PlanListDistance)" 49408 "DM21" 49664 "DM20" 49920 "DM22" 53504 "MaintBcIc" 54016 "DM19" 60928 "ACL" 61184 "STOD" 64342 "HVESP3CFG" 64344 "HVESP2CFG" 64346 "HVESP1CFG" 64529 "TGFI" 64579 "TCSI" 64582 "TSIS" 64583 "MTI" 64605 "HVESSCFG" 64606 "HVESSHIST" 64653 "PII" 64701 "A1SCRSI2" 64782 "AT1OGC2" 64784 "AT1IGC2" 64839 "TML" 64879 "EEC8" 64896 "DM28" 64905 "VDS2" 64906 "J2012" 64912 "AETC" 64920 "AT1HI1" 64949 "DM23" 64950 "DM24" 64951 "DM25" 64952 "DM26" 64953 "TPRI" 64965 "ECUID" 64981 "EEC5" 65039 "LC" 65099 "TCFG2" 65109 "GFD" 65127 "CCC" 65131 "DI" 65136 "CVW" 65144 "TP1" 65145 "TP2" 65146 "TP3" 65195 "ETC6" 65196 "EBC4" 65199 "GFC" 65201 "EH" 65202 "GFI1" 65203 "LFI1" 65208 "GTFI" 65212 "CBI" 65214 "EEC4" 65216 "SERV" 65219 "ETC5" 65221 "ETC4" 65223 "ETC3" 65227 "DM02" 65228 "DM03" 65229 "DM04" 65230 "DM05" 65231 "DM06" 65234 "DM10" 65235 "DM11" 65236 "DM12" 65242 "SOFT" 65244 "IO" 65248 "VD" 65250 "TCFG" 65253 "HOURS" 65254 "TD" 65255 "VH" 65256 "VDS" 65257 "LFC1" 65258 "VW" 65259 "CI" 65260 "VI" 65261 "CCSS" 65284 "PB_DriversConsentOnPersonalData" 65376 "VehCfg" 65413 "PB_3CT" 65482 "PB_ID1" 65484 "PB_VNS" 65502 "Av2" 65520 "SCh" 65521 "DIS" 65524 "PB_IVA" ;
VAL_ 2565406492 Pgn_Ad_18E8FF1C 37120 "VLSI1" 40448 "DM29" 41216 "DM33" 41728 "DM31" 41984 "DM30" 47360 "PLLT(PlanListLifetime)" 47872 "PLD(PlanListDistance)" 49408 "DM21" 49664 "DM20" 49920 "DM22" 53504 "MaintBcIc" 54016 "DM19" 60928 "ACL" 61184 "STOD" 64342 "HVESP3CFG" 64344 "HVESP2CFG" 64346 "HVESP1CFG" 64529 "TGFI" 64579 "TCSI" 64582 "TSIS" 64583 "MTI" 64605 "HVESSCFG" 64606 "HVESSHIST" 64653 "PII" 64701 "A1SCRSI2" 64782 "AT1OGC2" 64784 "AT1IGC2" 64839 "TML" 64879 "EEC8" 64896 "DM28" 64905 "VDS2" 64906 "J2012" 64912 "AETC" 64920 "AT1HI1" 64949 "DM23" 64950 "DM24" 64951 "DM25" 64952 "DM26" 64953 "TPRI" 64965 "ECUID" 64981 "EEC5" 65039 "LC" 65099 "TCFG2" 65109 "GFD" 65127 "CCC" 65131 "DI" 65136 "CVW" 65144 "TP1" 65145 "TP2" 65146 "TP3" 65195 "ETC6" 65196 "EBC4" 65199 "GFC" 65201 "EH" 65202 "GFI1" 65203 "LFI1" 65208 "GTFI" 65212 "CBI" 65214 "EEC4" 65216 "SERV" 65219 "ETC5" 65221 "ETC4" 65223 "ETC3" 65227 "DM02" 65228 "DM03" 65229 "DM04" 65230 "DM05" 65231 "DM06" 65234 "DM10" 65235 "DM11" 65236 "DM12" 65242 "SOFT" 65244 "IO" 65248 "VD" 65250 "TCFG" 65253 "HOURS" 65254 "TD" 65255 "VH" 65256 "VDS" 65257 "LFC1" 65258 "VW" 65259 "CI" 65260 "VI" 65261 "CCSS" 65284 "PB_DriversConsentOnPersonalData" 65376 "VehCfg" 65413 "PB_3CT" 65482 "PB_ID1" 65484 "PB_VNS" 65502 "Av2" 65520 "SCh" 65521 "DIS" 65524 "PB_IVA" ;
VAL_ 2565406492 Pgn_Busy_18E8FF1C 37120 "VLSI1" 40448 "DM29" 41216 "DM33" 41728 "DM31" 41984 "DM30" 47360 "PLLT(PlanListLifetime)" 47872 "PLD(PlanListDistance)" 49408 "DM21" 49664 "DM20" 49920 "DM22" 53504 "MaintBcIc" 54016 "DM19" 60928 "ACL" 61184 "STOD" 64342 "HVESP3CFG" 64344 "HVESP2CFG" 64346 "HVESP1CFG" 64529 "TGFI" 64579 "TCSI" 64582 "TSIS" 64583 "MTI" 64605 "HVESSCFG" 64606 "HVESSHIST" 64653 "PII" 64701 "A1SCRSI2" 64782 "AT1OGC2" 64784 "AT1IGC2" 64839 "TML" 64879 "EEC8" 64896 "DM28" 64905 "VDS2" 64906 "J2012" 64912 "AETC" 64920 "AT1HI1" 64949 "DM23" 64950 "DM24" 64951 "DM25" 64952 "DM26" 64953 "TPRI" 64965 "ECUID" 64981 "EEC5" 65039 "LC" 65099 "TCFG2" 65109 "GFD" 65127 "CCC" 65131 "DI" 65136 "CVW" 65144 "TP1" 65145 "TP2" 65146 "TP3" 65195 "ETC6" 65196 "EBC4" 65199 "GFC" 65201 "EH" 65202 "GFI1" 65203 "LFI1" 65208 "GTFI" 65212 "CBI" 65214 "EEC4" 65216 "SERV" 65219 "ETC5" 65221 "ETC4" 65223 "ETC3" 65227 "DM02" 65228 "DM03" 65229 "DM04" 65230 "DM05" 65231 "DM06" 65234 "DM10" 65235 "DM11" 65236 "DM12" 65242 "SOFT" 65244 "IO" 65248 "VD" 65250 "TCFG" 65253 "HOURS" 65254 "TD" 65255 "VH" 65256 "VDS" 65257 "LFC1" 65258 "VW" 65259 "CI" 65260 "VI" 65261 "CCSS" 65284 "PB_DriversConsentOnPersonalData" 65376 "VehCfg" 65413 "PB_3CT" 65482 "PB_ID1" 65484 "PB_VNS" 65502 "Av2" 65520 "SCh" 65521 "DIS" 65524 "PB_IVA" ;
VAL_ 2565406493 CtrlByte_Ackm_18E8FF1D 0 "ACK" 1 "NACK" 2 "Access Denied" 3 "Cannot Respond" ;
VAL_ 2565406493 Pgn_Ack_18E8FF1D 37120 "VLSI1" 40448 "DM29" 41216 "DM33" 41728 "DM31" 41984 "DM30" 47360 "PLLT(PlanListLifetime)" 47872 "PLD(PlanListDistance)" 49408 "DM21" 49664 "DM20" 49920 "DM22" 53504 "MaintBcIc" 54016 "DM19" 60928 "ACL" 61184 "STOD" 64342 "HVESP3CFG" 64344 "HVESP2CFG" 64346 "HVESP1CFG" 64529 "TGFI" 64579 "TCSI" 64582 "TSIS" 64583 "MTI" 64605 "HVESSCFG" 64606 "HVESSHIST" 64653 "PII" 64701 "A1SCRSI2" 64782 "AT1OGC2" 64784 "AT1IGC2" 64839 "TML" 64879 "EEC8" 64896 "DM28" 64905 "VDS2" 64906 "J2012" 64912 "AETC" 64920 "AT1HI1" 64949 "DM23" 64950 "DM24" 64951 "DM25" 64952 "DM26" 64953 "TPRI" 64965 "ECUID" 64981 "EEC5" 65039 "LC" 65099 "TCFG2" 65109 "GFD" 65127 "CCC" 65131 "DI" 65136 "CVW" 65144 "TP1" 65145 "TP2" 65146 "TP3" 65195 "ETC6" 65196 "EBC4" 65199 "GFC" 65201 "EH" 65202 "GFI1" 65203 "LFI1" 65208 "GTFI" 65212 "CBI" 65214 "EEC4" 65216 "SERV" 65219 "ETC5" 65221 "ETC4" 65223 "ETC3" 65227 "DM02" 65228 "DM03" 65229 "DM04" 65230 "DM05" 65231 "DM06" 65234 "DM10" 65235 "DM11" 65236 "DM12" 65242 "SOFT" 65244 "IO" 65248 "VD" 65250 "TCFG" 65253 "HOURS" 65254 "TD" 65255 "VH" 65256 "VDS" 65257 "LFC1" 65258 "VW" 65259 "CI" 65260 "VI" 65261 "CCSS" 65284 "PB_DriversConsentOnPersonalData" 65376 "VehCfg" 65413 "PB_3CT" 65482 "PB_ID1" 65484 "PB_VNS" 65502 "Av2" 65520 "SCh" 65521 "DIS" 65524 "PB_IVA" ;
VAL_ 2565406493 Pgn_Nack_18E8FF1D 37120 "VLSI1" 40448 "DM29" 41216 "DM33" 41728 "DM31" 41984 "DM30" 47360 "PLLT(PlanListLifetime)" 47872 "PLD(PlanListDistance)" 49408 "DM21" 49664 "DM20" 49920 "DM22" 53504 "MaintBcIc" 54016 "DM19" 60928 "ACL" 61184 "STOD" 64342 "HVESP3CFG" 64344 "HVESP2CFG" 64346 "HVESP1CFG" 64529 "TGFI" 64579 "TCSI" 64582 "TSIS" 64583 "MTI" 64605 "HVESSCFG" 64606 "HVESSHIST" 64653 "PII" 64701 "A1SCRSI2" 64782 "AT1OGC2" 64784 "AT1IGC2" 64839 "TML" 64879 "EEC8" 64896 "DM28" 64905 "VDS2" 64906 "J2012" 64912 "AETC" 64920 "AT1HI1" 64949 "DM23" 64950 "DM24" 64951 "DM25" 64952 "DM26" 64953 "TPRI" 64965 "ECUID" 64981 "EEC5" 65039 "LC" 65099 "TCFG2" 65109 "GFD" 65127 "CCC" 65131 "DI" 65136 "CVW" 65144 "TP1" 65145 "TP2" 65146 "TP3" 65195 "ETC6" 65196 "EBC4" 65199 "GFC" 65201 "EH" 65202 "GFI1" 65203 "LFI1" 65208 "GTFI" 65212 "CBI" 65214 "EEC4" 65216 "SERV" 65219 "ETC5" 65221 "ETC4" 65223 "ETC3" 65227 "DM02" 65228 "DM03" 65229 "DM04" 65230 "DM05" 65231 "DM06" 65234 "DM10" 65235 "DM11" 65236 "DM12" 65242 "SOFT" 65244 "IO" 65248 "VD" 65250 "TCFG" 65253 "HOURS" 65254 "TD" 65255 "VH" 65256 "VDS" 65257 "LFC1" 65258 "VW" 65259 "CI" 65260 "VI" 65261 "CCSS" 65284 "PB_DriversConsentOnPersonalData" 65376 "VehCfg" 65413 "PB_3CT" 65482 "PB_ID1" 65484 "PB_VNS" 65502 "Av2" 65520 "SCh" 65521 "DIS" 65524 "PB_IVA" ;
VAL_ 2565406493 Pgn_Ad_18E8FF1D 37120 "VLSI1" 40448 "DM29" 41216 "DM33" 41728 "DM31" 41984 "DM30" 47360 "PLLT(PlanListLifetime)" 47872 "PLD(PlanListDistance)" 49408 "DM21" 49664 "DM20" 49920 "DM22" 53504 "MaintBcIc" 54016 "DM19" 60928 "ACL" 61184 "STOD" 64342 "HVESP3CFG" 64344 "HVESP2CFG" 64346 "HVESP1CFG" 64529 "TGFI" 64579 "TCSI" 64582 "TSIS" 64583 "MTI" 64605 "HVESSCFG" 64606 "HVESSHIST" 64653 "PII" 64701 "A1SCRSI2" 64782 "AT1OGC2" 64784 "AT1IGC2" 64839 "TML" 64879 "EEC8" 64896 "DM28" 64905 "VDS2" 64906 "J2012" 64912 "AETC" 64920 "AT1HI1" 64949 "DM23" 64950 "DM24" 64951 "DM25" 64952 "DM26" 64953 "TPRI" 64965 "ECUID" 64981 "EEC5" 65039 "LC" 65099 "TCFG2" 65109 "GFD" 65127 "CCC" 65131 "DI" 65136 "CVW" 65144 "TP1" 65145 "TP2" 65146 "TP3" 65195 "ETC6" 65196 "EBC4" 65199 "GFC" 65201 "EH" 65202 "GFI1" 65203 "LFI1" 65208 "GTFI" 65212 "CBI" 65214 "EEC4" 65216 "SERV" 65219 "ETC5" 65221 "ETC4" 65223 "ETC3" 65227 "DM02" 65228 "DM03" 65229 "DM04" 65230 "DM05" 65231 "DM06" 65234 "DM10" 65235 "DM11" 65236 "DM12" 65242 "SOFT" 65244 "IO" 65248 "VD" 65250 "TCFG" 65253 "HOURS" 65254 "TD" 65255 "VH" 65256 "VDS" 65257 "LFC1" 65258 "VW" 65259 "CI" 65260 "VI" 65261 "CCSS" 65284 "PB_DriversConsentOnPersonalData" 65376 "VehCfg" 65413 "PB_3CT" 65482 "PB_ID1" 65484 "PB_VNS" 65502 "Av2" 65520 "SCh" 65521 "DIS" 65524 "PB_IVA" ;
VAL_ 2565406493 Pgn_Busy_18E8FF1D 37120 "VLSI1" 40448 "DM29" 41216 "DM33" 41728 "DM31" 41984 "DM30" 47360 "PLLT(PlanListLifetime)" 47872 "PLD(PlanListDistance)" 49408 "DM21" 49664 "DM20" 49920 "DM22" 53504 "MaintBcIc" 54016 "DM19" 60928 "ACL" 61184 "STOD" 64342 "HVESP3CFG" 64344 "HVESP2CFG" 64346 "HVESP1CFG" 64529 "TGFI" 64579 "TCSI" 64582 "TSIS" 64583 "MTI" 64605 "HVESSCFG" 64606 "HVESSHIST" 64653 "PII" 64701 "A1SCRSI2" 64782 "AT1OGC2" 64784 "AT1IGC2" 64839 "TML" 64879 "EEC8" 64896 "DM28" 64905 "VDS2" 64906 "J2012" 64912 "AETC" 64920 "AT1HI1" 64949 "DM23" 64950 "DM24" 64951 "DM25" 64952 "DM26" 64953 "TPRI" 64965 "ECUID" 64981 "EEC5" 65039 "LC" 65099 "TCFG2" 65109 "GFD" 65127 "CCC" 65131 "DI" 65136 "CVW" 65144 "TP1" 65145 "TP2" 65146 "TP3" 65195 "ETC6" 65196 "EBC4" 65199 "GFC" 65201 "EH" 65202 "GFI1" 65203 "LFI1" 65208 "GTFI" 65212 "CBI" 65214 "EEC4" 65216 "SERV" 65219 "ETC5" 65221 "ETC4" 65223 "ETC3" 65227 "DM02" 65228 "DM03" 65229 "DM04" 65230 "DM05" 65231 "DM06" 65234 "DM10" 65235 "DM11" 65236 "DM12" 65242 "SOFT" 65244 "IO" 65248 "VD" 65250 "TCFG" 65253 "HOURS" 65254 "TD" 65255 "VH" 65256 "VDS" 65257 "LFC1" 65258 "VW" 65259 "CI" 65260 "VI" 65261 "CCSS" 65284 "PB_DriversConsentOnPersonalData" 65376 "VehCfg" 65413 "PB_3CT" 65482 "PB_ID1" 65484 "PB_VNS" 65502 "Av2" 65520 "SCh" 65521 "DIS" 65524 "PB_IVA" ;
VAL_ 2565406503 CtrlByte_Ackm_18E8FF27 0 "ACK" 1 "NACK" 2 "Access Denied" 3 "Cannot Respond" ;
VAL_ 2565406503 Pgn_Ack_18E8FF27 37120 "VLSI1" 40448 "DM29" 41216 "DM33" 41728 "DM31" 41984 "DM30" 47360 "PLLT(PlanListLifetime)" 47872 "PLD(PlanListDistance)" 49408 "DM21" 49664 "DM20" 49920 "DM22" 53504 "MaintBcIc" 54016 "DM19" 60928 "ACL" 61184 "STOD" 64342 "HVESP3CFG" 64344 "HVESP2CFG" 64346 "HVESP1CFG" 64529 "TGFI" 64579 "TCSI" 64582 "TSIS" 64583 "MTI" 64605 "HVESSCFG" 64606 "HVESSHIST" 64653 "PII" 64701 "A1SCRSI2" 64782 "AT1OGC2" 64784 "AT1IGC2" 64839 "TML" 64879 "EEC8" 64896 "DM28" 64905 "VDS2" 64906 "J2012" 64912 "AETC" 64920 "AT1HI1" 64949 "DM23" 64950 "DM24" 64951 "DM25" 64952 "DM26" 64953 "TPRI" 64965 "ECUID" 64981 "EEC5" 65039 "LC" 65099 "TCFG2" 65109 "GFD" 65127 "CCC" 65131 "DI" 65136 "CVW" 65144 "TP1" 65145 "TP2" 65146 "TP3" 65195 "ETC6" 65196 "EBC4" 65199 "GFC" 65201 "EH" 65202 "GFI1" 65203 "LFI1" 65208 "GTFI" 65212 "CBI" 65214 "EEC4" 65216 "SERV" 65219 "ETC5" 65221 "ETC4" 65223 "ETC3" 65227 "DM02" 65228 "DM03" 65229 "DM04" 65230 "DM05" 65231 "DM06" 65234 "DM10" 65235 "DM11" 65236 "DM12" 65242 "SOFT" 65244 "IO" 65248 "VD" 65250 "TCFG" 65253 "HOURS" 65254 "TD" 65255 "VH" 65256 "VDS" 65257 "LFC1" 65258 "VW" 65259 "CI" 65260 "VI" 65261 "CCSS" 65284 "PB_DriversConsentOnPersonalData" 65376 "VehCfg" 65413 "PB_3CT" 65482 "PB_ID1" 65484 "PB_VNS" 65502 "Av2" 65520 "SCh" 65521 "DIS" 65524 "PB_IVA" ;
VAL_ 2565406503 Pgn_Nack_18E8FF27 37120 "VLSI1" 40448 "DM29" 41216 "DM33" 41728 "DM31" 41984 "DM30" 47360 "PLLT(PlanListLifetime)" 47872 "PLD(PlanListDistance)" 49408 "DM21" 49664 "DM20" 49920 "DM22" 53504 "MaintBcIc" 54016 "DM19" 60928 "ACL" 61184 "STOD" 64342 "HVESP3CFG" 64344 "HVESP2CFG" 64346 "HVESP1CFG" 64529 "TGFI" 64579 "TCSI" 64582 "TSIS" 64583 "MTI" 64605 "HVESSCFG" 64606 "HVESSHIST" 64653 "PII" 64701 "A1SCRSI2" 64782 "AT1OGC2" 64784 "AT1IGC2" 64839 "TML" 64879 "EEC8" 64896 "DM28" 64905 "VDS2" 64906 "J2012" 64912 "AETC" 64920 "AT1HI1" 64949 "DM23" 64950 "DM24" 64951 "DM25" 64952 "DM26" 64953 "TPRI" 64965 "ECUID" 64981 "EEC5" 65039 "LC" 65099 "TCFG2" 65109 "GFD" 65127 "CCC" 65131 "DI" 65136 "CVW" 65144 "TP1" 65145 "TP2" 65146 "TP3" 65195 "ETC6" 65196 "EBC4" 65199 "GFC" 65201 "EH" 65202 "GFI1" 65203 "LFI1" 65208 "GTFI" 65212 "CBI" 65214 "EEC4" 65216 "SERV" 65219 "ETC5" 65221 "ETC4" 65223 "ETC3" 65227 "DM02" 65228 "DM03" 65229 "DM04" 65230 "DM05" 65231 "DM06" 65234 "DM10" 65235 "DM11" 65236 "DM12" 65242 "SOFT" 65244 "IO" 65248 "VD" 65250 "TCFG" 65253 "HOURS" 65254 "TD" 65255 "VH" 65256 "VDS" 65257 "LFC1" 65258 "VW" 65259 "CI" 65260 "VI" 65261 "CCSS" 65284 "PB_DriversConsentOnPersonalData" 65376 "VehCfg" 65413 "PB_3CT" 65482 "PB_ID1" 65484 "PB_VNS" 65502 "Av2" 65520 "SCh" 65521 "DIS" 65524 "PB_IVA" ;
VAL_ 2565406503 Pgn_Ad_18E8FF27 37120 "VLSI1" 40448 "DM29" 41216 "DM33" 41728 "DM31" 41984 "DM30" 47360 "PLLT(PlanListLifetime)" 47872 "PLD(PlanListDistance)" 49408 "DM21" 49664 "DM20" 49920 "DM22" 53504 "MaintBcIc" 54016 "DM19" 60928 "ACL" 61184 "STOD" 64342 "HVESP3CFG" 64344 "HVESP2CFG" 64346 "HVESP1CFG" 64529 "TGFI" 64579 "TCSI" 64582 "TSIS" 64583 "MTI" 64605 "HVESSCFG" 64606 "HVESSHIST" 64653 "PII" 64701 "A1SCRSI2" 64782 "AT1OGC2" 64784 "AT1IGC2" 64839 "TML" 64879 "EEC8" 64896 "DM28" 64905 "VDS2" 64906 "J2012" 64912 "AETC" 64920 "AT1HI1" 64949 "DM23" 64950 "DM24" 64951 "DM25" 64952 "DM26" 64953 "TPRI" 64965 "ECUID" 64981 "EEC5" 65039 "LC" 65099 "TCFG2" 65109 "GFD" 65127 "CCC" 65131 "DI" 65136 "CVW" 65144 "TP1" 65145 "TP2" 65146 "TP3" 65195 "ETC6" 65196 "EBC4" 65199 "GFC" 65201 "EH" 65202 "GFI1" 65203 "LFI1" 65208 "GTFI" 65212 "CBI" 65214 "EEC4" 65216 "SERV" 65219 "ETC5" 65221 "ETC4" 65223 "ETC3" 65227 "DM02" 65228 "DM03" 65229 "DM04" 65230 "DM05" 65231 "DM06" 65234 "DM10" 65235 "DM11" 65236 "DM12" 65242 "SOFT" 65244 "IO" 65248 "VD" 65250 "TCFG" 65253 "HOURS" 65254 "TD" 65255 "VH" 65256 "VDS" 65257 "LFC1" 65258 "VW" 65259 "CI" 65260 "VI" 65261 "CCSS" 65284 "PB_DriversConsentOnPersonalData" 65376 "VehCfg" 65413 "PB_3CT" 65482 "PB_ID1" 65484 "PB_VNS" 65502 "Av2" 65520 "SCh" 65521 "DIS" 65524 "PB_IVA" ;
VAL_ 2565406503 Pgn_Busy_18E8FF27 37120 "VLSI1" 40448 "DM29" 41216 "DM33" 41728 "DM31" 41984 "DM30" 47360 "PLLT(PlanListLifetime)" 47872 "PLD(PlanListDistance)" 49408 "DM21" 49664 "DM20" 49920 "DM22" 53504 "MaintBcIc" 54016 "DM19" 60928 "ACL" 61184 "STOD" 64342 "HVESP3CFG" 64344 "HVESP2CFG" 64346 "HVESP1CFG" 64529 "TGFI" 64579 "TCSI" 64582 "TSIS" 64583 "MTI" 64605 "HVESSCFG" 64606 "HVESSHIST" 64653 "PII" 64701 "A1SCRSI2" 64782 "AT1OGC2" 64784 "AT1IGC2" 64839 "TML" 64879 "EEC8" 64896 "DM28" 64905 "VDS2" 64906 "J2012" 64912 "AETC" 64920 "AT1HI1" 64949 "DM23" 64950 "DM24" 64951 "DM25" 64952 "DM26" 64953 "TPRI" 64965 "ECUID" 64981 "EEC5" 65039 "LC" 65099 "TCFG2" 65109 "GFD" 65127 "CCC" 65131 "DI" 65136 "CVW" 65144 "TP1" 65145 "TP2" 65146 "TP3" 65195 "ETC6" 65196 "EBC4" 65199 "GFC" 65201 "EH" 65202 "GFI1" 65203 "LFI1" 65208 "GTFI" 65212 "CBI" 65214 "EEC4" 65216 "SERV" 65219 "ETC5" 65221 "ETC4" 65223 "ETC3" 65227 "DM02" 65228 "DM03" 65229 "DM04" 65230 "DM05" 65231 "DM06" 65234 "DM10" 65235 "DM11" 65236 "DM12" 65242 "SOFT" 65244 "IO" 65248 "VD" 65250 "TCFG" 65253 "HOURS" 65254 "TD" 65255 "VH" 65256 "VDS" 65257 "LFC1" 65258 "VW" 65259 "CI" 65260 "VI" 65261 "CCSS" 65284 "PB_DriversConsentOnPersonalData" 65376 "VehCfg" 65413 "PB_3CT" 65482 "PB_ID1" 65484 "PB_VNS" 65502 "Av2" 65520 "SCh" 65521 "DIS" 65524 "PB_IVA" ;
VAL_ 2565406515 CtrlByte_Ackm_18E8FF33 0 "ACK" 1 "NACK" 2 "Access Denied" 3 "Cannot Respond" ;
VAL_ 2565406515 Pgn_Ack_18E8FF33 37120 "VLSI1" 40448 "DM29" 41216 "DM33" 41728 "DM31" 41984 "DM30" 47360 "PLLT(PlanListLifetime)" 47872 "PLD(PlanListDistance)" 49408 "DM21" 49664 "DM20" 49920 "DM22" 53504 "MaintBcIc" 54016 "DM19" 60928 "ACL" 61184 "STOD" 64342 "HVESP3CFG" 64344 "HVESP2CFG" 64346 "HVESP1CFG" 64529 "TGFI" 64579 "TCSI" 64582 "TSIS" 64583 "MTI" 64605 "HVESSCFG" 64606 "HVESSHIST" 64653 "PII" 64701 "A1SCRSI2" 64782 "AT1OGC2" 64784 "AT1IGC2" 64839 "TML" 64879 "EEC8" 64896 "DM28" 64905 "VDS2" 64906 "J2012" 64912 "AETC" 64920 "AT1HI1" 64949 "DM23" 64950 "DM24" 64951 "DM25" 64952 "DM26" 64953 "TPRI" 64965 "ECUID" 64981 "EEC5" 65039 "LC" 65099 "TCFG2" 65109 "GFD" 65127 "CCC" 65131 "DI" 65136 "CVW" 65144 "TP1" 65145 "TP2" 65146 "TP3" 65195 "ETC6" 65196 "EBC4" 65199 "GFC" 65201 "EH" 65202 "GFI1" 65203 "LFI1" 65208 "GTFI" 65212 "CBI" 65214 "EEC4" 65216 "SERV" 65219 "ETC5" 65221 "ETC4" 65223 "ETC3" 65227 "DM02" 65228 "DM03" 65229 "DM04" 65230 "DM05" 65231 "DM06" 65234 "DM10" 65235 "DM11" 65236 "DM12" 65242 "SOFT" 65244 "IO" 65248 "VD" 65250 "TCFG" 65253 "HOURS" 65254 "TD" 65255 "VH" 65256 "VDS" 65257 "LFC1" 65258 "VW" 65259 "CI" 65260 "VI" 65261 "CCSS" 65284 "PB_DriversConsentOnPersonalData" 65376 "VehCfg" 65413 "PB_3CT" 65482 "PB_ID1" 65484 "PB_VNS" 65502 "Av2" 65520 "SCh" 65521 "DIS" 65524 "PB_IVA" ;
VAL_ 2565406515 Pgn_Nack_18E8FF33 37120 "VLSI1" 40448 "DM29" 41216 "DM33" 41728 "DM31" 41984 "DM30" 47360 "PLLT(PlanListLifetime)" 47872 "PLD(PlanListDistance)" 49408 "DM21" 49664 "DM20" 49920 "DM22" 53504 "MaintBcIc" 54016 "DM19" 60928 "ACL" 61184 "STOD" 64342 "HVESP3CFG" 64344 "HVESP2CFG" 64346 "HVESP1CFG" 64529 "TGFI" 64579 "TCSI" 64582 "TSIS" 64583 "MTI" 64605 "HVESSCFG" 64606 "HVESSHIST" 64653 "PII" 64701 "A1SCRSI2" 64782 "AT1OGC2" 64784 "AT1IGC2" 64839 "TML" 64879 "EEC8" 64896 "DM28" 64905 "VDS2" 64906 "J2012" 64912 "AETC" 64920 "AT1HI1" 64949 "DM23" 64950 "DM24" 64951 "DM25" 64952 "DM26" 64953 "TPRI" 64965 "ECUID" 64981 "EEC5" 65039 "LC" 65099 "TCFG2" 65109 "GFD" 65127 "CCC" 65131 "DI" 65136 "CVW" 65144 "TP1" 65145 "TP2" 65146 "TP3" 65195 "ETC6" 65196 "EBC4" 65199 "GFC" 65201 "EH" 65202 "GFI1" 65203 "LFI1" 65208 "GTFI" 65212 "CBI" 65214 "EEC4" 65216 "SERV" 65219 "ETC5" 65221 "ETC4" 65223 "ETC3" 65227 "DM02" 65228 "DM03" 65229 "DM04" 65230 "DM05" 65231 "DM06" 65234 "DM10" 65235 "DM11" 65236 "DM12" 65242 "SOFT" 65244 "IO" 65248 "VD" 65250 "TCFG" 65253 "HOURS" 65254 "TD" 65255 "VH" 65256 "VDS" 65257 "LFC1" 65258 "VW" 65259 "CI" 65260 "VI" 65261 "CCSS" 65284 "PB_DriversConsentOnPersonalData" 65376 "VehCfg" 65413 "PB_3CT" 65482 "PB_ID1" 65484 "PB_VNS" 65502 "Av2" 65520 "SCh" 65521 "DIS" 65524 "PB_IVA" ;
VAL_ 2565406515 Pgn_Ad_18E8FF33 37120 "VLSI1" 40448 "DM29" 41216 "DM33" 41728 "DM31" 41984 "DM30" 47360 "PLLT(PlanListLifetime)" 47872 "PLD(PlanListDistance)" 49408 "DM21" 49664 "DM20" 49920 "DM22" 53504 "MaintBcIc" 54016 "DM19" 60928 "ACL" 61184 "STOD" 64342 "HVESP3CFG" 64344 "HVESP2CFG" 64346 "HVESP1CFG" 64529 "TGFI" 64579 "TCSI" 64582 "TSIS" 64583 "MTI" 64605 "HVESSCFG" 64606 "HVESSHIST" 64653 "PII" 64701 "A1SCRSI2" 64782 "AT1OGC2" 64784 "AT1IGC2" 64839 "TML" 64879 "EEC8" 64896 "DM28" 64905 "VDS2" 64906 "J2012" 64912 "AETC" 64920 "AT1HI1" 64949 "DM23" 64950 "DM24" 64951 "DM25" 64952 "DM26" 64953 "TPRI" 64965 "ECUID" 64981 "EEC5" 65039 "LC" 65099 "TCFG2" 65109 "GFD" 65127 "CCC" 65131 "DI" 65136 "CVW" 65144 "TP1" 65145 "TP2" 65146 "TP3" 65195 "ETC6" 65196 "EBC4" 65199 "GFC" 65201 "EH" 65202 "GFI1" 65203 "LFI1" 65208 "GTFI" 65212 "CBI" 65214 "EEC4" 65216 "SERV" 65219 "ETC5" 65221 "ETC4" 65223 "ETC3" 65227 "DM02" 65228 "DM03" 65229 "DM04" 65230 "DM05" 65231 "DM06" 65234 "DM10" 65235 "DM11" 65236 "DM12" 65242 "SOFT" 65244 "IO" 65248 "VD" 65250 "TCFG" 65253 "HOURS" 65254 "TD" 65255 "VH" 65256 "VDS" 65257 "LFC1" 65258 "VW" 65259 "CI" 65260 "VI" 65261 "CCSS" 65284 "PB_DriversConsentOnPersonalData" 65376 "VehCfg" 65413 "PB_3CT" 65482 "PB_ID1" 65484 "PB_VNS" 65502 "Av2" 65520 "SCh" 65521 "DIS" 65524 "PB_IVA" ;
VAL_ 2565406515 Pgn_Busy_18E8FF33 37120 "VLSI1" 40448 "DM29" 41216 "DM33" 41728 "DM31" 41984 "DM30" 47360 "PLLT(PlanListLifetime)" 47872 "PLD(PlanListDistance)" 49408 "DM21" 49664 "DM20" 49920 "DM22" 53504 "MaintBcIc" 54016 "DM19" 60928 "ACL" 61184 "STOD" 64342 "HVESP3CFG" 64344 "HVESP2CFG" 64346 "HVESP1CFG" 64529 "TGFI" 64579 "TCSI" 64582 "TSIS" 64583 "MTI" 64605 "HVESSCFG" 64606 "HVESSHIST" 64653 "PII" 64701 "A1SCRSI2" 64782 "AT1OGC2" 64784 "AT1IGC2" 64839 "TML" 64879 "EEC8" 64896 "DM28" 64905 "VDS2" 64906 "J2012" 64912 "AETC" 64920 "AT1HI1" 64949 "DM23" 64950 "DM24" 64951 "DM25" 64952 "DM26" 64953 "TPRI" 64965 "ECUID" 64981 "EEC5" 65039 "LC" 65099 "TCFG2" 65109 "GFD" 65127 "CCC" 65131 "DI" 65136 "CVW" 65144 "TP1" 65145 "TP2" 65146 "TP3" 65195 "ETC6" 65196 "EBC4" 65199 "GFC" 65201 "EH" 65202 "GFI1" 65203 "LFI1" 65208 "GTFI" 65212 "CBI" 65214 "EEC4" 65216 "SERV" 65219 "ETC5" 65221 "ETC4" 65223 "ETC3" 65227 "DM02" 65228 "DM03" 65229 "DM04" 65230 "DM05" 65231 "DM06" 65234 "DM10" 65235 "DM11" 65236 "DM12" 65242 "SOFT" 65244 "IO" 65248 "VD" 65250 "TCFG" 65253 "HOURS" 65254 "TD" 65255 "VH" 65256 "VDS" 65257 "LFC1" 65258 "VW" 65259 "CI" 65260 "VI" 65261 "CCSS" 65284 "PB_DriversConsentOnPersonalData" 65376 "VehCfg" 65413 "PB_3CT" 65482 "PB_ID1" 65484 "PB_VNS" 65502 "Av2" 65520 "SCh" 65521 "DIS" 65524 "PB_IVA" ;
VAL_ 2565406520 CtrlByte_Ackm_18E8FF38 0 "ACK" 1 "NACK" 2 "Access Denied" 3 "Cannot Respond" ;
VAL_ 2565406520 Pgn_Ack_18E8FF38 37120 "VLSI1" 40448 "DM29" 41216 "DM33" 41728 "DM31" 41984 "DM30" 47360 "PLLT(PlanListLifetime)" 47872 "PLD(PlanListDistance)" 49408 "DM21" 49664 "DM20" 49920 "DM22" 53504 "MaintBcIc" 54016 "DM19" 60928 "ACL" 61184 "STOD" 64342 "HVESP3CFG" 64344 "HVESP2CFG" 64346 "HVESP1CFG" 64529 "TGFI" 64579 "TCSI" 64582 "TSIS" 64583 "MTI" 64605 "HVESSCFG" 64606 "HVESSHIST" 64653 "PII" 64701 "A1SCRSI2" 64782 "AT1OGC2" 64784 "AT1IGC2" 64839 "TML" 64879 "EEC8" 64896 "DM28" 64905 "VDS2" 64906 "J2012" 64912 "AETC" 64920 "AT1HI1" 64949 "DM23" 64950 "DM24" 64951 "DM25" 64952 "DM26" 64953 "TPRI" 64965 "ECUID" 64981 "EEC5" 65039 "LC" 65099 "TCFG2" 65109 "GFD" 65127 "CCC" 65131 "DI" 65136 "CVW" 65144 "TP1" 65145 "TP2" 65146 "TP3" 65195 "ETC6" 65196 "EBC4" 65199 "GFC" 65201 "EH" 65202 "GFI1" 65203 "LFI1" 65208 "GTFI" 65212 "CBI" 65214 "EEC4" 65216 "SERV" 65219 "ETC5" 65221 "ETC4" 65223 "ETC3" 65227 "DM02" 65228 "DM03" 65229 "DM04" 65230 "DM05" 65231 "DM06" 65234 "DM10" 65235 "DM11" 65236 "DM12" 65242 "SOFT" 65244 "IO" 65248 "VD" 65250 "TCFG" 65253 "HOURS" 65254 "TD" 65255 "VH" 65256 "VDS" 65257 "LFC1" 65258 "VW" 65259 "CI" 65260 "VI" 65261 "CCSS" 65284 "PB_DriversConsentOnPersonalData" 65376 "VehCfg" 65413 "PB_3CT" 65482 "PB_ID1" 65484 "PB_VNS" 65502 "Av2" 65520 "SCh" 65521 "DIS" 65524 "PB_IVA" ;
VAL_ 2565406520 Pgn_Nack_18E8FF38 37120 "VLSI1" 40448 "DM29" 41216 "DM33" 41728 "DM31" 41984 "DM30" 47360 "PLLT(PlanListLifetime)" 47872 "PLD(PlanListDistance)" 49408 "DM21" 49664 "DM20" 49920 "DM22" 53504 "MaintBcIc" 54016 "DM19" 60928 "ACL" 61184 "STOD" 64342 "HVESP3CFG" 64344 "HVESP2CFG" 64346 "HVESP1CFG" 64529 "TGFI" 64579 "TCSI" 64582 "TSIS" 64583 "MTI" 64605 "HVESSCFG" 64606 "HVESSHIST" 64653 "PII" 64701 "A1SCRSI2" 64782 "AT1OGC2" 64784 "AT1IGC2" 64839 "TML" 64879 "EEC8" 64896 "DM28" 64905 "VDS2" 64906 "J2012" 64912 "AETC" 64920 "AT1HI1" 64949 "DM23" 64950 "DM24" 64951 "DM25" 64952 "DM26" 64953 "TPRI" 64965 "ECUID" 64981 "EEC5" 65039 "LC" 65099 "TCFG2" 65109 "GFD" 65127 "CCC" 65131 "DI" 65136 "CVW" 65144 "TP1" 65145 "TP2" 65146 "TP3" 65195 "ETC6" 65196 "EBC4" 65199 "GFC" 65201 "EH" 65202 "GFI1" 65203 "LFI1" 65208 "GTFI" 65212 "CBI" 65214 "EEC4" 65216 "SERV" 65219 "ETC5" 65221 "ETC4" 65223 "ETC3" 65227 "DM02" 65228 "DM03" 65229 "DM04" 65230 "DM05" 65231 "DM06" 65234 "DM10" 65235 "DM11" 65236 "DM12" 65242 "SOFT" 65244 "IO" 65248 "VD" 65250 "TCFG" 65253 "HOURS" 65254 "TD" 65255 "VH" 65256 "VDS" 65257 "LFC1" 65258 "VW" 65259 "CI" 65260 "VI" 65261 "CCSS" 65284 "PB_DriversConsentOnPersonalData" 65376 "VehCfg" 65413 "PB_3CT" 65482 "PB_ID1" 65484 "PB_VNS" 65502 "Av2" 65520 "SCh" 65521 "DIS" 65524 "PB_IVA" ;
VAL_ 2565406520 Pgn_Ad_18E8FF38 37120 "VLSI1" 40448 "DM29" 41216 "DM33" 41728 "DM31" 41984 "DM30" 47360 "PLLT(PlanListLifetime)" 47872 "PLD(PlanListDistance)" 49408 "DM21" 49664 "DM20" 49920 "DM22" 53504 "MaintBcIc" 54016 "DM19" 60928 "ACL" 61184 "STOD" 64342 "HVESP3CFG" 64344 "HVESP2CFG" 64346 "HVESP1CFG" 64529 "TGFI" 64579 "TCSI" 64582 "TSIS" 64583 "MTI" 64605 "HVESSCFG" 64606 "HVESSHIST" 64653 "PII" 64701 "A1SCRSI2" 64782 "AT1OGC2" 64784 "AT1IGC2" 64839 "TML" 64879 "EEC8" 64896 "DM28" 64905 "VDS2" 64906 "J2012" 64912 "AETC" 64920 "AT1HI1" 64949 "DM23" 64950 "DM24" 64951 "DM25" 64952 "DM26" 64953 "TPRI" 64965 "ECUID" 64981 "EEC5" 65039 "LC" 65099 "TCFG2" 65109 "GFD" 65127 "CCC" 65131 "DI" 65136 "CVW" 65144 "TP1" 65145 "TP2" 65146 "TP3" 65195 "ETC6" 65196 "EBC4" 65199 "GFC" 65201 "EH" 65202 "GFI1" 65203 "LFI1" 65208 "GTFI" 65212 "CBI" 65214 "EEC4" 65216 "SERV" 65219 "ETC5" 65221 "ETC4" 65223 "ETC3" 65227 "DM02" 65228 "DM03" 65229 "DM04" 65230 "DM05" 65231 "DM06" 65234 "DM10" 65235 "DM11" 65236 "DM12" 65242 "SOFT" 65244 "IO" 65248 "VD" 65250 "TCFG" 65253 "HOURS" 65254 "TD" 65255 "VH" 65256 "VDS" 65257 "LFC1" 65258 "VW" 65259 "CI" 65260 "VI" 65261 "CCSS" 65284 "PB_DriversConsentOnPersonalData" 65376 "VehCfg" 65413 "PB_3CT" 65482 "PB_ID1" 65484 "PB_VNS" 65502 "Av2" 65520 "SCh" 65521 "DIS" 65524 "PB_IVA" ;
VAL_ 2565406520 Pgn_Busy_18E8FF38 37120 "VLSI1" 40448 "DM29" 41216 "DM33" 41728 "DM31" 41984 "DM30" 47360 "PLLT(PlanListLifetime)" 47872 "PLD(PlanListDistance)" 49408 "DM21" 49664 "DM20" 49920 "DM22" 53504 "MaintBcIc" 54016 "DM19" 60928 "ACL" 61184 "STOD" 64342 "HVESP3CFG" 64344 "HVESP2CFG" 64346 "HVESP1CFG" 64529 "TGFI" 64579 "TCSI" 64582 "TSIS" 64583 "MTI" 64605 "HVESSCFG" 64606 "HVESSHIST" 64653 "PII" 64701 "A1SCRSI2" 64782 "AT1OGC2" 64784 "AT1IGC2" 64839 "TML" 64879 "EEC8" 64896 "DM28" 64905 "VDS2" 64906 "J2012" 64912 "AETC" 64920 "AT1HI1" 64949 "DM23" 64950 "DM24" 64951 "DM25" 64952 "DM26" 64953 "TPRI" 64965 "ECUID" 64981 "EEC5" 65039 "LC" 65099 "TCFG2" 65109 "GFD" 65127 "CCC" 65131 "DI" 65136 "CVW" 65144 "TP1" 65145 "TP2" 65146 "TP3" 65195 "ETC6" 65196 "EBC4" 65199 "GFC" 65201 "EH" 65202 "GFI1" 65203 "LFI1" 65208 "GTFI" 65212 "CBI" 65214 "EEC4" 65216 "SERV" 65219 "ETC5" 65221 "ETC4" 65223 "ETC3" 65227 "DM02" 65228 "DM03" 65229 "DM04" 65230 "DM05" 65231 "DM06" 65234 "DM10" 65235 "DM11" 65236 "DM12" 65242 "SOFT" 65244 "IO" 65248 "VD" 65250 "TCFG" 65253 "HOURS" 65254 "TD" 65255 "VH" 65256 "VDS" 65257 "LFC1" 65258 "VW" 65259 "CI" 65260 "VI" 65261 "CCSS" 65284 "PB_DriversConsentOnPersonalData" 65376 "VehCfg" 65413 "PB_3CT" 65482 "PB_ID1" 65484 "PB_VNS" 65502 "Av2" 65520 "SCh" 65521 "DIS" 65524 "PB_IVA" ;
VAL_ 2565406590 CtrlByte_Ackm_18E8FF7E 0 "ACK" 1 "NACK" 2 "Access Denied" 3 "Cannot Respond" ;
VAL_ 2565406590 Pgn_Ack_18E8FF7E 37120 "VLSI1" 40448 "DM29" 41216 "DM33" 41728 "DM31" 41984 "DM30" 47360 "PLLT(PlanListLifetime)" 47872 "PLD(PlanListDistance)" 49408 "DM21" 49664 "DM20" 49920 "DM22" 53504 "MaintBcIc" 54016 "DM19" 60928 "ACL" 61184 "STOD" 64342 "HVESP3CFG" 64344 "HVESP2CFG" 64346 "HVESP1CFG" 64529 "TGFI" 64579 "TCSI" 64582 "TSIS" 64583 "MTI" 64605 "HVESSCFG" 64606 "HVESSHIST" 64653 "PII" 64701 "A1SCRSI2" 64782 "AT1OGC2" 64784 "AT1IGC2" 64839 "TML" 64879 "EEC8" 64896 "DM28" 64905 "VDS2" 64906 "J2012" 64912 "AETC" 64920 "AT1HI1" 64949 "DM23" 64950 "DM24" 64951 "DM25" 64952 "DM26" 64953 "TPRI" 64965 "ECUID" 64981 "EEC5" 65039 "LC" 65099 "TCFG2" 65109 "GFD" 65127 "CCC" 65131 "DI" 65136 "CVW" 65144 "TP1" 65145 "TP2" 65146 "TP3" 65195 "ETC6" 65196 "EBC4" 65199 "GFC" 65201 "EH" 65202 "GFI1" 65203 "LFI1" 65208 "GTFI" 65212 "CBI" 65214 "EEC4" 65216 "SERV" 65219 "ETC5" 65221 "ETC4" 65223 "ETC3" 65227 "DM02" 65228 "DM03" 65229 "DM04" 65230 "DM05" 65231 "DM06" 65234 "DM10" 65235 "DM11" 65236 "DM12" 65242 "SOFT" 65244 "IO" 65248 "VD" 65250 "TCFG" 65253 "HOURS" 65254 "TD" 65255 "VH" 65256 "VDS" 65257 "LFC1" 65258 "VW" 65259 "CI" 65260 "VI" 65261 "CCSS" 65284 "PB_DriversConsentOnPersonalData" 65376 "VehCfg" 65413 "PB_3CT" 65482 "PB_ID1" 65484 "PB_VNS" 65502 "Av2" 65520 "SCh" 65521 "DIS" 65524 "PB_IVA" ;
VAL_ 2565406590 Pgn_Nack_18E8FF7E 37120 "VLSI1" 40448 "DM29" 41216 "DM33" 41728 "DM31" 41984 "DM30" 47360 "PLLT(PlanListLifetime)" 47872 "PLD(PlanListDistance)" 49408 "DM21" 49664 "DM20" 49920 "DM22" 53504 "MaintBcIc" 54016 "DM19" 60928 "ACL" 61184 "STOD" 64342 "HVESP3CFG" 64344 "HVESP2CFG" 64346 "HVESP1CFG" 64529 "TGFI" 64579 "TCSI" 64582 "TSIS" 64583 "MTI" 64605 "HVESSCFG" 64606 "HVESSHIST" 64653 "PII" 64701 "A1SCRSI2" 64782 "AT1OGC2" 64784 "AT1IGC2" 64839 "TML" 64879 "EEC8" 64896 "DM28" 64905 "VDS2" 64906 "J2012" 64912 "AETC" 64920 "AT1HI1" 64949 "DM23" 64950 "DM24" 64951 "DM25" 64952 "DM26" 64953 "TPRI" 64965 "ECUID" 64981 "EEC5" 65039 "LC" 65099 "TCFG2" 65109 "GFD" 65127 "CCC" 65131 "DI" 65136 "CVW" 65144 "TP1" 65145 "TP2" 65146 "TP3" 65195 "ETC6" 65196 "EBC4" 65199 "GFC" 65201 "EH" 65202 "GFI1" 65203 "LFI1" 65208 "GTFI" 65212 "CBI" 65214 "EEC4" 65216 "SERV" 65219 "ETC5" 65221 "ETC4" 65223 "ETC3" 65227 "DM02" 65228 "DM03" 65229 "DM04" 65230 "DM05" 65231 "DM06" 65234 "DM10" 65235 "DM11" 65236 "DM12" 65242 "SOFT" 65244 "IO" 65248 "VD" 65250 "TCFG" 65253 "HOURS" 65254 "TD" 65255 "VH" 65256 "VDS" 65257 "LFC1" 65258 "VW" 65259 "CI" 65260 "VI" 65261 "CCSS" 65284 "PB_DriversConsentOnPersonalData" 65376 "VehCfg" 65413 "PB_3CT" 65482 "PB_ID1" 65484 "PB_VNS" 65502 "Av2" 65520 "SCh" 65521 "DIS" 65524 "PB_IVA" ;
VAL_ 2565406590 Pgn_Ad_18E8FF7E 37120 "VLSI1" 40448 "DM29" 41216 "DM33" 41728 "DM31" 41984 "DM30" 47360 "PLLT(PlanListLifetime)" 47872 "PLD(PlanListDistance)" 49408 "DM21" 49664 "DM20" 49920 "DM22" 53504 "MaintBcIc" 54016 "DM19" 60928 "ACL" 61184 "STOD" 64342 "HVESP3CFG" 64344 "HVESP2CFG" 64346 "HVESP1CFG" 64529 "TGFI" 64579 "TCSI" 64582 "TSIS" 64583 "MTI" 64605 "HVESSCFG" 64606 "HVESSHIST" 64653 "PII" 64701 "A1SCRSI2" 64782 "AT1OGC2" 64784 "AT1IGC2" 64839 "TML" 64879 "EEC8" 64896 "DM28" 64905 "VDS2" 64906 "J2012" 64912 "AETC" 64920 "AT1HI1" 64949 "DM23" 64950 "DM24" 64951 "DM25" 64952 "DM26" 64953 "TPRI" 64965 "ECUID" 64981 "EEC5" 65039 "LC" 65099 "TCFG2" 65109 "GFD" 65127 "CCC" 65131 "DI" 65136 "CVW" 65144 "TP1" 65145 "TP2" 65146 "TP3" 65195 "ETC6" 65196 "EBC4" 65199 "GFC" 65201 "EH" 65202 "GFI1" 65203 "LFI1" 65208 "GTFI" 65212 "CBI" 65214 "EEC4" 65216 "SERV" 65219 "ETC5" 65221 "ETC4" 65223 "ETC3" 65227 "DM02" 65228 "DM03" 65229 "DM04" 65230 "DM05" 65231 "DM06" 65234 "DM10" 65235 "DM11" 65236 "DM12" 65242 "SOFT" 65244 "IO" 65248 "VD" 65250 "TCFG" 65253 "HOURS" 65254 "TD" 65255 "VH" 65256 "VDS" 65257 "LFC1" 65258 "VW" 65259 "CI" 65260 "VI" 65261 "CCSS" 65284 "PB_DriversConsentOnPersonalData" 65376 "VehCfg" 65413 "PB_3CT" 65482 "PB_ID1" 65484 "PB_VNS" 65502 "Av2" 65520 "SCh" 65521 "DIS" 65524 "PB_IVA" ;
VAL_ 2565406590 Pgn_Busy_18E8FF7E 37120 "VLSI1" 40448 "DM29" 41216 "DM33" 41728 "DM31" 41984 "DM30" 47360 "PLLT(PlanListLifetime)" 47872 "PLD(PlanListDistance)" 49408 "DM21" 49664 "DM20" 49920 "DM22" 53504 "MaintBcIc" 54016 "DM19" 60928 "ACL" 61184 "STOD" 64342 "HVESP3CFG" 64344 "HVESP2CFG" 64346 "HVESP1CFG" 64529 "TGFI" 64579 "TCSI" 64582 "TSIS" 64583 "MTI" 64605 "HVESSCFG" 64606 "HVESSHIST" 64653 "PII" 64701 "A1SCRSI2" 64782 "AT1OGC2" 64784 "AT1IGC2" 64839 "TML" 64879 "EEC8" 64896 "DM28" 64905 "VDS2" 64906 "J2012" 64912 "AETC" 64920 "AT1HI1" 64949 "DM23" 64950 "DM24" 64951 "DM25" 64952 "DM26" 64953 "TPRI" 64965 "ECUID" 64981 "EEC5" 65039 "LC" 65099 "TCFG2" 65109 "GFD" 65127 "CCC" 65131 "DI" 65136 "CVW" 65144 "TP1" 65145 "TP2" 65146 "TP3" 65195 "ETC6" 65196 "EBC4" 65199 "GFC" 65201 "EH" 65202 "GFI1" 65203 "LFI1" 65208 "GTFI" 65212 "CBI" 65214 "EEC4" 65216 "SERV" 65219 "ETC5" 65221 "ETC4" 65223 "ETC3" 65227 "DM02" 65228 "DM03" 65229 "DM04" 65230 "DM05" 65231 "DM06" 65234 "DM10" 65235 "DM11" 65236 "DM12" 65242 "SOFT" 65244 "IO" 65248 "VD" 65250 "TCFG" 65253 "HOURS" 65254 "TD" 65255 "VH" 65256 "VDS" 65257 "LFC1" 65258 "VW" 65259 "CI" 65260 "VI" 65261 "CCSS" 65284 "PB_DriversConsentOnPersonalData" 65376 "VehCfg" 65413 "PB_3CT" 65482 "PB_ID1" 65484 "PB_VNS" 65502 "Av2" 65520 "SCh" 65521 "DIS" 65524 "PB_IVA" ;
VAL_ 2565406622 CtrlByte_Ackm_18E8FF9E 0 "ACK" 1 "NACK" 2 "Access Denied" 3 "Cannot Respond" ;
VAL_ 2565406622 Pgn_Ack_18E8FF9E 37120 "VLSI1" 40448 "DM29" 41216 "DM33" 41728 "DM31" 41984 "DM30" 47360 "PLLT(PlanListLifetime)" 47872 "PLD(PlanListDistance)" 49408 "DM21" 49664 "DM20" 49920 "DM22" 53504 "MaintBcIc" 54016 "DM19" 60928 "ACL" 61184 "STOD" 64342 "HVESP3CFG" 64344 "HVESP2CFG" 64346 "HVESP1CFG" 64529 "TGFI" 64579 "TCSI" 64582 "TSIS" 64583 "MTI" 64605 "HVESSCFG" 64606 "HVESSHIST" 64653 "PII" 64701 "A1SCRSI2" 64782 "AT1OGC2" 64784 "AT1IGC2" 64839 "TML" 64879 "EEC8" 64896 "DM28" 64905 "VDS2" 64906 "J2012" 64912 "AETC" 64920 "AT1HI1" 64949 "DM23" 64950 "DM24" 64951 "DM25" 64952 "DM26" 64953 "TPRI" 64965 "ECUID" 64981 "EEC5" 65039 "LC" 65099 "TCFG2" 65109 "GFD" 65127 "CCC" 65131 "DI" 65136 "CVW" 65144 "TP1" 65145 "TP2" 65146 "TP3" 65195 "ETC6" 65196 "EBC4" 65199 "GFC" 65201 "EH" 65202 "GFI1" 65203 "LFI1" 65208 "GTFI" 65212 "CBI" 65214 "EEC4" 65216 "SERV" 65219 "ETC5" 65221 "ETC4" 65223 "ETC3" 65227 "DM02" 65228 "DM03" 65229 "DM04" 65230 "DM05" 65231 "DM06" 65234 "DM10" 65235 "DM11" 65236 "DM12" 65242 "SOFT" 65244 "IO" 65248 "VD" 65250 "TCFG" 65253 "HOURS" 65254 "TD" 65255 "VH" 65256 "VDS" 65257 "LFC1" 65258 "VW" 65259 "CI" 65260 "VI" 65261 "CCSS" 65284 "PB_DriversConsentOnPersonalData" 65376 "VehCfg" 65413 "PB_3CT" 65482 "PB_ID1" 65484 "PB_VNS" 65502 "Av2" 65520 "SCh" 65521 "DIS" 65524 "PB_IVA" ;
VAL_ 2565406622 Pgn_Nack_18E8FF9E 37120 "VLSI1" 40448 "DM29" 41216 "DM33" 41728 "DM31" 41984 "DM30" 47360 "PLLT(PlanListLifetime)" 47872 "PLD(PlanListDistance)" 49408 "DM21" 49664 "DM20" 49920 "DM22" 53504 "MaintBcIc" 54016 "DM19" 60928 "ACL" 61184 "STOD" 64342 "HVESP3CFG" 64344 "HVESP2CFG" 64346 "HVESP1CFG" 64529 "TGFI" 64579 "TCSI" 64582 "TSIS" 64583 "MTI" 64605 "HVESSCFG" 64606 "HVESSHIST" 64653 "PII" 64701 "A1SCRSI2" 64782 "AT1OGC2" 64784 "AT1IGC2" 64839 "TML" 64879 "EEC8" 64896 "DM28" 64905 "VDS2" 64906 "J2012" 64912 "AETC" 64920 "AT1HI1" 64949 "DM23" 64950 "DM24" 64951 "DM25" 64952 "DM26" 64953 "TPRI" 64965 "ECUID" 64981 "EEC5" 65039 "LC" 65099 "TCFG2" 65109 "GFD" 65127 "CCC" 65131 "DI" 65136 "CVW" 65144 "TP1" 65145 "TP2" 65146 "TP3" 65195 "ETC6" 65196 "EBC4" 65199 "GFC" 65201 "EH" 65202 "GFI1" 65203 "LFI1" 65208 "GTFI" 65212 "CBI" 65214 "EEC4" 65216 "SERV" 65219 "ETC5" 65221 "ETC4" 65223 "ETC3" 65227 "DM02" 65228 "DM03" 65229 "DM04" 65230 "DM05" 65231 "DM06" 65234 "DM10" 65235 "DM11" 65236 "DM12" 65242 "SOFT" 65244 "IO" 65248 "VD" 65250 "TCFG" 65253 "HOURS" 65254 "TD" 65255 "VH" 65256 "VDS" 65257 "LFC1" 65258 "VW" 65259 "CI" 65260 "VI" 65261 "CCSS" 65284 "PB_DriversConsentOnPersonalData" 65376 "VehCfg" 65413 "PB_3CT" 65482 "PB_ID1" 65484 "PB_VNS" 65502 "Av2" 65520 "SCh" 65521 "DIS" 65524 "PB_IVA" ;
VAL_ 2565406622 Pgn_Ad_18E8FF9E 37120 "VLSI1" 40448 "DM29" 41216 "DM33" 41728 "DM31" 41984 "DM30" 47360 "PLLT(PlanListLifetime)" 47872 "PLD(PlanListDistance)" 49408 "DM21" 49664 "DM20" 49920 "DM22" 53504 "MaintBcIc" 54016 "DM19" 60928 "ACL" 61184 "STOD" 64342 "HVESP3CFG" 64344 "HVESP2CFG" 64346 "HVESP1CFG" 64529 "TGFI" 64579 "TCSI" 64582 "TSIS" 64583 "MTI" 64605 "HVESSCFG" 64606 "HVESSHIST" 64653 "PII" 64701 "A1SCRSI2" 64782 "AT1OGC2" 64784 "AT1IGC2" 64839 "TML" 64879 "EEC8" 64896 "DM28" 64905 "VDS2" 64906 "J2012" 64912 "AETC" 64920 "AT1HI1" 64949 "DM23" 64950 "DM24" 64951 "DM25" 64952 "DM26" 64953 "TPRI" 64965 "ECUID" 64981 "EEC5" 65039 "LC" 65099 "TCFG2" 65109 "GFD" 65127 "CCC" 65131 "DI" 65136 "CVW" 65144 "TP1" 65145 "TP2" 65146 "TP3" 65195 "ETC6" 65196 "EBC4" 65199 "GFC" 65201 "EH" 65202 "GFI1" 65203 "LFI1" 65208 "GTFI" 65212 "CBI" 65214 "EEC4" 65216 "SERV" 65219 "ETC5" 65221 "ETC4" 65223 "ETC3" 65227 "DM02" 65228 "DM03" 65229 "DM04" 65230 "DM05" 65231 "DM06" 65234 "DM10" 65235 "DM11" 65236 "DM12" 65242 "SOFT" 65244 "IO" 65248 "VD" 65250 "TCFG" 65253 "HOURS" 65254 "TD" 65255 "VH" 65256 "VDS" 65257 "LFC1" 65258 "VW" 65259 "CI" 65260 "VI" 65261 "CCSS" 65284 "PB_DriversConsentOnPersonalData" 65376 "VehCfg" 65413 "PB_3CT" 65482 "PB_ID1" 65484 "PB_VNS" 65502 "Av2" 65520 "SCh" 65521 "DIS" 65524 "PB_IVA" ;
VAL_ 2565406622 Pgn_Busy_18E8FF9E 37120 "VLSI1" 40448 "DM29" 41216 "DM33" 41728 "DM31" 41984 "DM30" 47360 "PLLT(PlanListLifetime)" 47872 "PLD(PlanListDistance)" 49408 "DM21" 49664 "DM20" 49920 "DM22" 53504 "MaintBcIc" 54016 "DM19" 60928 "ACL" 61184 "STOD" 64342 "HVESP3CFG" 64344 "HVESP2CFG" 64346 "HVESP1CFG" 64529 "TGFI" 64579 "TCSI" 64582 "TSIS" 64583 "MTI" 64605 "HVESSCFG" 64606 "HVESSHIST" 64653 "PII" 64701 "A1SCRSI2" 64782 "AT1OGC2" 64784 "AT1IGC2" 64839 "TML" 64879 "EEC8" 64896 "DM28" 64905 "VDS2" 64906 "J2012" 64912 "AETC" 64920 "AT1HI1" 64949 "DM23" 64950 "DM24" 64951 "DM25" 64952 "DM26" 64953 "TPRI" 64965 "ECUID" 64981 "EEC5" 65039 "LC" 65099 "TCFG2" 65109 "GFD" 65127 "CCC" 65131 "DI" 65136 "CVW" 65144 "TP1" 65145 "TP2" 65146 "TP3" 65195 "ETC6" 65196 "EBC4" 65199 "GFC" 65201 "EH" 65202 "GFI1" 65203 "LFI1" 65208 "GTFI" 65212 "CBI" 65214 "EEC4" 65216 "SERV" 65219 "ETC5" 65221 "ETC4" 65223 "ETC3" 65227 "DM02" 65228 "DM03" 65229 "DM04" 65230 "DM05" 65231 "DM06" 65234 "DM10" 65235 "DM11" 65236 "DM12" 65242 "SOFT" 65244 "IO" 65248 "VD" 65250 "TCFG" 65253 "HOURS" 65254 "TD" 65255 "VH" 65256 "VDS" 65257 "LFC1" 65258 "VW" 65259 "CI" 65260 "VI" 65261 "CCSS" 65284 "PB_DriversConsentOnPersonalData" 65376 "VehCfg" 65413 "PB_3CT" 65482 "PB_ID1" 65484 "PB_VNS" 65502 "Av2" 65520 "SCh" 65521 "DIS" 65524 "PB_IVA" ;
VAL_ 2565406624 CtrlByte_Ackm_18E8FFA0 0 "ACK" 1 "NACK" 2 "Access Denied" 3 "Cannot Respond" ;
VAL_ 2565406624 Pgn_Ack_18E8FFA0 37120 "VLSI1" 40448 "DM29" 41216 "DM33" 41728 "DM31" 41984 "DM30" 47360 "PLLT(PlanListLifetime)" 47872 "PLD(PlanListDistance)" 49408 "DM21" 49664 "DM20" 49920 "DM22" 53504 "MaintBcIc" 54016 "DM19" 60928 "ACL" 61184 "STOD" 64342 "HVESP3CFG" 64344 "HVESP2CFG" 64346 "HVESP1CFG" 64529 "TGFI" 64579 "TCSI" 64582 "TSIS" 64583 "MTI" 64605 "HVESSCFG" 64606 "HVESSHIST" 64653 "PII" 64701 "A1SCRSI2" 64782 "AT1OGC2" 64784 "AT1IGC2" 64839 "TML" 64879 "EEC8" 64896 "DM28" 64905 "VDS2" 64906 "J2012" 64912 "AETC" 64920 "AT1HI1" 64949 "DM23" 64950 "DM24" 64951 "DM25" 64952 "DM26" 64953 "TPRI" 64965 "ECUID" 64981 "EEC5" 65039 "LC" 65099 "TCFG2" 65109 "GFD" 65127 "CCC" 65131 "DI" 65136 "CVW" 65144 "TP1" 65145 "TP2" 65146 "TP3" 65195 "ETC6" 65196 "EBC4" 65199 "GFC" 65201 "EH" 65202 "GFI1" 65203 "LFI1" 65208 "GTFI" 65212 "CBI" 65214 "EEC4" 65216 "SERV" 65219 "ETC5" 65221 "ETC4" 65223 "ETC3" 65227 "DM02" 65228 "DM03" 65229 "DM04" 65230 "DM05" 65231 "DM06" 65234 "DM10" 65235 "DM11" 65236 "DM12" 65242 "SOFT" 65244 "IO" 65248 "VD" 65250 "TCFG" 65253 "HOURS" 65254 "TD" 65255 "VH" 65256 "VDS" 65257 "LFC1" 65258 "VW" 65259 "CI" 65260 "VI" 65261 "CCSS" 65284 "PB_DriversConsentOnPersonalData" 65376 "VehCfg" 65413 "PB_3CT" 65482 "PB_ID1" 65484 "PB_VNS" 65502 "Av2" 65520 "SCh" 65521 "DIS" 65524 "PB_IVA" ;
VAL_ 2565406624 Pgn_Nack_18E8FFA0 37120 "VLSI1" 40448 "DM29" 41216 "DM33" 41728 "DM31" 41984 "DM30" 47360 "PLLT(PlanListLifetime)" 47872 "PLD(PlanListDistance)" 49408 "DM21" 49664 "DM20" 49920 "DM22" 53504 "MaintBcIc" 54016 "DM19" 60928 "ACL" 61184 "STOD" 64342 "HVESP3CFG" 64344 "HVESP2CFG" 64346 "HVESP1CFG" 64529 "TGFI" 64579 "TCSI" 64582 "TSIS" 64583 "MTI" 64605 "HVESSCFG" 64606 "HVESSHIST" 64653 "PII" 64701 "A1SCRSI2" 64782 "AT1OGC2" 64784 "AT1IGC2" 64839 "TML" 64879 "EEC8" 64896 "DM28" 64905 "VDS2" 64906 "J2012" 64912 "AETC" 64920 "AT1HI1" 64949 "DM23" 64950 "DM24" 64951 "DM25" 64952 "DM26" 64953 "TPRI" 64965 "ECUID" 64981 "EEC5" 65039 "LC" 65099 "TCFG2" 65109 "GFD" 65127 "CCC" 65131 "DI" 65136 "CVW" 65144 "TP1" 65145 "TP2" 65146 "TP3" 65195 "ETC6" 65196 "EBC4" 65199 "GFC" 65201 "EH" 65202 "GFI1" 65203 "LFI1" 65208 "GTFI" 65212 "CBI" 65214 "EEC4" 65216 "SERV" 65219 "ETC5" 65221 "ETC4" 65223 "ETC3" 65227 "DM02" 65228 "DM03" 65229 "DM04" 65230 "DM05" 65231 "DM06" 65234 "DM10" 65235 "DM11" 65236 "DM12" 65242 "SOFT" 65244 "IO" 65248 "VD" 65250 "TCFG" 65253 "HOURS" 65254 "TD" 65255 "VH" 65256 "VDS" 65257 "LFC1" 65258 "VW" 65259 "CI" 65260 "VI" 65261 "CCSS" 65284 "PB_DriversConsentOnPersonalData" 65376 "VehCfg" 65413 "PB_3CT" 65482 "PB_ID1" 65484 "PB_VNS" 65502 "Av2" 65520 "SCh" 65521 "DIS" 65524 "PB_IVA" ;
VAL_ 2565406624 Pgn_Ad_18E8FFA0 37120 "VLSI1" 40448 "DM29" 41216 "DM33" 41728 "DM31" 41984 "DM30" 47360 "PLLT(PlanListLifetime)" 47872 "PLD(PlanListDistance)" 49408 "DM21" 49664 "DM20" 49920 "DM22" 53504 "MaintBcIc" 54016 "DM19" 60928 "ACL" 61184 "STOD" 64342 "HVESP3CFG" 64344 "HVESP2CFG" 64346 "HVESP1CFG" 64529 "TGFI" 64579 "TCSI" 64582 "TSIS" 64583 "MTI" 64605 "HVESSCFG" 64606 "HVESSHIST" 64653 "PII" 64701 "A1SCRSI2" 64782 "AT1OGC2" 64784 "AT1IGC2" 64839 "TML" 64879 "EEC8" 64896 "DM28" 64905 "VDS2" 64906 "J2012" 64912 "AETC" 64920 "AT1HI1" 64949 "DM23" 64950 "DM24" 64951 "DM25" 64952 "DM26" 64953 "TPRI" 64965 "ECUID" 64981 "EEC5" 65039 "LC" 65099 "TCFG2" 65109 "GFD" 65127 "CCC" 65131 "DI" 65136 "CVW" 65144 "TP1" 65145 "TP2" 65146 "TP3" 65195 "ETC6" 65196 "EBC4" 65199 "GFC" 65201 "EH" 65202 "GFI1" 65203 "LFI1" 65208 "GTFI" 65212 "CBI" 65214 "EEC4" 65216 "SERV" 65219 "ETC5" 65221 "ETC4" 65223 "ETC3" 65227 "DM02" 65228 "DM03" 65229 "DM04" 65230 "DM05" 65231 "DM06" 65234 "DM10" 65235 "DM11" 65236 "DM12" 65242 "SOFT" 65244 "IO" 65248 "VD" 65250 "TCFG" 65253 "HOURS" 65254 "TD" 65255 "VH" 65256 "VDS" 65257 "LFC1" 65258 "VW" 65259 "CI" 65260 "VI" 65261 "CCSS" 65284 "PB_DriversConsentOnPersonalData" 65376 "VehCfg" 65413 "PB_3CT" 65482 "PB_ID1" 65484 "PB_VNS" 65502 "Av2" 65520 "SCh" 65521 "DIS" 65524 "PB_IVA" ;
VAL_ 2565406624 Pgn_Busy_18E8FFA0 37120 "VLSI1" 40448 "DM29" 41216 "DM33" 41728 "DM31" 41984 "DM30" 47360 "PLLT(PlanListLifetime)" 47872 "PLD(PlanListDistance)" 49408 "DM21" 49664 "DM20" 49920 "DM22" 53504 "MaintBcIc" 54016 "DM19" 60928 "ACL" 61184 "STOD" 64342 "HVESP3CFG" 64344 "HVESP2CFG" 64346 "HVESP1CFG" 64529 "TGFI" 64579 "TCSI" 64582 "TSIS" 64583 "MTI" 64605 "HVESSCFG" 64606 "HVESSHIST" 64653 "PII" 64701 "A1SCRSI2" 64782 "AT1OGC2" 64784 "AT1IGC2" 64839 "TML" 64879 "EEC8" 64896 "DM28" 64905 "VDS2" 64906 "J2012" 64912 "AETC" 64920 "AT1HI1" 64949 "DM23" 64950 "DM24" 64951 "DM25" 64952 "DM26" 64953 "TPRI" 64965 "ECUID" 64981 "EEC5" 65039 "LC" 65099 "TCFG2" 65109 "GFD" 65127 "CCC" 65131 "DI" 65136 "CVW" 65144 "TP1" 65145 "TP2" 65146 "TP3" 65195 "ETC6" 65196 "EBC4" 65199 "GFC" 65201 "EH" 65202 "GFI1" 65203 "LFI1" 65208 "GTFI" 65212 "CBI" 65214 "EEC4" 65216 "SERV" 65219 "ETC5" 65221 "ETC4" 65223 "ETC3" 65227 "DM02" 65228 "DM03" 65229 "DM04" 65230 "DM05" 65231 "DM06" 65234 "DM10" 65235 "DM11" 65236 "DM12" 65242 "SOFT" 65244 "IO" 65248 "VD" 65250 "TCFG" 65253 "HOURS" 65254 "TD" 65255 "VH" 65256 "VDS" 65257 "LFC1" 65258 "VW" 65259 "CI" 65260 "VI" 65261 "CCSS" 65284 "PB_DriversConsentOnPersonalData" 65376 "VehCfg" 65413 "PB_3CT" 65482 "PB_ID1" 65484 "PB_VNS" 65502 "Av2" 65520 "SCh" 65521 "DIS" 65524 "PB_IVA" ;
VAL_ 2565406702 CtrlByte_Ackm_18E8FFEE 0 "ACK" 1 "NACK" 2 "Access Denied" 3 "Cannot Respond" ;
VAL_ 2565406702 Pgn_Ack_18E8FFEE 37120 "VLSI1" 40448 "DM29" 41216 "DM33" 41728 "DM31" 41984 "DM30" 47360 "PLLT(PlanListLifetime)" 47872 "PLD(PlanListDistance)" 49408 "DM21" 49664 "DM20" 49920 "DM22" 53504 "MaintBcIc" 54016 "DM19" 60928 "ACL" 61184 "STOD" 64342 "HVESP3CFG" 64344 "HVESP2CFG" 64346 "HVESP1CFG" 64529 "TGFI" 64579 "TCSI" 64582 "TSIS" 64583 "MTI" 64605 "HVESSCFG" 64606 "HVESSHIST" 64653 "PII" 64701 "A1SCRSI2" 64782 "AT1OGC2" 64784 "AT1IGC2" 64839 "TML" 64879 "EEC8" 64896 "DM28" 64905 "VDS2" 64906 "J2012" 64912 "AETC" 64920 "AT1HI1" 64949 "DM23" 64950 "DM24" 64951 "DM25" 64952 "DM26" 64953 "TPRI" 64965 "ECUID" 64981 "EEC5" 65039 "LC" 65099 "TCFG2" 65109 "GFD" 65127 "CCC" 65131 "DI" 65136 "CVW" 65144 "TP1" 65145 "TP2" 65146 "TP3" 65195 "ETC6" 65196 "EBC4" 65199 "GFC" 65201 "EH" 65202 "GFI1" 65203 "LFI1" 65208 "GTFI" 65212 "CBI" 65214 "EEC4" 65216 "SERV" 65219 "ETC5" 65221 "ETC4" 65223 "ETC3" 65227 "DM02" 65228 "DM03" 65229 "DM04" 65230 "DM05" 65231 "DM06" 65234 "DM10" 65235 "DM11" 65236 "DM12" 65242 "SOFT" 65244 "IO" 65248 "VD" 65250 "TCFG" 65253 "HOURS" 65254 "TD" 65255 "VH" 65256 "VDS" 65257 "LFC1" 65258 "VW" 65259 "CI" 65260 "VI" 65261 "CCSS" 65284 "PB_DriversConsentOnPersonalData" 65376 "VehCfg" 65413 "PB_3CT" 65482 "PB_ID1" 65484 "PB_VNS" 65502 "Av2" 65520 "SCh" 65521 "DIS" 65524 "PB_IVA" ;
VAL_ 2565406702 Pgn_Nack_18E8FFEE 37120 "VLSI1" 40448 "DM29" 41216 "DM33" 41728 "DM31" 41984 "DM30" 47360 "PLLT(PlanListLifetime)" 47872 "PLD(PlanListDistance)" 49408 "DM21" 49664 "DM20" 49920 "DM22" 53504 "MaintBcIc" 54016 "DM19" 60928 "ACL" 61184 "STOD" 64342 "HVESP3CFG" 64344 "HVESP2CFG" 64346 "HVESP1CFG" 64529 "TGFI" 64579 "TCSI" 64582 "TSIS" 64583 "MTI" 64605 "HVESSCFG" 64606 "HVESSHIST" 64653 "PII" 64701 "A1SCRSI2" 64782 "AT1OGC2" 64784 "AT1IGC2" 64839 "TML" 64879 "EEC8" 64896 "DM28" 64905 "VDS2" 64906 "J2012" 64912 "AETC" 64920 "AT1HI1" 64949 "DM23" 64950 "DM24" 64951 "DM25" 64952 "DM26" 64953 "TPRI" 64965 "ECUID" 64981 "EEC5" 65039 "LC" 65099 "TCFG2" 65109 "GFD" 65127 "CCC" 65131 "DI" 65136 "CVW" 65144 "TP1" 65145 "TP2" 65146 "TP3" 65195 "ETC6" 65196 "EBC4" 65199 "GFC" 65201 "EH" 65202 "GFI1" 65203 "LFI1" 65208 "GTFI" 65212 "CBI" 65214 "EEC4" 65216 "SERV" 65219 "ETC5" 65221 "ETC4" 65223 "ETC3" 65227 "DM02" 65228 "DM03" 65229 "DM04" 65230 "DM05" 65231 "DM06" 65234 "DM10" 65235 "DM11" 65236 "DM12" 65242 "SOFT" 65244 "IO" 65248 "VD" 65250 "TCFG" 65253 "HOURS" 65254 "TD" 65255 "VH" 65256 "VDS" 65257 "LFC1" 65258 "VW" 65259 "CI" 65260 "VI" 65261 "CCSS" 65284 "PB_DriversConsentOnPersonalData" 65376 "VehCfg" 65413 "PB_3CT" 65482 "PB_ID1" 65484 "PB_VNS" 65502 "Av2" 65520 "SCh" 65521 "DIS" 65524 "PB_IVA" ;
VAL_ 2565406702 Pgn_Ad_18E8FFEE 37120 "VLSI1" 40448 "DM29" 41216 "DM33" 41728 "DM31" 41984 "DM30" 47360 "PLLT(PlanListLifetime)" 47872 "PLD(PlanListDistance)" 49408 "DM21" 49664 "DM20" 49920 "DM22" 53504 "MaintBcIc" 54016 "DM19" 60928 "ACL" 61184 "STOD" 64342 "HVESP3CFG" 64344 "HVESP2CFG" 64346 "HVESP1CFG" 64529 "TGFI" 64579 "TCSI" 64582 "TSIS" 64583 "MTI" 64605 "HVESSCFG" 64606 "HVESSHIST" 64653 "PII" 64701 "A1SCRSI2" 64782 "AT1OGC2" 64784 "AT1IGC2" 64839 "TML" 64879 "EEC8" 64896 "DM28" 64905 "VDS2" 64906 "J2012" 64912 "AETC" 64920 "AT1HI1" 64949 "DM23" 64950 "DM24" 64951 "DM25" 64952 "DM26" 64953 "TPRI" 64965 "ECUID" 64981 "EEC5" 65039 "LC" 65099 "TCFG2" 65109 "GFD" 65127 "CCC" 65131 "DI" 65136 "CVW" 65144 "TP1" 65145 "TP2" 65146 "TP3" 65195 "ETC6" 65196 "EBC4" 65199 "GFC" 65201 "EH" 65202 "GFI1" 65203 "LFI1" 65208 "GTFI" 65212 "CBI" 65214 "EEC4" 65216 "SERV" 65219 "ETC5" 65221 "ETC4" 65223 "ETC3" 65227 "DM02" 65228 "DM03" 65229 "DM04" 65230 "DM05" 65231 "DM06" 65234 "DM10" 65235 "DM11" 65236 "DM12" 65242 "SOFT" 65244 "IO" 65248 "VD" 65250 "TCFG" 65253 "HOURS" 65254 "TD" 65255 "VH" 65256 "VDS" 65257 "LFC1" 65258 "VW" 65259 "CI" 65260 "VI" 65261 "CCSS" 65284 "PB_DriversConsentOnPersonalData" 65376 "VehCfg" 65413 "PB_3CT" 65482 "PB_ID1" 65484 "PB_VNS" 65502 "Av2" 65520 "SCh" 65521 "DIS" 65524 "PB_IVA" ;
VAL_ 2565406702 Pgn_Busy_18E8FFEE 37120 "VLSI1" 40448 "DM29" 41216 "DM33" 41728 "DM31" 41984 "DM30" 47360 "PLLT(PlanListLifetime)" 47872 "PLD(PlanListDistance)" 49408 "DM21" 49664 "DM20" 49920 "DM22" 53504 "MaintBcIc" 54016 "DM19" 60928 "ACL" 61184 "STOD" 64342 "HVESP3CFG" 64344 "HVESP2CFG" 64346 "HVESP1CFG" 64529 "TGFI" 64579 "TCSI" 64582 "TSIS" 64583 "MTI" 64605 "HVESSCFG" 64606 "HVESSHIST" 64653 "PII" 64701 "A1SCRSI2" 64782 "AT1OGC2" 64784 "AT1IGC2" 64839 "TML" 64879 "EEC8" 64896 "DM28" 64905 "VDS2" 64906 "J2012" 64912 "AETC" 64920 "AT1HI1" 64949 "DM23" 64950 "DM24" 64951 "DM25" 64952 "DM26" 64953 "TPRI" 64965 "ECUID" 64981 "EEC5" 65039 "LC" 65099 "TCFG2" 65109 "GFD" 65127 "CCC" 65131 "DI" 65136 "CVW" 65144 "TP1" 65145 "TP2" 65146 "TP3" 65195 "ETC6" 65196 "EBC4" 65199 "GFC" 65201 "EH" 65202 "GFI1" 65203 "LFI1" 65208 "GTFI" 65212 "CBI" 65214 "EEC4" 65216 "SERV" 65219 "ETC5" 65221 "ETC4" 65223 "ETC3" 65227 "DM02" 65228 "DM03" 65229 "DM04" 65230 "DM05" 65231 "DM06" 65234 "DM10" 65235 "DM11" 65236 "DM12" 65242 "SOFT" 65244 "IO" 65248 "VD" 65250 "TCFG" 65253 "HOURS" 65254 "TD" 65255 "VH" 65256 "VDS" 65257 "LFC1" 65258 "VW" 65259 "CI" 65260 "VI" 65261 "CCSS" 65284 "PB_DriversConsentOnPersonalData" 65376 "VehCfg" 65413 "PB_3CT" 65482 "PB_ID1" 65484 "PB_VNS" 65502 "Av2" 65520 "SCh" 65521 "DIS" 65524 "PB_IVA" ;
VAL_ 2633959399 FunctLamp 0 "Lamp_NotActive" 1 "Lamp_Active" 2 "Error" 3 "SNA" ;
VAL_ 2633959399 StopLamp 0 "Lamp_NotActive" 1 "Lamp_Active" 2 "Error" 3 "SNA" ;
VAL_ 2364551072 AebsSts 0 "Not ready" 1 "Temporarily not available" 2 "Deactivated by driver" 3 "Ready" 4 "Driver overrides system" 5 "Collision warning active" 6 "Collision warning with braking" 7 "Emergency braking active" 8 "Perf. / sensitivity limited" 9 "Reserved" 10 "Reserved" 11 "Reserved" 12 "Reserved" 13 "Reserved" 14 "Error indication" 15 "Not Available / Not installed" ;
VAL_ 2349572119 DrivActvDemForAebs 0 "Deactivation of system" 1 "No deactivation of system" 2 "Reserved" 3 "Don’t' care / Take no action" ;
VAL_ 2566827553 AirSuspSupplyPrs1 254 "Error" 255 "Not_available" ;
VAL_ 2566827553 AirComprSts 0 "Compressor not active" 1 "Compressor active" 2 "Error indicator" 3 "Not Available" ;
VAL_ 2566620766 CAID2Sts 2 "ProtocolValidatReqByNBM" 176 "Error" 240 "ShutDownReqByNBM" ;
VAL_ 2566620766 CAID2EngStartRollingSit 83 "AutorizedStart_Byte3" 172 "AutorizedStart_Byte2" ;
VAL_ 2566620766 Data4 0 "NoError" 1 "GeneralError" 2 "SelftestError" 3 "AlcoholInterlockNoFunct" 4 "CommunicationError" 85 "Acknowledge" 133 "NotAknowledge" ;
VAL_ 2566620766 Data6 18 "Rev50436_4_2020" ;
VAL_ 2566620766 Data7 64 "CAN J1939" ;
VAL_ 2566845696 BaromPrs 254 "Error" 255 "Not_available" ;
VAL_ 2566845696 AmbAirTemp 65534 "Error" 65535 "Not_available" ;
VAL_ 2566845696 EngIn1AirTemp 254 "Error" 255 "Not_available" ;
VAL_ 2566845719 AmbAirTemp_18FEF517 65534 "Error" 65535 "Not_available" ;
VAL_ 2566837527 Altern1Sts 0 "Not charging" 1 "Charging" 2 "Error" 3 "Not Available" ;
VAL_ 2566837527 Altern2Sts 0 "Not charging" 1 "Charging" 2 "Error" 3 "Not Available" ;
VAL_ 2566837527 Altern3Sts 0 "Not charging" 1 "Charging" 2 "Error" 3 "Not Available" ;
VAL_ 2365479471 KneelInfo 0 "Not active" 1 "Lowering active" 2 "Kneeling level reached" 3 "Lifting active" 4 "Kneeling aborted" 5 "Not defined" 6 "Not defined" 13 "Not defined" 14 "Error" 15 "Not Available" ;
VAL_ 2365479488 KneelInfo_0CFE5A40 0 "Not active" 1 "Lowering active" 2 "Kneeling level reached" 3 "Lifting active" 4 "Kneeling aborted" 5 "Not defined" 6 "Not defined" 13 "Not defined" 14 "Error" 15 "Not Available" ;
VAL_ 2566804992 At1DefTankVol 251 "No valid measurement" ;
VAL_ 2566804992 AtScrOpInducSev 0 "No Inducement Active" 1 "Level 1" 2 "Level 2" 3 "Level 3" 4 "Level 4" 5 "Level 5" 6 "Temporary Override of Inducement" 7 "Not Available / Not Supported" ;
VAL_ 2566849271 PulseEna 0 "Pulses not enabled" 1 "Pulses enabled" 2 "Reserved" 3 "Not available" ;
VAL_ 2566849271 ErrSts 0 "No error" 1 "Error" 2 "Reserved" 3 "Not available" ;
VAL_ 2566849015 PulseEna_18FF01F7 0 "Pulses not enabled" 1 "Pulses enabled" 2 "Reserved" 3 "Not available" ;
VAL_ 2566849015 ErrSts_18FF01F7 0 "No error" 1 "Error" 2 "Reserved" 3 "Not available" ;
VAL_ 2566848759 Term15Sts 0 "Terminal 15 off" 1 "Terminal 15 on" 2 "Reserved" 3 "Not available" ;
VAL_ 2566849270 PulseEna_18FF02F6 0 "Pulses not enabled" 1 "Pulses enabled" 2 "Reserved" 3 "Not available" ;
VAL_ 2566849270 ErrSts_18FF02F6 0 "No error" 1 "Error" 2 "Reserved" 3 "Not available" ;
